VERSION ""

NS_ :

BS_:

BU_: DSAU vHS_M SHVU_RR DPSS AMP ICC RLPSM APSM RWPC RRHV RRPSM CGW_CCU APSS ATS RLHV FPM RDC PSM ASAU

BO_ 2563125249 HU_AMP_E_01_1: 8 CGW_CCU
 SG_ AMP_Beep2Mode : 12|2@1- (1,0) [0|0] ""  Vector__XXX
 SG_ AMP_Beep1Mode : 14|2@1+ (1,0) [0|0] ""  AMP,ATS
 SG_ AMP_MasterBeepVolumeStep : 16|3@1+ (1,0) [0|0] ""  AMP
 SG_ AMP_RrTTSSound : 2|2@1+ (1,0) [0|0] ""  AMP
 SG_ AMP_ASDMode : 21|3@1+ (1,0) [0|0] ""  AMP
 SG_ AMP_ANCMode : 25|2@1+ (1,0) [0|0] ""  AMP
 SG_ AMP_VirtualVenueMode : 32|3@1+ (1,0) [0|0] ""  AMP
 SG_ AMP_QLIMode : 35|3@1+ (1,0) [0|0] ""  AMP
 SG_ AMP_DriverMode : 38|2@1+ (1,0) [0|0] ""  AMP
 SG_ AMP_NaviSound : 4|2@1+ (1,0) [0|0] ""  AMP
 SG_ AMP_VESSMixing : 40|2@1+ (1,0) [0|0] ""  Vector__XXX
 SG_ AMP_VESSMusicOut : 42|2@1+ (1,0) [0|0] ""  Vector__XXX
 SG_ AMP_VoiceGuideTTS : 44|2@1+ (1,0) [0|0] ""  AMP
 SG_ AMP_Beep1KBDMode : 46|2@1+ (1,0) [0|0] ""  AMP
 SG_ AMP_VoiceGuideTTSLevel : 48|3@1+ (1,0) [0|0] ""  AMP
 SG_ AMP_ALTPopUpReq : 54|2@1+ (1,0) [0|0] ""  AMP
 SG_ AMP_TTSSound : 6|2@1+ (1,0) [0|0] ""  AMP
 SG_ AMP_SDVCStep : 9|3@1+ (1,0) [0|0] ""  AMP

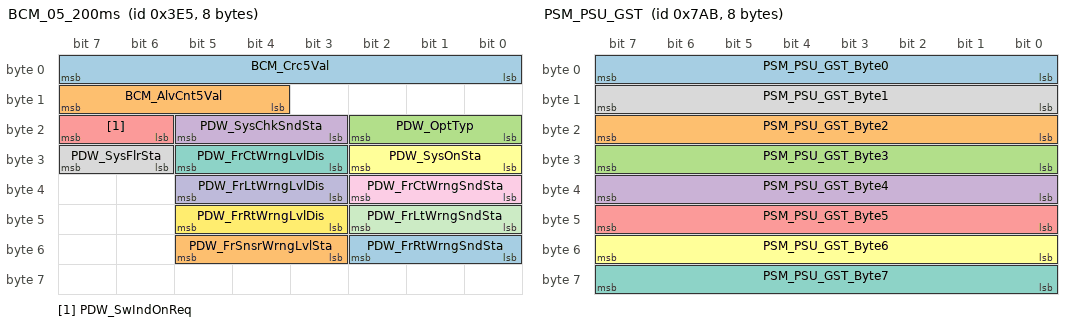
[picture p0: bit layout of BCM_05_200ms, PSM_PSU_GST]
BO_ 997 BCM_05_200ms: 8 CGW_CCU
 SG_ BCM_Crc5Val : 0|8@1+ (1,0) [0|0] ""  Vector__XXX
 SG_ BCM_AlvCnt5Val : 12|4@1+ (1,0) [0|0] ""  Vector__XXX
 SG_ PDW_OptTyp : 16|3@1+ (1,0) [0|0] ""  Vector__XXX
 SG_ PDW_SysChkSndSta : 19|3@1+ (1,0) [0|0] ""  Vector__XXX
 SG_ PDW_SwIndOnReq : 22|2@1+ (1,0) [0|0] ""  Vector__XXX
 SG_ PDW_SysOnSta : 24|3@1+ (1,0) [0|0] ""  Vector__XXX
 SG_ PDW_FrCtWrngLvlDis : 27|3@1+ (1,0) [0|0] ""  Vector__XXX
 SG_ PDW_SysFlrSta : 30|2@1+ (1,0) [0|0] ""  Vector__XXX
 SG_ PDW_FrCtWrngSndSta : 32|3@1+ (1,0) [0|0] ""  AMP
 SG_ PDW_FrLtWrngLvlDis : 35|3@1+ (1,0) [0|0] ""  Vector__XXX
 SG_ PDW_FrLtWrngSndSta : 40|3@1+ (1,0) [0|0] ""  AMP
 SG_ PDW_FrRtWrngLvlDis : 43|3@1+ (1,0) [0|0] ""  Vector__XXX
 SG_ PDW_FrRtWrngSndSta : 48|3@1+ (1,0) [0|0] ""  AMP
 SG_ PDW_FrSnsrWrngLvlSta : 51|3@1+ (1,0) [0|0] ""  Vector__XXX

BO_ 1963 PSM_PSU_GST: 8 PSM
 SG_ PSM_PSU_GST_Byte0 : 0|8@1+ (1,0) [0|0] ""  CGW_CCU
 SG_ PSM_PSU_GST_Byte2 : 16|8@1+ (1,0) [0|0] ""  CGW_CCU
 SG_ PSM_PSU_GST_Byte3 : 24|8@1+ (1,0) [0|0] ""  CGW_CCU
 SG_ PSM_PSU_GST_Byte4 : 32|8@1+ (1,0) [0|0] ""  CGW_CCU
 SG_ PSM_PSU_GST_Byte5 : 40|8@1+ (1,0) [0|0] ""  CGW_CCU
 SG_ PSM_PSU_GST_Byte6 : 48|8@1+ (1,0) [0|0] ""  CGW_CCU
 SG_ PSM_PSU_GST_Byte7 : 56|8@1+ (1,0) [0|0] ""  CGW_CCU
 SG_ PSM_PSU_GST_Byte1 : 8|8@1+ (1,0) [0|0] ""  CGW_CCU

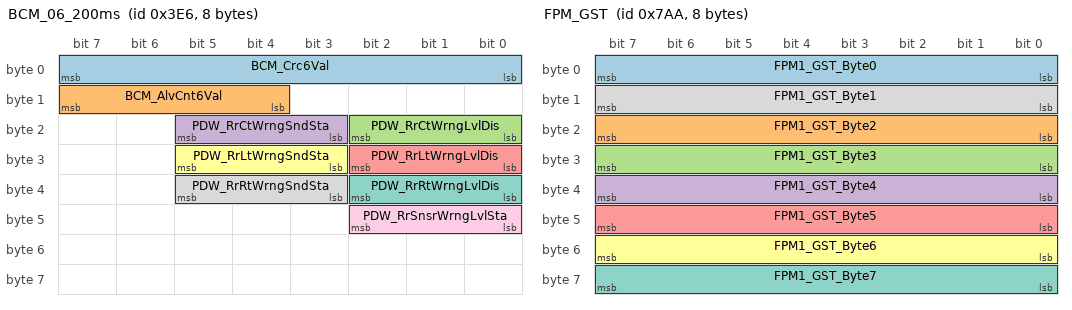
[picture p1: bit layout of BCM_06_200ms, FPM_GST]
BO_ 998 BCM_06_200ms: 8 CGW_CCU
 SG_ BCM_Crc6Val : 0|8@1+ (1,0) [0|0] ""  Vector__XXX
 SG_ BCM_AlvCnt6Val : 12|4@1+ (1,0) [0|0] ""  Vector__XXX
 SG_ PDW_RrCtWrngLvlDis : 16|3@1+ (1,0) [0|0] ""  Vector__XXX
 SG_ PDW_RrCtWrngSndSta : 19|3@1+ (1,0) [0|0] ""  AMP
 SG_ PDW_RrLtWrngLvlDis : 24|3@1+ (1,0) [0|0] ""  Vector__XXX
 SG_ PDW_RrLtWrngSndSta : 27|3@1+ (1,0) [0|0] ""  AMP
 SG_ PDW_RrRtWrngLvlDis : 32|3@1+ (1,0) [0|0] ""  Vector__XXX
 SG_ PDW_RrRtWrngSndSta : 35|3@1+ (1,0) [0|0] ""  AMP
 SG_ PDW_RrSnsrWrngLvlSta : 40|3@1+ (1,0) [0|0] ""  Vector__XXX

BO_ 1962 FPM_GST: 8 vHS_M
 SG_ FPM1_GST_Byte0 : 0|8@1+ (1,0) [0|0] ""  CGW_CCU
 SG_ FPM1_GST_Byte2 : 16|8@1+ (1,0) [0|0] ""  CGW_CCU
 SG_ FPM1_GST_Byte3 : 24|8@1+ (1,0) [0|0] ""  CGW_CCU
 SG_ FPM1_GST_Byte4 : 32|8@1+ (1,0) [0|0] ""  CGW_CCU
 SG_ FPM1_GST_Byte5 : 40|8@1+ (1,0) [0|0] ""  CGW_CCU
 SG_ FPM1_GST_Byte6 : 48|8@1+ (1,0) [0|0] ""  CGW_CCU
 SG_ FPM1_GST_Byte7 : 56|8@1+ (1,0) [0|0] ""  CGW_CCU
 SG_ FPM1_GST_Byte1 : 8|8@1+ (1,0) [0|0] ""  CGW_CCU

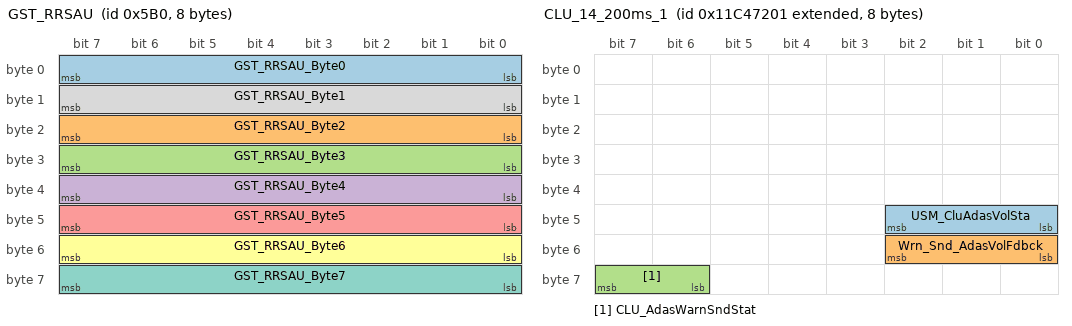
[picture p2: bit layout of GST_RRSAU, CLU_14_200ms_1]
BO_ 1456 GST_RRSAU: 8 CGW_CCU
 SG_ GST_RRSAU_Byte0 : 0|8@1+ (1,0) [0|0] ""  RLPSM,vHS_M
 SG_ GST_RRSAU_Byte2 : 16|8@1+ (1,0) [0|0] ""  RLPSM,vHS_M
 SG_ GST_RRSAU_Byte3 : 24|8@1+ (1,0) [0|0] ""  RLPSM,vHS_M
 SG_ GST_RRSAU_Byte4 : 32|8@1+ (1,0) [0|0] ""  RLPSM,vHS_M
 SG_ GST_RRSAU_Byte5 : 40|8@1+ (1,0) [0|0] ""  RLPSM,vHS_M
 SG_ GST_RRSAU_Byte6 : 48|8@1+ (1,0) [0|0] ""  RLPSM,vHS_M
 SG_ GST_RRSAU_Byte7 : 56|8@1+ (1,0) [0|0] ""  RLPSM,vHS_M
 SG_ GST_RRSAU_Byte1 : 8|8@1+ (1,0) [0|0] ""  RLPSM,vHS_M

BO_ 2445570561 CLU_14_200ms_1: 8 CGW_CCU
 SG_ USM_CluAdasVolSta : 40|3@1+ (1,0) [0|0] ""  AMP
 SG_ Wrn_Snd_AdasVolFdbck : 48|3@1+ (1,0) [0|0] ""  AMP
 SG_ CLU_AdasWarnSndStat : 62|2@1+ (1,0) [0|0] ""  AMP

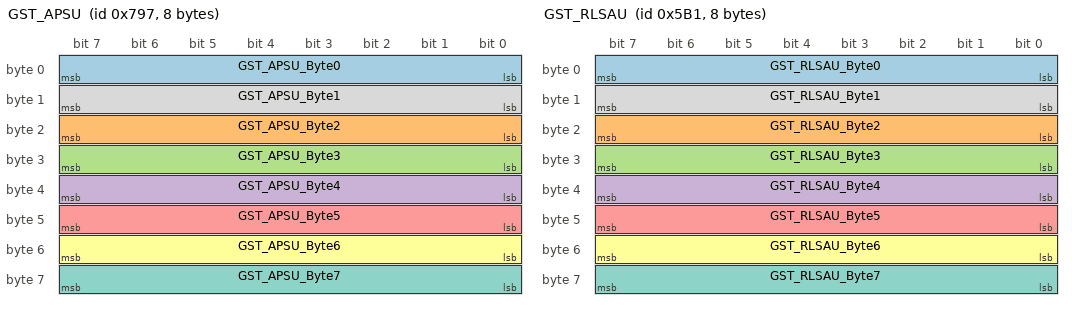
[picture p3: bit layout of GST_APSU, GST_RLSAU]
BO_ 1943 GST_APSU: 8 CGW_CCU
 SG_ GST_APSU_Byte0 : 0|8@1+ (1,0) [0|0] ""  APSM,vHS_M
 SG_ GST_APSU_Byte2 : 16|8@1+ (1,0) [0|0] ""  APSM,vHS_M
 SG_ GST_APSU_Byte3 : 24|8@1+ (1,0) [0|0] ""  APSM,vHS_M
 SG_ GST_APSU_Byte4 : 32|8@1+ (1,0) [0|0] ""  APSM,vHS_M
 SG_ GST_APSU_Byte5 : 40|8@1+ (1,0) [0|0] ""  APSM,vHS_M
 SG_ GST_APSU_Byte6 : 48|8@1+ (1,0) [0|0] ""  APSM,vHS_M
 SG_ GST_APSU_Byte7 : 56|8@1+ (1,0) [0|0] ""  APSM,vHS_M
 SG_ GST_APSU_Byte1 : 8|8@1+ (1,0) [0|0] ""  APSM,vHS_M

BO_ 1457 GST_RLSAU: 8 CGW_CCU
 SG_ GST_RLSAU_Byte0 : 0|8@1+ (1,0) [0|0] ""  RLPSM,vHS_M
 SG_ GST_RLSAU_Byte2 : 16|8@1+ (1,0) [0|0] ""  RLPSM,vHS_M
 SG_ GST_RLSAU_Byte3 : 24|8@1+ (1,0) [0|0] ""  RLPSM,vHS_M
 SG_ GST_RLSAU_Byte4 : 32|8@1+ (1,0) [0|0] ""  RLPSM,vHS_M
 SG_ GST_RLSAU_Byte5 : 40|8@1+ (1,0) [0|0] ""  RLPSM,vHS_M
 SG_ GST_RLSAU_Byte6 : 48|8@1+ (1,0) [0|0] ""  RLPSM,vHS_M
 SG_ GST_RLSAU_Byte7 : 56|8@1+ (1,0) [0|0] ""  RLPSM,vHS_M
 SG_ GST_RLSAU_Byte1 : 8|8@1+ (1,0) [0|0] ""  RLPSM,vHS_M

BO_ 2328014852 DATC_17_200ms_4: 8 CGW_CCU

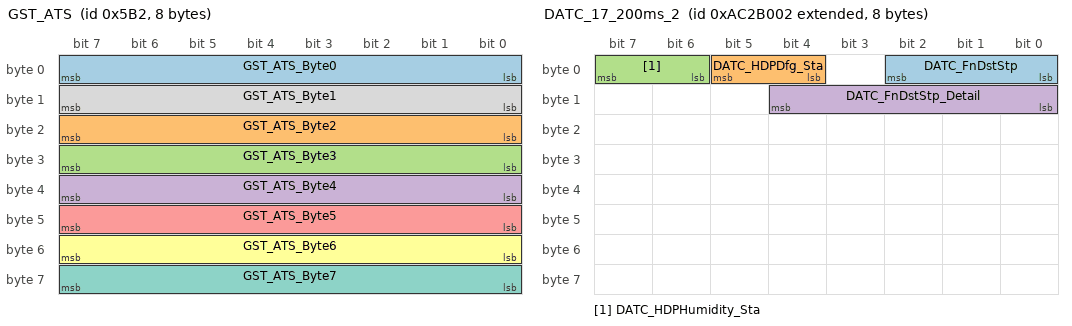
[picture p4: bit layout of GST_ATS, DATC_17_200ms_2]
BO_ 1458 GST_ATS: 8 CGW_CCU
 SG_ GST_ATS_Byte0 : 0|8@1+ (1,0) [0|0] ""  vHS_M,ATS
 SG_ GST_ATS_Byte2 : 16|8@1+ (1,0) [0|0] ""  vHS_M,ATS
 SG_ GST_ATS_Byte3 : 24|8@1+ (1,0) [0|0] ""  vHS_M,ATS
 SG_ GST_ATS_Byte4 : 32|8@1+ (1,0) [0|0] ""  vHS_M,ATS
 SG_ GST_ATS_Byte5 : 40|8@1+ (1,0) [0|0] ""  vHS_M,ATS
 SG_ GST_ATS_Byte6 : 48|8@1+ (1,0) [0|0] ""  vHS_M,ATS
 SG_ GST_ATS_Byte7 : 56|8@1+ (1,0) [0|0] ""  vHS_M,ATS
 SG_ GST_ATS_Byte1 : 8|8@1+ (1,0) [0|0] ""  vHS_M,ATS

BO_ 2328014850 DATC_17_200ms_2: 8 CGW_CCU
 SG_ DATC_FnDstStp : 0|3@1+ (1,0) [0|0] ""  ATS
 SG_ DATC_HDPDfg_Sta : 4|2@1+ (1,0) [0|0] ""  Vector__XXX
 SG_ DATC_HDPHumidity_Sta : 6|2@1+ (1,0) [0|0] ""  Vector__XXX
 SG_ DATC_FnDstStp_Detail : 8|5@1+ (1,0) [0|0] ""  ATS

BO_ 2328014851 DATC_17_200ms_3: 8 CGW_CCU

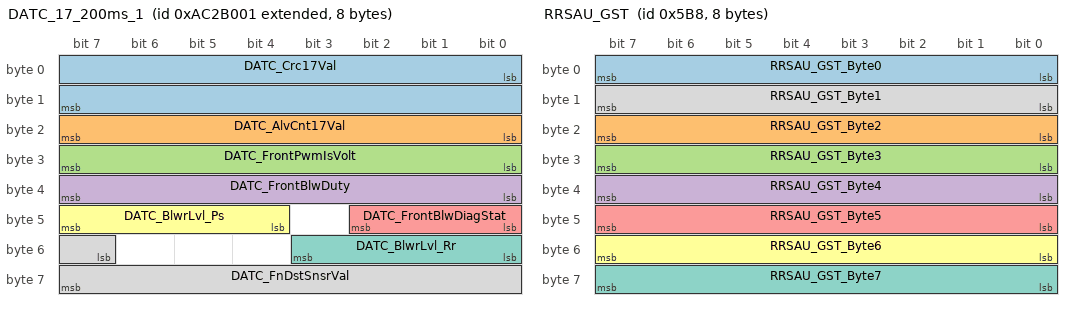
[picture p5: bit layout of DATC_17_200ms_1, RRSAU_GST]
BO_ 2328014849 DATC_17_200ms_1: 8 CGW_CCU
 SG_ DATC_Crc17Val : 0|16@1+ (1,0) [0|0] ""  Vector__XXX
 SG_ DATC_AlvCnt17Val : 16|8@1+ (1,0) [0|0] ""  Vector__XXX
 SG_ DATC_FrontPwmIsVolt : 24|8@1+ (0.02,0) [0|0] "V"  Vector__XXX
 SG_ DATC_FrontBlwDuty : 32|8@1+ (1,0) [0|0] ""  Vector__XXX
 SG_ DATC_FrontBlwDiagStat : 40|3@1+ (1,0) [0|0] ""  Vector__XXX
 SG_ DATC_BlwrLvl_Ps : 44|4@1+ (1,0) [0|0] ""  Vector__XXX
 SG_ DATC_BlwrLvl_Rr : 48|4@1+ (1,0) [0|0] ""  Vector__XXX
 SG_ DATC_FnDstSnsrVal : 55|9@1+ (1,0) [0|0] ""  ATS

BO_ 1464 RRSAU_GST: 8 vHS_M
 SG_ RRSAU_GST_Byte0 : 0|8@1+ (1,0) [0|0] ""  CGW_CCU
 SG_ RRSAU_GST_Byte2 : 16|8@1+ (1,0) [0|0] ""  CGW_CCU
 SG_ RRSAU_GST_Byte3 : 24|8@1+ (1,0) [0|0] ""  CGW_CCU
 SG_ RRSAU_GST_Byte4 : 32|8@1+ (1,0) [0|0] ""  CGW_CCU
 SG_ RRSAU_GST_Byte5 : 40|8@1+ (1,0) [0|0] ""  CGW_CCU
 SG_ RRSAU_GST_Byte6 : 48|8@1+ (1,0) [0|0] ""  CGW_CCU
 SG_ RRSAU_GST_Byte7 : 56|8@1+ (1,0) [0|0] ""  CGW_CCU
 SG_ RRSAU_GST_Byte1 : 8|8@1+ (1,0) [0|0] ""  CGW_CCU

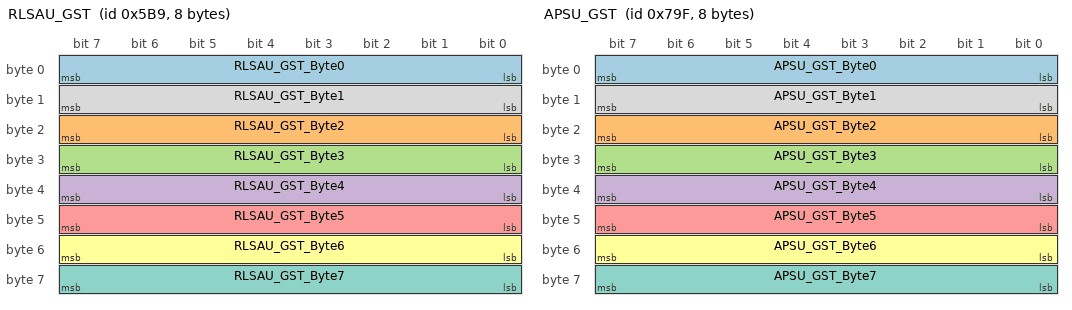
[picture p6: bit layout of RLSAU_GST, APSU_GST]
BO_ 1465 RLSAU_GST: 8 RLPSM
 SG_ RLSAU_GST_Byte0 : 0|8@1+ (1,0) [0|0] ""  CGW_CCU
 SG_ RLSAU_GST_Byte2 : 16|8@1+ (1,0) [0|0] ""  CGW_CCU
 SG_ RLSAU_GST_Byte3 : 24|8@1+ (1,0) [0|0] ""  CGW_CCU
 SG_ RLSAU_GST_Byte4 : 32|8@1+ (1,0) [0|0] ""  CGW_CCU
 SG_ RLSAU_GST_Byte5 : 40|8@1+ (1,0) [0|0] ""  CGW_CCU
 SG_ RLSAU_GST_Byte6 : 48|8@1+ (1,0) [0|0] ""  CGW_CCU
 SG_ RLSAU_GST_Byte7 : 56|8@1+ (1,0) [0|0] ""  CGW_CCU
 SG_ RLSAU_GST_Byte1 : 8|8@1+ (1,0) [0|0] ""  CGW_CCU

BO_ 1951 APSU_GST: 8 APSM
 SG_ APSU_GST_Byte0 : 0|8@1+ (1,0) [0|0] ""  CGW_CCU
 SG_ APSU_GST_Byte2 : 16|8@1+ (1,0) [0|0] ""  CGW_CCU
 SG_ APSU_GST_Byte3 : 24|8@1+ (1,0) [0|0] ""  CGW_CCU
 SG_ APSU_GST_Byte4 : 32|8@1+ (1,0) [0|0] ""  CGW_CCU
 SG_ APSU_GST_Byte5 : 40|8@1+ (1,0) [0|0] ""  CGW_CCU
 SG_ APSU_GST_Byte6 : 48|8@1+ (1,0) [0|0] ""  CGW_CCU
 SG_ APSU_GST_Byte7 : 56|8@1+ (1,0) [0|0] ""  CGW_CCU
 SG_ APSU_GST_Byte1 : 8|8@1+ (1,0) [0|0] ""  CGW_CCU

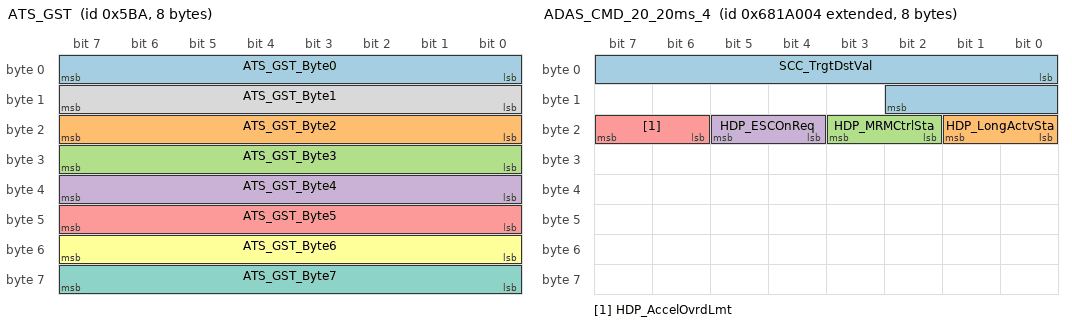
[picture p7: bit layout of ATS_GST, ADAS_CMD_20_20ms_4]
BO_ 1466 ATS_GST: 8 vHS_M
 SG_ ATS_GST_Byte0 : 0|8@1+ (1,0) [0|0] ""  CGW_CCU
 SG_ ATS_GST_Byte2 : 16|8@1+ (1,0) [0|0] ""  CGW_CCU
 SG_ ATS_GST_Byte3 : 24|8@1+ (1,0) [0|0] ""  CGW_CCU
 SG_ ATS_GST_Byte4 : 32|8@1+ (1,0) [0|0] ""  CGW_CCU
 SG_ ATS_GST_Byte5 : 40|8@1+ (1,0) [0|0] ""  CGW_CCU
 SG_ ATS_GST_Byte6 : 48|8@1+ (1,0) [0|0] ""  CGW_CCU
 SG_ ATS_GST_Byte7 : 56|8@1+ (1,0) [0|0] ""  CGW_CCU
 SG_ ATS_GST_Byte1 : 8|8@1+ (1,0) [0|0] ""  CGW_CCU

BO_ 981 APSS_01_200ms: 8 APSS
 SG_ APSS_StSldFwdMvBtn : 16|2@1+ (1,0) [0|0] ""  APSM,RRPSM,CGW_CCU
 SG_ APSS_StSldBwdMvBtn : 18|2@1+ (1,0) [0|0] ""  APSM,RRPSM,CGW_CCU
 SG_ APSS_StRclFwdMvBtn : 20|2@1+ (1,0) [0|0] ""  APSM,RRPSM,CGW_CCU
 SG_ APSS_StRclBwdMvBtn : 22|2@1+ (1,0) [0|0] ""  APSM,RRPSM,CGW_CCU
 SG_ APSS_StHgtUpMvBtn : 24|2@1+ (1,0) [0|0] ""  APSM,RRPSM,CGW_CCU
 SG_ APSS_StHgtDnMvBtn : 26|2@1+ (1,0) [0|0] ""  APSM,RRPSM,CGW_CCU
 SG_ APSS_StTltUpMvBtn : 28|2@1+ (1,0) [0|0] ""  APSM,CGW_CCU
 SG_ APSS_StTltDnMvBtn : 30|2@1+ (1,0) [0|0] ""  APSM,CGW_CCU
 SG_ APSS_StHRestUpMvBtn : 32|2@1+ (1,0) [0|0] ""  APSM,CGW_CCU
 SG_ APSS_StHRestDnMvBtn : 34|2@1+ (1,0) [0|0] ""  APSM,CGW_CCU
 SG_ APSS_StHRestFwdMvBtn : 36|2@1+ (1,0) [0|0] ""  APSM,CGW_CCU
 SG_ APSS_StHRestBwdMvBtn : 38|2@1+ (1,0) [0|0] ""  APSM,CGW_CCU
 SG_ APSS_StLegUpMvBtn : 40|2@1+ (1,0) [0|0] ""  Vector__XXX
 SG_ APSS_StLegDnMvBtn : 42|2@1+ (1,0) [0|0] ""  Vector__XXX
 SG_ APSS_StRlxModeBtn : 44|2@1+ (1,0) [0|0] ""  Vector__XXX
 SG_ APSS_StRlxReturnBtn : 46|2@1+ (1,0) [0|0] ""  Vector__XXX
 SG_ APSS_StRlxTltUpMvBtn : 48|2@1+ (1,0) [0|0] ""  Vector__XXX
 SG_ APSS_StRlxTltDnMvBtn : 50|2@1+ (1,0) [0|0] ""  Vector__XXX

BO_ 2256642052 ADAS_CMD_20_20ms_4: 8 CGW_CCU
 SG_ SCC_TrgtDstVal : 0|11@1+ (0.1,0) [0|0] "m"  Vector__XXX
 SG_ HDP_LongActvSta : 16|2@1+ (1,0) [0|0] ""  Vector__XXX
 SG_ HDP_MRMCtrlSta : 18|2@1+ (1,0) [0|0] ""  Vector__XXX
 SG_ HDP_ESCOnReq : 20|2@1+ (1,0) [0|0] ""  Vector__XXX
 SG_ HDP_AccelOvrdLmt : 22|2@1+ (1,0) [0|0] ""  Vector__XXX

BO_ 2441372929 DATC_14_00ms_1: 8 CGW_CCU
 SG_ DATC_Crc14Val : 0|16@1+ (1,0) [0|0] ""  Vector__XXX
 SG_ DATC_AlvCnt14Val : 16|8@1+ (1,0) [0|0] ""  Vector__XXX
 SG_ DATC_Beep1Sound : 50|2@1+ (1,0) [0|0] ""  AMP

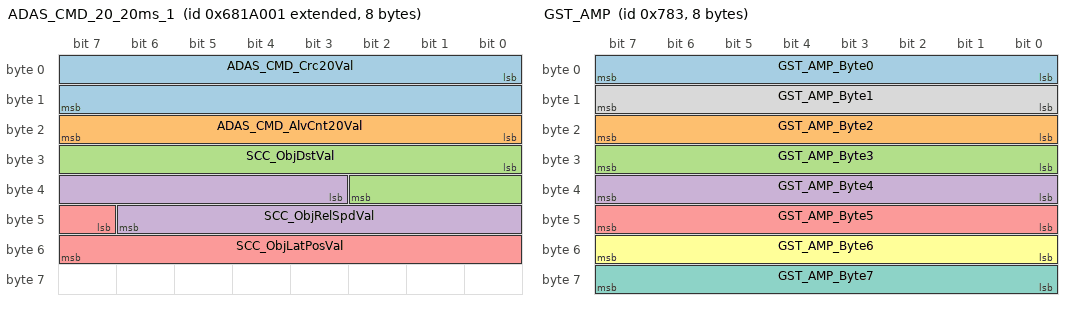
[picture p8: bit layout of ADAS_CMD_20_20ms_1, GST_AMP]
BO_ 2256642049 ADAS_CMD_20_20ms_1: 8 CGW_CCU
 SG_ ADAS_CMD_Crc20Val : 0|16@1+ (1,0) [0|0] ""  Vector__XXX
 SG_ ADAS_CMD_AlvCnt20Val : 16|8@1+ (1,0) [0|0] ""  Vector__XXX
 SG_ SCC_ObjDstVal : 24|11@1+ (0.1,0) [0|0] "m"  Vector__XXX
 SG_ SCC_ObjRelSpdVal : 35|12@1+ (0.1,-170) [0|0] "m/s"  Vector__XXX
 SG_ SCC_ObjLatPosVal : 47|9@1+ (0.1,-20) [0|0] "m"  Vector__XXX

BO_ 1923 GST_AMP: 8 CGW_CCU
 SG_ GST_AMP_Byte0 : 0|8@1+ (1,0) [0|0] ""  AMP,vHS_M
 SG_ GST_AMP_Byte2 : 16|8@1+ (1,0) [0|0] ""  AMP,vHS_M
 SG_ GST_AMP_Byte3 : 24|8@1+ (1,0) [0|0] ""  AMP,vHS_M
 SG_ GST_AMP_Byte4 : 32|8@1+ (1,0) [0|0] ""  AMP,vHS_M
 SG_ GST_AMP_Byte5 : 40|8@1+ (1,0) [0|0] ""  AMP,vHS_M
 SG_ GST_AMP_Byte6 : 48|8@1+ (1,0) [0|0] ""  AMP,vHS_M
 SG_ GST_AMP_Byte7 : 56|8@1+ (1,0) [0|0] ""  AMP,vHS_M
 SG_ GST_AMP_Byte1 : 8|8@1+ (1,0) [0|0] ""  AMP,vHS_M

BO_ 2458167553 HU_USM_E_02_1: 8 CGW_CCU
 SG_ C_PTGMNValueSet : 0|2@1+ (1,0) [0|0] ""  Vector__XXX
 SG_ CF_AVN_PSMNValueSet : 10|3@1+ (1,0) [0|0] ""  PSM
 SG_ C_HfreeTrunkTgNValueSet : 13|3@1+ (1,0) [0|0] ""  Vector__XXX
 SG_ CF_AVN_TrfChgSet : 17|2@1+ (1,0) [0|0] ""  Vector__XXX
 SG_ CF_AVN_SCMNValueSet : 19|2@1+ (1,0) [0|0] ""  Vector__XXX
 SG_ CF_AVN_ADrUNValueSet : 2|3@1+ (1,0) [0|0] ""  Vector__XXX
 SG_ CF_AVN_OTTurnNValueSet : 21|3@1+ (1,0) [0|0] ""  Vector__XXX
 SG_ CF_Gway_WPCNValueSet : 24|2@1+ (1,0) [0|0] ""  Vector__XXX
 SG_ C_AVN_RearWiperNValueSet : 26|2@1+ (1,0) [0|0] ""  Vector__XXX
 SG_ C_UnlockWelocomeNValueSet : 28|2@1+ (1,0) [0|0] ""  Vector__XXX
 SG_ C_SmartWelocomeNValueSet : 30|2@1+ (1,0) [0|0] ""  Vector__XXX
 SG_ CF_AVN_PTGSpeedNValueSet : 32|2@1+ (1,0) [0|0] ""  Vector__XXX
 SG_ CR_Datc_DRSeatWheel_USM_Set : 34|2@1+ (1,0) [0|0] ""  Vector__XXX
 SG_ CF_AVN_SequencialLampNValue : 36|2@1+ (1,0) [0|0] ""  Vector__XXX
 SG_ CF_AVN_TTUnlockNValueSet : 38|2@1+ (1,0) [0|0] ""  Vector__XXX
 SG_ CF_Gway_RWPCNValueSet : 40|2@1+ (1,0) [0|0] ""  RWPC
 SG_ CF_Avn_BolsterNValueSet : 42|2@1+ (1,0) [0|0] ""  Vector__XXX
 SG_ C_PSDNValueSet : 44|2@1+ (1,0) [0|0] ""  Vector__XXX
 SG_ C_StrWheelAutoHeatNValueSet : 46|2@1+ (1,0) [0|0] ""  Vector__XXX
 SG_ CF_Avn_HAPTICWARNINGNValueSet : 49|3@1+ (1,0) [0|0] ""  Vector__XXX
 SG_ CF_AVN_ADrLNValueSet : 5|3@1+ (1,0) [0|0] ""  Vector__XXX
 SG_ CR_Datc_DRSeatHeat_USM_Set : 52|2@1+ (1,0) [0|0] ""  Vector__XXX
 SG_ C_WALNValueSet : 54|2@1+ (1,0) [0|0] ""  Vector__XXX
 SG_ C_ApprUnlockNValue : 56|2@1+ (1,0) [0|0] ""  Vector__XXX
 SG_ CF_AVN_SEW_NEWNValueSet : 58|2@1+ (1,0) [0|0] ""  Vector__XXX
 SG_ CF_AVN_SEA_NEWNValueSet : 60|2@1+ (1,0) [0|0] ""  Vector__XXX
 SG_ CF_AVN_TunnelWindowNvalueSet : 62|2@1+ (1,0) [0|0] ""  Vector__XXX
 SG_ CF_AVN_EscortHLNValueSet : 8|2@1+ (1,0) [0|0] ""  Vector__XXX

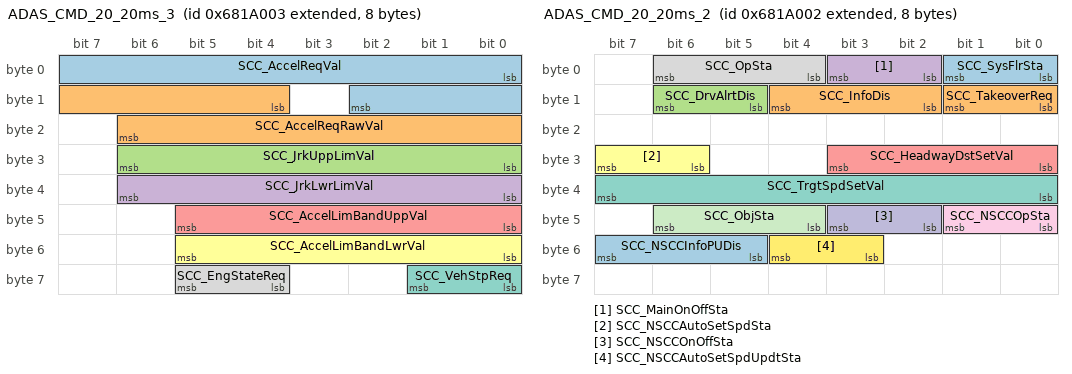
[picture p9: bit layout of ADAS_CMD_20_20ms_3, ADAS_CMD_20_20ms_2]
BO_ 2256642051 ADAS_CMD_20_20ms_3: 8 CGW_CCU
 SG_ SCC_AccelReqVal : 0|11@1+ (0.01,-10.23) [0|0] "m/s^2"  Vector__XXX
 SG_ SCC_AccelReqRawVal : 12|11@1+ (0.01,-10.23) [0|0] "m/s^2"  Vector__XXX
 SG_ SCC_JrkUppLimVal : 24|7@1+ (0.1,0) [0|0] "m/s^3"  Vector__XXX
 SG_ SCC_JrkLwrLimVal : 32|7@1+ (0.1,0) [0|0] "m/s^3"  Vector__XXX
 SG_ SCC_AccelLimBandUppVal : 40|6@1+ (0.02,0) [0|0] "m/s^2"  Vector__XXX
 SG_ SCC_AccelLimBandLwrVal : 48|6@1+ (0.02,0) [0|0] "m/s^2"  Vector__XXX
 SG_ SCC_VehStpReq : 56|2@1+ (1,0) [0|0] ""  Vector__XXX
 SG_ SCC_EngStateReq : 60|2@1+ (1,0) [0|0] ""  Vector__XXX

BO_ 2256642050 ADAS_CMD_20_20ms_2: 8 CGW_CCU
 SG_ SCC_SysFlrSta : 0|2@1+ (1,0) [0|0] ""  Vector__XXX
 SG_ SCC_InfoDis : 10|3@1+ (1,0) [0|0] ""  Vector__XXX
 SG_ SCC_DrvAlrtDis : 13|2@1+ (1,0) [0|0] ""  Vector__XXX
 SG_ SCC_MainOnOffSta : 2|2@1+ (1,0) [0|0] ""  Vector__XXX
 SG_ SCC_HeadwayDstSetVal : 24|4@1+ (1,0) [0|0] ""  Vector__XXX
 SG_ SCC_NSCCAutoSetSpdSta : 30|2@1+ (1,0) [0|0] ""  Vector__XXX
 SG_ SCC_TrgtSpdSetVal : 32|8@1+ (1,0) [0|0] "km/h or MPH"  Vector__XXX
 SG_ SCC_OpSta : 4|3@1+ (1,0) [0|0] ""  Vector__XXX
 SG_ SCC_NSCCOpSta : 40|2@1+ (1,0) [0|0] ""  Vector__XXX
 SG_ SCC_NSCCOnOffSta : 42|2@1+ (1,0) [0|0] ""  Vector__XXX
 SG_ SCC_ObjSta : 44|3@1+ (1,0) [0|0] ""  Vector__XXX
 SG_ SCC_NSCCAutoSetSpdUpdtSta : 51|2@1+ (1,0) [0|0] ""  Vector__XXX
 SG_ SCC_NSCCInfoPUDis : 53|3@1+ (1,0) [0|0] ""  Vector__XXX
 SG_ SCC_TakeoverReq : 8|2@1+ (1,0) [0|0] ""  AMP

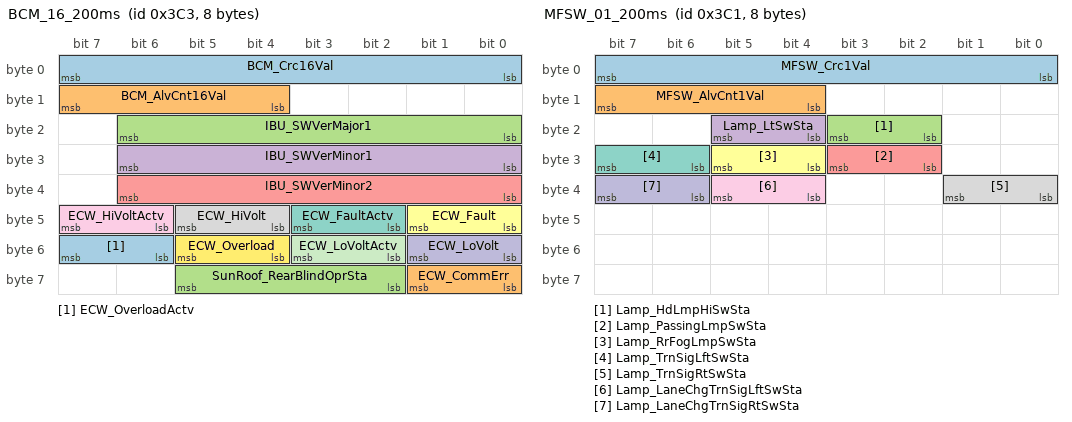
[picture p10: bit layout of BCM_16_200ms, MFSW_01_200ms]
BO_ 963 BCM_16_200ms: 8 CGW_CCU
 SG_ BCM_Crc16Val : 0|8@1+ (1,0) [0|0] ""  Vector__XXX
 SG_ BCM_AlvCnt16Val : 12|4@1+ (1,0) [0|0] ""  Vector__XXX
 SG_ IBU_SWVerMajor1 : 16|7@1+ (1,0) [0|0] ""  Vector__XXX
 SG_ IBU_SWVerMinor1 : 24|7@1+ (1,0) [0|0] ""  Vector__XXX
 SG_ IBU_SWVerMinor2 : 32|7@1+ (1,0) [0|0] ""  Vector__XXX
 SG_ ECW_Fault : 40|2@1+ (1,0) [0|0] ""  Vector__XXX
 SG_ ECW_FaultActv : 42|2@1+ (1,0) [0|0] ""  Vector__XXX
 SG_ ECW_HiVolt : 44|2@1+ (1,0) [0|0] ""  Vector__XXX
 SG_ ECW_HiVoltActv : 46|2@1+ (1,0) [0|0] ""  Vector__XXX
 SG_ ECW_LoVolt : 48|2@1+ (1,0) [0|0] ""  Vector__XXX
 SG_ ECW_LoVoltActv : 50|2@1+ (1,0) [0|0] ""  Vector__XXX
 SG_ ECW_Overload : 52|2@1+ (1,0) [0|0] ""  Vector__XXX
 SG_ ECW_OverloadActv : 54|2@1+ (1,0) [0|0] ""  Vector__XXX
 SG_ ECW_CommErr : 56|2@1+ (1,0) [0|0] ""  Vector__XXX
 SG_ SunRoof_RearBlindOprSta : 58|4@1+ (1,0) [0|0] ""  ATS

BO_ 961 MFSW_01_200ms: 8 CGW_CCU
 SG_ MFSW_Crc1Val : 0|8@1+ (1,0) [0|0] ""  Vector__XXX
 SG_ MFSW_AlvCnt1Val : 12|4@1+ (1,0) [0|0] ""  Vector__XXX
 SG_ Lamp_HdLmpHiSwSta : 18|2@1+ (1,0) [0|0] ""  Vector__XXX
 SG_ Lamp_LtSwSta : 20|2@1+ (1,0) [0|0] ""  Vector__XXX
 SG_ Lamp_PassingLmpSwSta : 26|2@1+ (1,0) [0|0] ""  Vector__XXX
 SG_ Lamp_RrFogLmpSwSta : 28|2@1+ (1,0) [0|0] ""  Vector__XXX
 SG_ Lamp_TrnSigLftSwSta : 30|2@1+ (1,0) [0|0] ""  ICC
 SG_ Lamp_TrnSigRtSwSta : 32|2@1+ (1,0) [0|0] ""  ICC
 SG_ Lamp_LaneChgTrnSigLftSwSta : 36|2@1+ (1,0) [0|0] ""  Vector__XXX
 SG_ Lamp_LaneChgTrnSigRtSwSta : 38|2@1+ (1,0) [0|0] ""  Vector__XXX

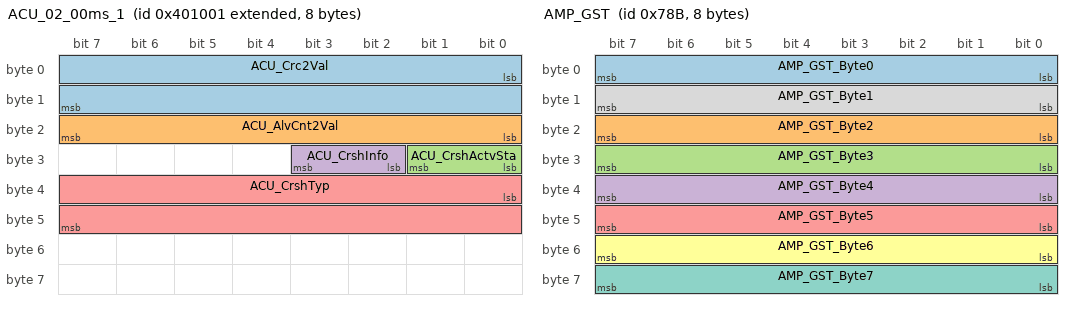
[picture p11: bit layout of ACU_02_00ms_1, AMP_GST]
BO_ 2151682049 ACU_02_00ms_1: 8 CGW_CCU
 SG_ ACU_Crc2Val : 0|16@1+ (1,0) [0|0] ""  Vector__XXX
 SG_ ACU_AlvCnt2Val : 16|8@1+ (1,0) [0|0] ""  Vector__XXX
 SG_ ACU_CrshActvSta : 24|2@1+ (1,0) [0|0] ""  APSM,RLPSM,RRPSM
 SG_ ACU_CrshInfo : 26|2@1+ (1,0) [0|0] ""  Vector__XXX
 SG_ ACU_CrshTyp : 32|16@1+ (1,0) [0|0] ""  Vector__XXX

BO_ 1931 AMP_GST: 8 AMP
 SG_ AMP_GST_Byte0 : 0|8@1+ (1,0) [0|0] ""  CGW_CCU
 SG_ AMP_GST_Byte2 : 16|8@1+ (1,0) [0|0] ""  CGW_CCU
 SG_ AMP_GST_Byte3 : 24|8@1+ (1,0) [0|0] ""  CGW_CCU
 SG_ AMP_GST_Byte4 : 32|8@1+ (1,0) [0|0] ""  CGW_CCU
 SG_ AMP_GST_Byte5 : 40|8@1+ (1,0) [0|0] ""  CGW_CCU
 SG_ AMP_GST_Byte6 : 48|8@1+ (1,0) [0|0] ""  CGW_CCU
 SG_ AMP_GST_Byte7 : 56|8@1+ (1,0) [0|0] ""  CGW_CCU
 SG_ AMP_GST_Byte1 : 8|8@1+ (1,0) [0|0] ""  CGW_CCU

BO_ 2563125761 HU_AMP_E_03_1: 8 CGW_CCU
 SG_ AMP_LogSnapshot : 0|2@1+ (1,0) [0|0] ""  AMP
 SG_ AMP_VersionReq : 22|2@1+ (1,0) [0|0] ""  AMP

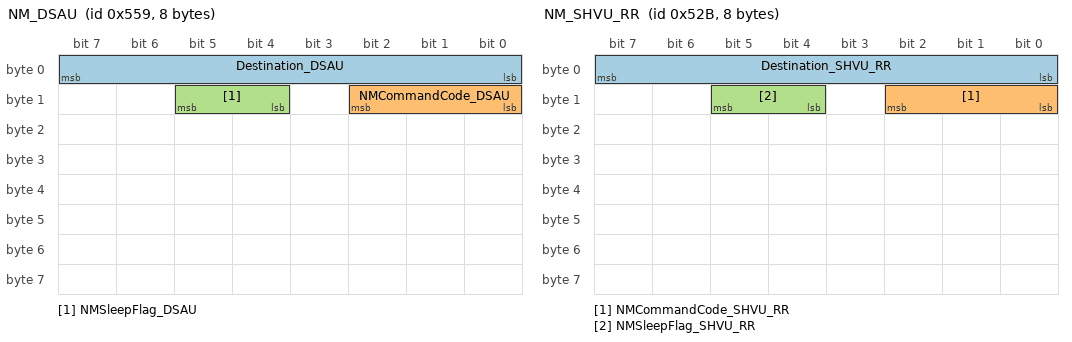
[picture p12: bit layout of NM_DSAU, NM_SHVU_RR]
BO_ 1369 NM_DSAU: 8 DSAU
 SG_ Destination_DSAU : 0|8@1+ (1,0) [0|0] ""  vHS_M,SHVU_RR,DPSS,AMP,ICC,RLPSM,APSM,RWPC,RRHV,RRPSM,CGW_CCU,APSS,ATS,RLHV,FPM,RDC,PSM,ASAU
 SG_ NMCommandCode_DSAU : 8|3@1+ (1,0) [0|0] ""  vHS_M,SHVU_RR,DPSS,AMP,ICC,RLPSM,APSM,RWPC,RRHV,RRPSM,CGW_CCU,APSS,ATS,RLHV,FPM,RDC,PSM,ASAU
 SG_ NMSleepFlag_DSAU : 12|2@1+ (1,0) [0|0] ""  vHS_M,SHVU_RR,DPSS,AMP,ICC,RLPSM,APSM,RWPC,RRHV,RRPSM,CGW_CCU,APSS,ATS,RLHV,FPM,RDC,PSM,ASAU

BO_ 1323 NM_SHVU_RR: 8 SHVU_RR
 SG_ Destination_SHVU_RR : 0|8@1+ (1,0) [0|0] ""  DSAU,vHS_M,DPSS,AMP,ICC,RLPSM,APSM,RWPC,RRHV,RRPSM,CGW_CCU,APSS,ATS,RLHV,FPM,RDC,PSM,ASAU
 SG_ NMCommandCode_SHVU_RR : 8|3@1+ (1,0) [0|0] ""  DSAU,vHS_M,DPSS,AMP,ICC,RLPSM,APSM,RWPC,RRHV,RRPSM,CGW_CCU,APSS,ATS,RLHV,FPM,RDC,PSM,ASAU
 SG_ NMSleepFlag_SHVU_RR : 12|2@1+ (1,0) [0|0] ""  DSAU,vHS_M,DPSS,AMP,ICC,RLPSM,APSM,RWPC,RRHV,RRPSM,CGW_CCU,APSS,ATS,RLHV,FPM,RDC,PSM,ASAU

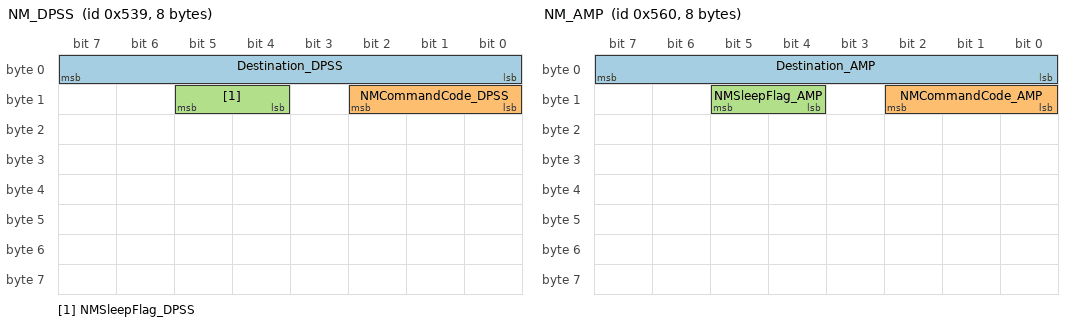
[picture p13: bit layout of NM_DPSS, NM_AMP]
BO_ 1337 NM_DPSS: 8 DPSS
 SG_ Destination_DPSS : 0|8@1+ (1,0) [0|0] ""  DSAU,vHS_M,SHVU_RR,AMP,ICC,RLPSM,APSM,RWPC,RRHV,RRPSM,CGW_CCU,APSS,ATS,RLHV,FPM,RDC,PSM,ASAU
 SG_ NMCommandCode_DPSS : 8|3@1+ (1,0) [0|0] ""  DSAU,vHS_M,SHVU_RR,AMP,ICC,RLPSM,APSM,RWPC,RRHV,RRPSM,CGW_CCU,APSS,ATS,RLHV,FPM,RDC,PSM,ASAU
 SG_ NMSleepFlag_DPSS : 12|2@1+ (1,0) [0|0] ""  DSAU,vHS_M,SHVU_RR,AMP,ICC,RLPSM,APSM,RWPC,RRHV,RRPSM,CGW_CCU,APSS,ATS,RLHV,FPM,RDC,PSM,ASAU

BO_ 1376 NM_AMP: 8 AMP
 SG_ Destination_AMP : 0|8@1+ (1,0) [0|0] ""  DSAU,vHS_M,SHVU_RR,DPSS,ICC,RLPSM,APSM,RWPC,RRHV,RRPSM,CGW_CCU,APSS,ATS,RLHV,FPM,RDC,PSM,ASAU
 SG_ NMCommandCode_AMP : 8|3@1+ (1,0) [0|0] ""  DSAU,vHS_M,SHVU_RR,DPSS,ICC,RLPSM,APSM,RWPC,RRHV,RRPSM,CGW_CCU,APSS,ATS,RLHV,FPM,RDC,PSM,ASAU
 SG_ NMSleepFlag_AMP : 12|2@1+ (1,0) [0|0] ""  DSAU,vHS_M,SHVU_RR,DPSS,ICC,RLPSM,APSM,RWPC,RRHV,RRPSM,CGW_CCU,APSS,ATS,RLHV,FPM,RDC,PSM,ASAU

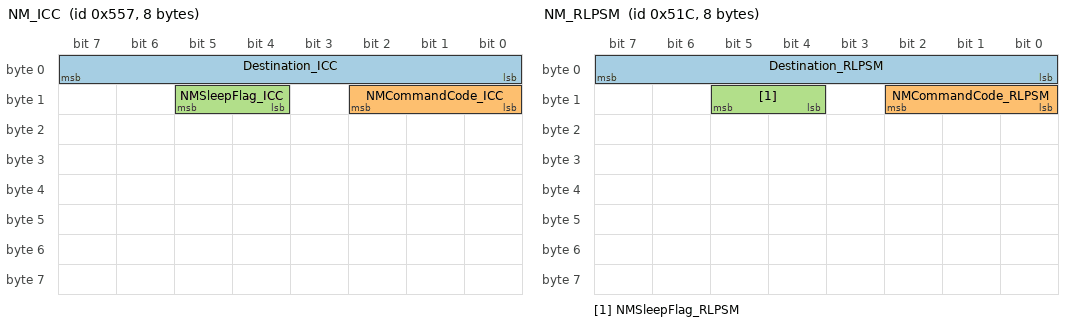
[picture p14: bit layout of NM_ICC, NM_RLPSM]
BO_ 1367 NM_ICC: 8 ICC
 SG_ Destination_ICC : 0|8@1+ (1,0) [0|0] ""  DSAU,vHS_M,SHVU_RR,DPSS,AMP,RLPSM,APSM,RWPC,RRHV,RRPSM,CGW_CCU,APSS,ATS,RLHV,FPM,RDC,PSM,ASAU
 SG_ NMCommandCode_ICC : 8|3@1+ (1,0) [0|0] ""  DSAU,vHS_M,SHVU_RR,DPSS,AMP,RLPSM,APSM,RWPC,RRHV,RRPSM,CGW_CCU,APSS,ATS,RLHV,FPM,RDC,PSM,ASAU
 SG_ NMSleepFlag_ICC : 12|2@1+ (1,0) [0|0] ""  DSAU,vHS_M,SHVU_RR,DPSS,AMP,RLPSM,APSM,RWPC,RRHV,RRPSM,CGW_CCU,APSS,ATS,RLHV,FPM,RDC,PSM,ASAU

BO_ 1308 NM_RLPSM: 8 RLPSM
 SG_ Destination_RLPSM : 0|8@1+ (1,0) [0|0] ""  DSAU,vHS_M,SHVU_RR,DPSS,AMP,ICC,APSM,RWPC,RRHV,RRPSM,CGW_CCU,APSS,ATS,RLHV,FPM,RDC,PSM,ASAU
 SG_ NMCommandCode_RLPSM : 8|3@1+ (1,0) [0|0] ""  DSAU,vHS_M,SHVU_RR,DPSS,AMP,ICC,APSM,RWPC,RRHV,RRPSM,CGW_CCU,APSS,ATS,RLHV,FPM,RDC,PSM,ASAU
 SG_ NMSleepFlag_RLPSM : 12|2@1+ (1,0) [0|0] ""  DSAU,vHS_M,SHVU_RR,DPSS,AMP,ICC,APSM,RWPC,RRHV,RRPSM,CGW_CCU,APSS,ATS,RLHV,FPM,RDC,PSM,ASAU

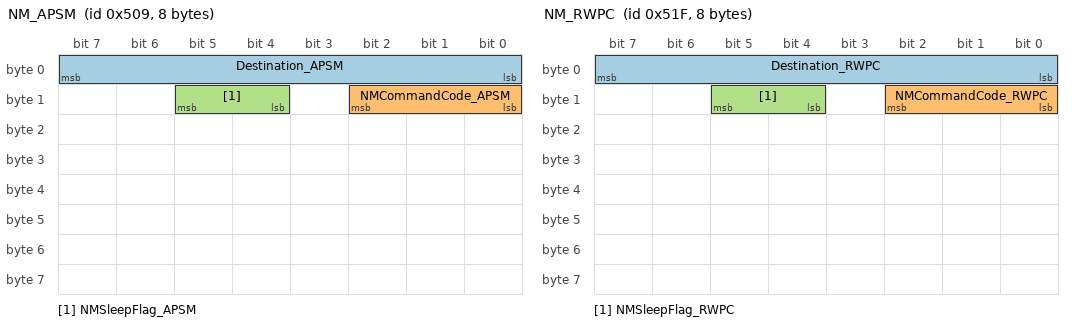
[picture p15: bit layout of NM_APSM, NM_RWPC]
BO_ 1289 NM_APSM: 8 APSM
 SG_ Destination_APSM : 0|8@1+ (1,0) [0|0] ""  DSAU,vHS_M,SHVU_RR,DPSS,AMP,ICC,RLPSM,RWPC,RRHV,RRPSM,CGW_CCU,APSS,ATS,RLHV,FPM,RDC,PSM,ASAU
 SG_ NMCommandCode_APSM : 8|3@1+ (1,0) [0|0] ""  DSAU,vHS_M,SHVU_RR,DPSS,AMP,ICC,RLPSM,RWPC,RRHV,RRPSM,CGW_CCU,APSS,ATS,RLHV,FPM,RDC,PSM,ASAU
 SG_ NMSleepFlag_APSM : 12|2@1+ (1,0) [0|0] ""  DSAU,vHS_M,SHVU_RR,DPSS,AMP,ICC,RLPSM,RWPC,RRHV,RRPSM,CGW_CCU,APSS,ATS,RLHV,FPM,RDC,PSM,ASAU

BO_ 1311 NM_RWPC: 8 RWPC
 SG_ Destination_RWPC : 0|8@1+ (1,0) [0|0] ""  DSAU,vHS_M,SHVU_RR,DPSS,AMP,ICC,RLPSM,APSM,RRHV,RRPSM,CGW_CCU,APSS,ATS,RLHV,FPM,RDC,PSM,ASAU
 SG_ NMCommandCode_RWPC : 8|3@1+ (1,0) [0|0] ""  DSAU,vHS_M,SHVU_RR,DPSS,AMP,ICC,RLPSM,APSM,RRHV,RRPSM,CGW_CCU,APSS,ATS,RLHV,FPM,RDC,PSM,ASAU
 SG_ NMSleepFlag_RWPC : 12|2@1+ (1,0) [0|0] ""  DSAU,vHS_M,SHVU_RR,DPSS,AMP,ICC,RLPSM,APSM,RRHV,RRPSM,CGW_CCU,APSS,ATS,RLHV,FPM,RDC,PSM,ASAU

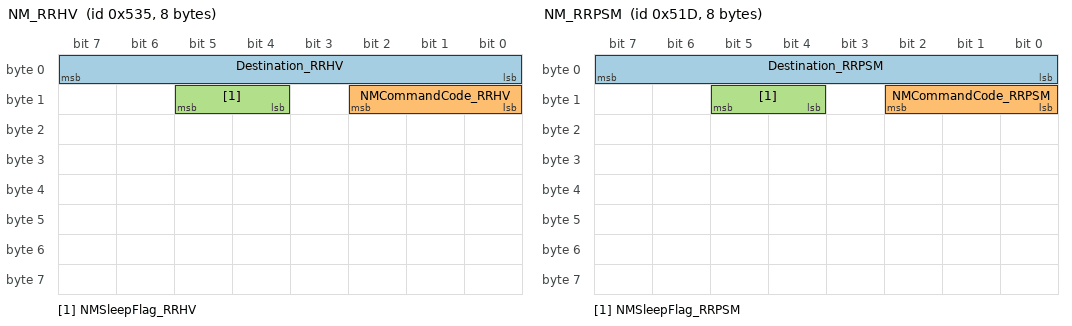
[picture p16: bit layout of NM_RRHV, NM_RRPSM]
BO_ 1333 NM_RRHV: 8 RRHV
 SG_ Destination_RRHV : 0|8@1+ (1,0) [0|0] ""  DSAU,vHS_M,SHVU_RR,DPSS,AMP,ICC,RLPSM,APSM,RWPC,RRPSM,CGW_CCU,APSS,ATS,RLHV,FPM,RDC,PSM,ASAU
 SG_ NMCommandCode_RRHV : 8|3@1+ (1,0) [0|0] ""  DSAU,vHS_M,SHVU_RR,DPSS,AMP,ICC,RLPSM,APSM,RWPC,RRPSM,CGW_CCU,APSS,ATS,RLHV,FPM,RDC,PSM,ASAU
 SG_ NMSleepFlag_RRHV : 12|2@1+ (1,0) [0|0] ""  DSAU,vHS_M,SHVU_RR,DPSS,AMP,ICC,RLPSM,APSM,RWPC,RRPSM,CGW_CCU,APSS,ATS,RLHV,FPM,RDC,PSM,ASAU

BO_ 1309 NM_RRPSM: 8 RRPSM
 SG_ Destination_RRPSM : 0|8@1+ (1,0) [0|0] ""  DSAU,vHS_M,SHVU_RR,DPSS,AMP,ICC,RLPSM,APSM,RWPC,RRHV,CGW_CCU,APSS,ATS,RLHV,FPM,RDC,PSM,ASAU
 SG_ NMCommandCode_RRPSM : 8|3@1+ (1,0) [0|0] ""  DSAU,vHS_M,SHVU_RR,DPSS,AMP,ICC,RLPSM,APSM,RWPC,RRHV,CGW_CCU,APSS,ATS,RLHV,FPM,RDC,PSM,ASAU
 SG_ NMSleepFlag_RRPSM : 12|2@1+ (1,0) [0|0] ""  DSAU,vHS_M,SHVU_RR,DPSS,AMP,ICC,RLPSM,APSM,RWPC,RRHV,CGW_CCU,APSS,ATS,RLHV,FPM,RDC,PSM,ASAU

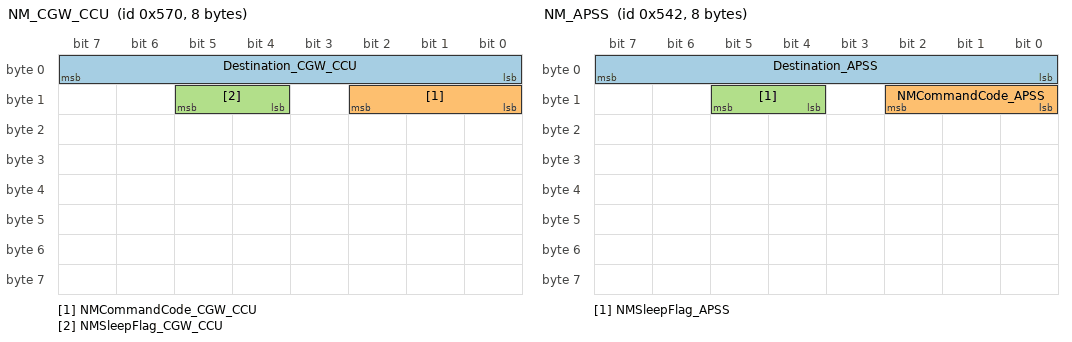
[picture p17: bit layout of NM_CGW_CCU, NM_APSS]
BO_ 1392 NM_CGW_CCU: 8 CGW_CCU
 SG_ Destination_CGW_CCU : 0|8@1+ (1,0) [0|0] ""  DSAU,vHS_M,SHVU_RR,DPSS,AMP,ICC,RLPSM,APSM,RWPC,RRHV,RRPSM,APSS,ATS,RLHV,FPM,RDC,PSM,ASAU
 SG_ NMCommandCode_CGW_CCU : 8|3@1+ (1,0) [0|0] ""  DSAU,vHS_M,SHVU_RR,DPSS,AMP,ICC,RLPSM,APSM,RWPC,RRHV,RRPSM,APSS,ATS,RLHV,FPM,RDC,PSM,ASAU
 SG_ NMSleepFlag_CGW_CCU : 12|2@1+ (1,0) [0|0] ""  DSAU,vHS_M,SHVU_RR,DPSS,AMP,ICC,RLPSM,APSM,RWPC,RRHV,RRPSM,APSS,ATS,RLHV,FPM,RDC,PSM,ASAU

BO_ 1346 NM_APSS: 8 APSS
 SG_ Destination_APSS : 0|8@1+ (1,0) [0|0] ""  DSAU,vHS_M,SHVU_RR,DPSS,AMP,ICC,RLPSM,APSM,RWPC,RRHV,RRPSM,CGW_CCU,ATS,RLHV,FPM,RDC,PSM,ASAU
 SG_ NMCommandCode_APSS : 8|3@1+ (1,0) [0|0] ""  DSAU,vHS_M,SHVU_RR,DPSS,AMP,ICC,RLPSM,APSM,RWPC,RRHV,RRPSM,CGW_CCU,ATS,RLHV,FPM,RDC,PSM,ASAU
 SG_ NMSleepFlag_APSS : 12|2@1+ (1,0) [0|0] ""  DSAU,vHS_M,SHVU_RR,DPSS,AMP,ICC,RLPSM,APSM,RWPC,RRHV,RRPSM,CGW_CCU,ATS,RLHV,FPM,RDC,PSM,ASAU

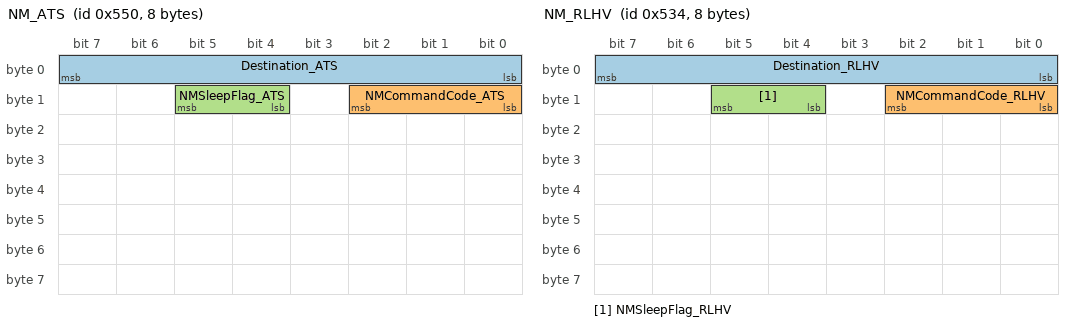
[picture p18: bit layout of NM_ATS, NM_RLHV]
BO_ 1360 NM_ATS: 8 ATS
 SG_ Destination_ATS : 0|8@1+ (1,0) [0|0] ""  DSAU,vHS_M,SHVU_RR,DPSS,AMP,ICC,RLPSM,APSM,RWPC,RRHV,RRPSM,CGW_CCU,APSS,RLHV,FPM,RDC,PSM,ASAU
 SG_ NMCommandCode_ATS : 8|3@1+ (1,0) [0|0] ""  DSAU,vHS_M,SHVU_RR,DPSS,AMP,ICC,RLPSM,APSM,RWPC,RRHV,RRPSM,CGW_CCU,APSS,RLHV,FPM,RDC,PSM,ASAU
 SG_ NMSleepFlag_ATS : 12|2@1+ (1,0) [0|0] ""  DSAU,vHS_M,SHVU_RR,DPSS,AMP,ICC,RLPSM,APSM,RWPC,RRHV,RRPSM,CGW_CCU,APSS,RLHV,FPM,RDC,PSM,ASAU

BO_ 1332 NM_RLHV: 8 RLHV
 SG_ Destination_RLHV : 0|8@1+ (1,0) [0|0] ""  DSAU,vHS_M,SHVU_RR,DPSS,AMP,ICC,RLPSM,APSM,RWPC,RRHV,RRPSM,CGW_CCU,APSS,ATS,FPM,RDC,PSM,ASAU
 SG_ NMCommandCode_RLHV : 8|3@1+ (1,0) [0|0] ""  DSAU,vHS_M,SHVU_RR,DPSS,AMP,ICC,RLPSM,APSM,RWPC,RRHV,RRPSM,CGW_CCU,APSS,ATS,FPM,RDC,PSM,ASAU
 SG_ NMSleepFlag_RLHV : 12|2@1+ (1,0) [0|0] ""  DSAU,vHS_M,SHVU_RR,DPSS,AMP,ICC,RLPSM,APSM,RWPC,RRHV,RRPSM,CGW_CCU,APSS,ATS,FPM,RDC,PSM,ASAU

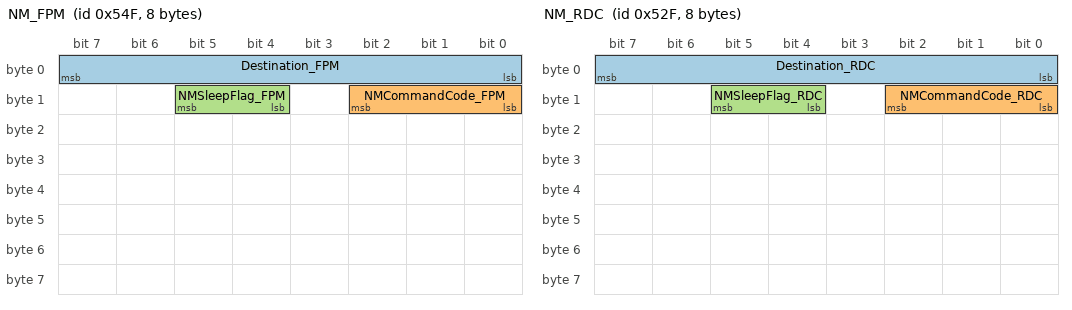
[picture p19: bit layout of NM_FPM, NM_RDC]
BO_ 1359 NM_FPM: 8 FPM
 SG_ Destination_FPM : 0|8@1+ (1,0) [0|0] ""  DSAU,vHS_M,SHVU_RR,DPSS,AMP,ICC,RLPSM,APSM,RWPC,RRHV,RRPSM,CGW_CCU,APSS,ATS,RLHV,RDC,PSM,ASAU
 SG_ NMCommandCode_FPM : 8|3@1+ (1,0) [0|0] ""  DSAU,vHS_M,SHVU_RR,DPSS,AMP,ICC,RLPSM,APSM,RWPC,RRHV,RRPSM,CGW_CCU,APSS,ATS,RLHV,RDC,PSM,ASAU
 SG_ NMSleepFlag_FPM : 12|2@1+ (1,0) [0|0] ""  DSAU,vHS_M,SHVU_RR,DPSS,AMP,ICC,RLPSM,APSM,RWPC,RRHV,RRPSM,CGW_CCU,APSS,ATS,RLHV,RDC,PSM,ASAU

BO_ 1327 NM_RDC: 8 RDC
 SG_ Destination_RDC : 0|8@1+ (1,0) [0|0] ""  DSAU,vHS_M,SHVU_RR,DPSS,AMP,ICC,RLPSM,APSM,RWPC,RRHV,RRPSM,CGW_CCU,APSS,ATS,RLHV,FPM,PSM,ASAU
 SG_ NMCommandCode_RDC : 8|3@1+ (1,0) [0|0] ""  DSAU,vHS_M,SHVU_RR,DPSS,AMP,ICC,RLPSM,APSM,RWPC,RRHV,RRPSM,CGW_CCU,APSS,ATS,RLHV,FPM,PSM,ASAU
 SG_ NMSleepFlag_RDC : 12|2@1+ (1,0) [0|0] ""  DSAU,vHS_M,SHVU_RR,DPSS,AMP,ICC,RLPSM,APSM,RWPC,RRHV,RRPSM,CGW_CCU,APSS,ATS,RLHV,FPM,PSM,ASAU

BO_ 1286 NM_PSM: 8 PSM
 SG_ Destination_PSM : 0|8@1+ (1,0) [0|0] ""  DSAU,vHS_M,SHVU_RR,DPSS,AMP,ICC,RLPSM,APSM,RWPC,RRHV,RRPSM,CGW_CCU,APSS,ATS,RLHV,FPM,RDC,ASAU
 SG_ NMCommandCode_PSM : 8|3@1+ (1,0) [0|0] ""  DSAU,vHS_M,SHVU_RR,DPSS,AMP,ICC,RLPSM,APSM,RWPC,RRHV,RRPSM,CGW_CCU,APSS,ATS,RLHV,FPM,RDC,ASAU
 SG_ NMSleepFlag_PSM : 12|2@1+ (1,0) [0|0] ""  DSAU,vHS_M,SHVU_RR,DPSS,AMP,ICC,RLPSM,APSM,RWPC,RRHV,RRPSM,CGW_CCU,APSS,ATS,RLHV,FPM,RDC,ASAU

BO_ 1363 NM_ASAU: 8 ASAU
 SG_ Destination_ASAU : 0|8@1+ (1,0) [0|0] ""  DSAU,vHS_M,SHVU_RR,DPSS,AMP,ICC,RLPSM,APSM,RWPC,RRHV,RRPSM,CGW_CCU,APSS,ATS,RLHV,FPM,RDC,PSM
 SG_ NMCommandCode_ASAU : 8|3@1+ (1,0) [0|0] ""  DSAU,vHS_M,SHVU_RR,DPSS,AMP,ICC,RLPSM,APSM,RWPC,RRHV,RRPSM,CGW_CCU,APSS,ATS,RLHV,FPM,RDC,PSM
 SG_ NMSleepFlag_ASAU : 12|2@1+ (1,0) [0|0] ""  DSAU,vHS_M,SHVU_RR,DPSS,AMP,ICC,RLPSM,APSM,RWPC,RRHV,RRPSM,CGW_CCU,APSS,ATS,RLHV,FPM,RDC,PSM

BO_TX_BU_ 1963 : PSM,vHS_M;
BO_TX_BU_ 1962 : vHS_M,FPM;
BO_TX_BU_ 1464 : vHS_M,RLPSM;
BO_TX_BU_ 1951 : APSM,vHS_M;
BO_TX_BU_ 1465 : RLPSM,vHS_M;
BO_TX_BU_ 1466 : vHS_M,ATS;
BO_TX_BU_ 1931 : AMP,vHS_M;
CM_ BO_ 2151682049 "[EW] On Event and On Write";
CM_ SG_ 2151682049 ACU_Crc2Val "ACU_CyclicRedundancyCheck2Value";
CM_ SG_ 2151682049 ACU_AlvCnt2Val "ACU_AliveCounter2Value";
CM_ SG_ 2151682049 ACU_CrshActvSta "ACU_CrashActiveStatus ##2G##ACU - ACU13 - CF_Acu_CshAct";
CM_ SG_ 2151682049 ACU_CrshInfo "ACU Crash Event information";
CM_ SG_ 2151682049 ACU_CrshTyp "Indication of crash type";
CM_ BO_ 2256642049 "[P] Periodic";
CM_ SG_ 2256642049 ADAS_CMD_Crc20Val "ADAS_CMD_CyclicRedundancyCheck20Value ##2G##SCC - SCC12 - CR_VSM_ChkSum";
CM_ SG_ 2256642049 ADAS_CMD_AlvCnt20Val "ADAS_CMD_AliveCounter20Value ##2G##SCC - SCC12 - CR_VSM_Alive";
CM_ SG_ 2256642049 SCC_ObjDstVal "SCC_ObjectDistanceValue ##2G##SCC - SCC11 - SCC_ObjDist";
CM_ SG_ 2256642049 SCC_ObjRelSpdVal "SCC_ObjectRelativeSpeedValue ##2G##SCC - SCC11 - SCC_ObjRelSpd";
CM_ SG_ 2256642049 SCC_ObjLatPosVal "SCC_ObjectLateralPositionValue ##2G##SCC - SCC11 - SCC_ObjLatPos";
CM_ BO_ 2256642050 "[P] Periodic";
CM_ SG_ 2256642050 SCC_SysFlrSta "SCC_SystemFailureStatus ##2G##SCC - SCC12 - SCCFailInfo";
CM_ SG_ 2256642050 SCC_InfoDis "SCC_InformationDisplay ##2G##SCC - SCC11 - SCCInfoDisplay";
CM_ SG_ 2256642050 SCC_DrvAlrtDis "SCC_DriverAlertDisplay ##2G##SCC - SCC11 - DriverAlertDisplay";
CM_ SG_ 2256642050 SCC_MainOnOffSta "SCC_MainOnOffStatus ##2G##SCC - SCC11 - MainMode_SCC";
CM_ SG_ 2256642050 SCC_HeadwayDstSetVal "SCC_HeadwayDistanceSettingValue ##2G##SCC - SCC11 - TauGapSet";
CM_ SG_ 2256642050 SCC_NSCCAutoSetSpdSta "SCC_NSCCAutoSetSpeedStatus ##2G##SCC ? SCC14 - NSCC_AutoSetSpdSta";
CM_ SG_ 2256642050 SCC_TrgtSpdSetVal "SCC_TargetSpeedSettingValue ##2G##SCC - SCC11 - VSetDis";
CM_ SG_ 2256642050 SCC_OpSta "SCC_OperatingStatus ##2G##SCC - SCC14 - SCCMode2";
CM_ SG_ 2256642050 SCC_NSCCOpSta "SCC_NSCCOperatingStatus ##2G##SCC - SCC11 - NSCC_Camera_Act";
CM_ SG_ 2256642050 SCC_NSCCOnOffSta "SCC_NSCCOnOffStatus ##2G##SCC - SCC13 - NSCC_Zone_USM";
CM_ SG_ 2256642050 SCC_ObjSta "SCC_ObjectState";
CM_ SG_ 2256642050 SCC_NSCCAutoSetSpdUpdtSta "SCC_NSCCAutoSetSpeedUpdateStatus ##2G##LDW_LKA - HDA11 - CF_HDA_AutoSetSpdUpdate";
CM_ SG_ 2256642050 SCC_NSCCInfoPUDis "SCC_NSCCInformationPopUpDisplay";
CM_ SG_ 2256642050 SCC_TakeoverReq "SCC_TakeoverRequest ##2G##SCC - SCC12 - TakeOverReq";
CM_ BO_ 2256642051 "[P] Periodic";
CM_ SG_ 2256642051 SCC_AccelReqVal "SCC_AccelerationRequestValue ##2G##SCC - SCC12 - aReqValue";
CM_ SG_ 2256642051 SCC_AccelReqRawVal "SCC_AccelerationRequestRawValue ##2G##SCC - SCC12 - aReqRaw";
CM_ SG_ 2256642051 SCC_JrkUppLimVal "SCC_JerkUpperLimitValue ##2G##SCC - SCC14 - JerkUpperLimit";
CM_ SG_ 2256642051 SCC_JrkLwrLimVal "SCC_JerkLowerLimitValue ##2G##SCC - SCC14 - JerkLowerLimit";
CM_ SG_ 2256642051 SCC_AccelLimBandUppVal "SCC_AccelerationLimitBandUpperValue ##2G##SCC - SCC14 - ComfortBandUpper";
CM_ SG_ 2256642051 SCC_AccelLimBandLwrVal "SCC_AccelerationLimitBandLowerValue ##2G##SCC - SCC14 - ComfortBandLower";
CM_ SG_ 2256642051 SCC_VehStpReq "SCC_VehicleStopRequest ##2G##SCC - SCC12 - StopReq";
CM_ BO_ 2256642052 "[P] Periodic";
CM_ SG_ 2256642052 SCC_TrgtDstVal "SCC_TargetDistanceValue";
CM_ SG_ 2256642052 HDP_LongActvSta "HDP_Longitudinal Active Status";
CM_ SG_ 2256642052 HDP_MRMCtrlSta "HDP_MinimumRiskManeuverControlStatus";
CM_ SG_ 2256642052 HDP_ESCOnReq "HDP_ESCOnRequest";
CM_ SG_ 2256642052 HDP_AccelOvrdLmt "HDP_AccelerationOverrideLimited";
CM_ BO_ 1931 "[TP] Transport Protocol";
CM_ BO_ 981 "[PE] Periodic and On Event";
CM_ SG_ 981 APSS_StSldFwdMvBtn "APSS_SlideForwardMoveButton";
CM_ SG_ 981 APSS_StSldBwdMvBtn "APSS_SlideBackwardMoveButton";
CM_ SG_ 981 APSS_StRclFwdMvBtn "APSS_ReclinerForwardMoveButton";
CM_ SG_ 981 APSS_StRclBwdMvBtn "APSS_ReclinerBackwardMoveButton";
CM_ SG_ 981 APSS_StHgtUpMvBtn "APSS_HeightUpMoveButton";
CM_ SG_ 981 APSS_StHgtDnMvBtn "APSS_HeightDownMoveButton";
CM_ SG_ 981 APSS_StTltUpMvBtn "APSS_TiltUpMoveButton";
CM_ SG_ 981 APSS_StTltDnMvBtn "APSS_TiltDownMoveButton";
CM_ SG_ 981 APSS_StHRestUpMvBtn "APSS_Head Rest Up Move Button";
CM_ SG_ 981 APSS_StHRestDnMvBtn "APSS_Head Rest Down Move Button";
CM_ SG_ 981 APSS_StHRestFwdMvBtn "APSS_Head Rest Forward Move Button";
CM_ SG_ 981 APSS_StHRestBwdMvBtn "APSS_Head Rest Backward Move Button";
CM_ SG_ 981 APSS_StLegUpMvBtn "APSS_LegUpMoveButton";
CM_ SG_ 981 APSS_StLegDnMvBtn "APSS_LegDownMoveButton";
CM_ SG_ 981 APSS_StRlxModeBtn "APSS_RelaxModeButton";
CM_ SG_ 981 APSS_StRlxReturnBtn "APSS_RelaxReturnButton";
CM_ SG_ 981 APSS_StRlxTltUpMvBtn "APSS_RelaxTiltUpMoveButton";
CM_ SG_ 981 APSS_StRlxTltDnMvBtn "APSS_RelaxTiltDownMoveButton";
CM_ BO_ 1951 "[TP] Transport Protocol";
CM_ BO_ 1466 "[TP] Transport Protocol";
CM_ SG_ 1466 ATS_GST_Byte0 "Diag Response from ATS";
CM_ SG_ 1466 ATS_GST_Byte2 "Diag Response from ATS";
CM_ SG_ 1466 ATS_GST_Byte3 "Diag Response from ATS";
CM_ SG_ 1466 ATS_GST_Byte4 "Diag Response from ATS";
CM_ SG_ 1466 ATS_GST_Byte5 "Diag Response from ATS";
CM_ SG_ 1466 ATS_GST_Byte6 "Diag Response from ATS";
CM_ SG_ 1466 ATS_GST_Byte7 "Diag Response from ATS";
CM_ SG_ 1466 ATS_GST_Byte1 "Diag Response from ATS";
CM_ BO_ 997 "[PE] Periodic and On Event";
CM_ SG_ 997 BCM_Crc5Val "BCM_CyclicRedundancyCheck5Value";
CM_ SG_ 997 BCM_AlvCnt5Val "BCM_AliveCounter5Value";
CM_ SG_ 997 PDW_OptTyp "PDW_OptionType ##2G##BCM - BCMmsg18 - C_PASOption";
CM_ SG_ 997 PDW_SysChkSndSta "PDW_SystemCheckSoundStatus ##2G##BCM - BCMmsg18 - C_PASCheckSound";
CM_ SG_ 997 PDW_SwIndOnReq "PDW_SwitchIndicatorOnRequest ##2G##BCM - BCMmsg18 - C_PASSwInd";
CM_ SG_ 997 PDW_SysOnSta "PDW_SystemOnStatus ##2G##BCM - BCMmsg18 - C_PASSystemOn";
CM_ SG_ 997 PDW_FrCtWrngLvlDis "PDW_FrontCenterWarningLevelDisplay ##2G##BCM - BCMmsg18 - C_PASDisplayFCTR";
CM_ SG_ 997 PDW_FrCtWrngSndSta "PDW_FrontCenterWarningSoundStatus ##2G##BCM - BCMmsg23 - C_PasSpkrFCNTAlarm";
CM_ SG_ 997 PDW_FrLtWrngLvlDis "PDW_FrontLeftWarningLevelDisplay ##2G##BCM - BCMmsg18 - C_PASDisplayFLH";
CM_ SG_ 997 PDW_FrLtWrngSndSta "PDW_FrontLeftWarningSoundStatus ##2G##BCM - BCMmsg23 - C_PasSpkrFLHAlarm";
CM_ SG_ 997 PDW_FrRtWrngLvlDis "PDW_FrontRightWarningLevelDisplay ##2G##BCM - BCMmsg18 - C_PASDisplayFRH";
CM_ SG_ 997 PDW_FrRtWrngSndSta "PDW_FrontRightWarningSoundStatus ##2G##BCM - BCMmsg23 - C_PasSpkrFRHAlarm";
CM_ SG_ 997 PDW_FrSnsrWrngLvlSta "PDW_FrontSensorWarningLevelStatus ##2G##BCM - BCMmsg18 - C_PASFsound";
CM_ BO_ 998 "[PE] Periodic and On Event";
CM_ SG_ 998 BCM_Crc6Val "BCM_CyclicRedundancyCheck6Value";
CM_ SG_ 998 BCM_AlvCnt6Val "BCM_AliveCounter6Value";
CM_ SG_ 998 PDW_RrCtWrngLvlDis "PDW_RearCenterWarningLevelDisplay ##2G##BCM - BCMmsg18 - C_PASDisplayRCTR";
CM_ SG_ 998 PDW_RrCtWrngSndSta "PDW_RearCenterWarningSoundStatus ##2G##BCM - BCMmsg23 - C_PasSpkrRCNTAlarm";
CM_ SG_ 998 PDW_RrLtWrngLvlDis "PDW_RearLeftWarningLevelDisplay ##2G##BCM - BCMmsg18 - C_PASDisplayRLH";
CM_ SG_ 998 PDW_RrLtWrngSndSta "PDW_RearLeftWarningSoundStatus ##2G##BCM - BCMmsg23 - C_PasSpkrRLHAlarm";
CM_ SG_ 998 PDW_RrRtWrngLvlDis "PDW_RearRightWarningLevelDisplay ##2G##BCM - BCMmsg18 - C_PASDisplayRRH";
CM_ SG_ 998 PDW_RrRtWrngSndSta "PDW_RearRightWarningSoundStatus ##2G##BCM - BCMmsg23 - C_PasSpkrRRHAlarm";
CM_ SG_ 998 PDW_RrSnsrWrngLvlSta "PDW_RearSensorWarningLevelStatus ##2G##BCM - BCMmsg18 - C_PASRsound";
CM_ BO_ 963 "[PE] Periodic and On Event";
CM_ SG_ 963 BCM_Crc16Val "BCM_CyclicRedundancyCheck16Value";
CM_ SG_ 963 BCM_AlvCnt16Val "BCM_AliveCounter16Value";
CM_ SG_ 963 IBU_SWVerMajor1 "First Word(ASCII) in IBU S/W Ver";
CM_ SG_ 963 IBU_SWVerMinor1 "Second Word(ASCII) in IBU S/W Ver";
CM_ SG_ 963 IBU_SWVerMinor2 "Third Word(ASCII) in IBU S/W Ver";
CM_ BO_ 2445570561 "[PE] Periodic and On Event";
CM_ SG_ 2445570561 USM_CluAdasVolSta "USM_CluAdasVolumeStatus";
CM_ SG_ 2445570561 Wrn_Snd_AdasVolFdbck "2nd general signal : Warn_AdasVolumeFeedback";
CM_ BO_ 2441372929 "[EC] On Event and On Change";
CM_ SG_ 2441372929 DATC_Crc14Val "DATC_CyclicRedundancyCheck14Value";
CM_ SG_ 2441372929 DATC_AlvCnt14Val "DATC_AliveCounter14Value";
CM_ SG_ 2441372929 DATC_Beep1Sound "DATC_Beep1Mode";
CM_ BO_ 2328014849 "[P] Periodic";
CM_ SG_ 2328014849 DATC_Crc17Val "DATC_CyclicRedundancyCheck17Value";
CM_ SG_ 2328014849 DATC_AlvCnt17Val "DATC_AliveCounter17Value";
CM_ SG_ 2328014849 DATC_FrontPwmIsVolt "DATC Blow Motor converted Voltage";
CM_ SG_ 2328014849 DATC_FrontBlwDuty "DATC Blow Motor command duty";
CM_ SG_ 2328014849 DATC_FrontBlwDiagStat "DATC Blow Motor diagnosis state";
CM_ SG_ 2328014849 DATC_BlwrLvl_Ps "DATC_BlowerLevel_Passenger";
CM_ SG_ 2328014849 DATC_BlwrLvl_Rr "DATC_BlowerLevel_Rear";
CM_ BO_ 2328014850 "[P] Periodic";
CM_ SG_ 2328014850 DATC_FnDstStp "DATC_FineDustStep";
CM_ SG_ 2328014850 DATC_HDPDfg_Sta "DATC_HDPAutoDefog_Status";
CM_ SG_ 2328014850 DATC_HDPHumidity_Sta "DATC_HDPHumidity_Status";
CM_ SG_ 2328014850 DATC_FnDstStp_Detail "DATC_FineDustStep_Detail";
CM_ BO_ 2328014851 "[P] Periodic";
CM_ BO_ 2328014852 "[P] Periodic";
CM_ BO_ 1962 "[TP] Transport Protocol";
CM_ BO_ 1923 "[TP] Transport Protocol";
CM_ BO_ 1943 "[TP] Transport Protocol";
CM_ BO_ 1458 "[TP] Transport Protocol";
CM_ SG_ 1458 GST_ATS_Byte0 "Diag Request for ATS";
CM_ SG_ 1458 GST_ATS_Byte2 "Diag Request for ATS";
CM_ SG_ 1458 GST_ATS_Byte3 "Diag Request for ATS";
CM_ SG_ 1458 GST_ATS_Byte4 "Diag Request for ATS";
CM_ SG_ 1458 GST_ATS_Byte5 "Diag Request for ATS";
CM_ SG_ 1458 GST_ATS_Byte6 "Diag Request for ATS";
CM_ SG_ 1458 GST_ATS_Byte7 "Diag Request for ATS";
CM_ SG_ 1458 GST_ATS_Byte1 "Diag Request for ATS";
CM_ BO_ 1457 "[TP] Transport Protocol";
CM_ SG_ 1457 GST_RLSAU_Byte0 "Diag Request for RLSAU";
CM_ SG_ 1457 GST_RLSAU_Byte2 "Diag Request for RLSAU";
CM_ SG_ 1457 GST_RLSAU_Byte3 "Diag Request for RLSAU";
CM_ SG_ 1457 GST_RLSAU_Byte4 "Diag Request for RLSAU";
CM_ SG_ 1457 GST_RLSAU_Byte5 "Diag Request for RLSAU";
CM_ SG_ 1457 GST_RLSAU_Byte6 "Diag Request for RLSAU";
CM_ SG_ 1457 GST_RLSAU_Byte7 "Diag Request for RLSAU";
CM_ SG_ 1457 GST_RLSAU_Byte1 "Diag Request for RLSAU";
CM_ BO_ 1456 "[TP] Transport Protocol";
CM_ SG_ 1456 GST_RRSAU_Byte0 "Diag Request for RRSAU";
CM_ SG_ 1456 GST_RRSAU_Byte2 "Diag Request for RRSAU";
CM_ SG_ 1456 GST_RRSAU_Byte3 "Diag Request for RRSAU";
CM_ SG_ 1456 GST_RRSAU_Byte4 "Diag Request for RRSAU";
CM_ SG_ 1456 GST_RRSAU_Byte5 "Diag Request for RRSAU";
CM_ SG_ 1456 GST_RRSAU_Byte6 "Diag Request for RRSAU";
CM_ SG_ 1456 GST_RRSAU_Byte7 "Diag Request for RRSAU";
CM_ SG_ 1456 GST_RRSAU_Byte1 "Diag Request for RRSAU";
CM_ BO_ 2563125249 "[EC] On Event and On Change";
CM_ SG_ 2563125249 AMP_Beep2Mode "Play touch beep sound for rear monitor";
CM_ SG_ 2563125249 AMP_Beep1Mode "Play touch beep sound one time
Beep1 mode on/off
For Harman AMP
Default : Off
Goes On when play beep sound
-This Signal's Feedback is AMP_Beep1ModeState(0x180)@AMP";
CM_ SG_ 2563125249 AMP_RrTTSSound "Rear TTS prompt on/offOnly ON during the Rear TTS Sound Playing Default : Off-This Signal's Feedback is AMP_RrTTSModeState(0x60c)@AMP";
CM_ SG_ 2563125249 AMP_ASDMode "ASD Set Mode Value";
CM_ SG_ 2563125249 AMP_ANCMode "Signal for setting ANC On/Off";
CM_ SG_ 2563125249 AMP_NaviSound "Navi prompt on/off
Only ON during the Navi Guide Sound Playing
Default : Off
-This Signal's Feedback is AMP_NaviModeState(0x180)@AMP";
CM_ SG_ 2563125249 AMP_Beep1KBDMode "Play touch beep sound at keyboard screen on AVN-This Signal's Feedback is AMP_Beep1KBDModeState@AMP";
CM_ SG_ 2563125249 AMP_TTSSound "TTS prompt on/offOnly ON during the TTS Sound Playing Default : Off-This Signal's Feedback is AMP_TTSModeState(0x60c)@AMP";
CM_ SG_ 2563125249 AMP_SDVCStep "SDVC(Speed Dependant Volume Control = VSC) 
Step4 : off, low, mid, high";
CM_ BO_ 2563125761 "[EC] On Event and On Change";
CM_ SG_ 2563125761 AMP_LogSnapshot "Log Snapshot touch in ENG Mode (AMP)";
CM_ SG_ 2563125761 AMP_VersionReq "Command for Request Display current version of AMP on Headunit monitor in engineering Mode";
CM_ BO_ 2458167553 "[EC] On Event and On Change";
CM_ SG_ 2458167553 C_PTGMNValueSet "Request to set PTGM Mode";
CM_ SG_ 2458167553 CF_AVN_PSMNValueSet "This signal is used for a request to set the value of UMS Menus. This signal requests to set Seat Easy Access Mode. When this signal change, the message is sent 3 times.";
CM_ SG_ 2458167553 C_HfreeTrunkTgNValueSet "Request to set Smart Trunk/Tailgate Mode";
CM_ SG_ 2458167553 CF_AVN_TrfChgSet "This signal is used for a request to set the value of UMS Menus. This signal requests to set Traffic Change Mode. When this signal change, the message is sent 3 times.";
CM_ SG_ 2458167553 CF_AVN_SCMNValueSet "Request to set Steering Easy Access mode";
CM_ SG_ 2458167553 CF_AVN_ADrUNValueSet "Request to set Auto Door Unlock Mode";
CM_ SG_ 2458167553 CF_AVN_OTTurnNValueSet "This signal is used for a request current setting value of USM Menus. When this signal change, the message is sent 3 times.";
CM_ SG_ 2458167553 CF_Gway_WPCNValueSet "Request to set Wireless Phone Charging mode";
CM_ SG_ 2458167553 C_AVN_RearWiperNValueSet "Request to set Rear Wiper operation in reverse";
CM_ SG_ 2458167553 C_UnlockWelocomeNValueSet "Request to set Door Unlock Welcome Setting Option";
CM_ SG_ 2458167553 C_SmartWelocomeNValueSet "Request to set Smart Key Welcome Setting Option";
CM_ SG_ 2458167553 CF_AVN_PTGSpeedNValueSet "Setting Value For Power Tailgate Speed";
CM_ SG_ 2458167553 CR_Datc_DRSeatWheel_USM_Set "SteeringWheel USM Set";
CM_ SG_ 2458167553 CF_AVN_SequencialLampNValue "Setting Value For Sequential Lamp";
CM_ SG_ 2458167553 CF_AVN_TTUnlockNValueSet "Setting Value for Two Turn Unlock";
CM_ SG_ 2458167553 CF_Gway_RWPCNValueSet "Rear Wireless Phone Charger ON/OFF Request";
CM_ SG_ 2458167553 CF_Avn_BolsterNValueSet "USM Request for Seatback bolster adjustment in Drive mode";
CM_ SG_ 2458167553 C_PSDNValueSet "Request to set PSD Mode. USM request signal for setting Power Sliding Door.";
CM_ SG_ 2458167553 C_StrWheelAutoHeatNValueSet "USM Request for Steering Wheel Auto Heat function";
CM_ SG_ 2458167553 CF_Avn_HAPTICWARNINGNValueSet "USM request for Steering Wheel Haptic Warning";
CM_ SG_ 2458167553 CF_AVN_ADrLNValueSet "Request set the new Auto Door Lock Mode";
CM_ SG_ 2458167553 CR_Datc_DRSeatHeat_USM_Set "Driver Seat Heat/Ventl USM Set";
CM_ SG_ 2458167553 C_WALNValueSet "USM Function for Walk Away Lock(WAL)";
CM_ SG_ 2458167553 C_ApprUnlockNValue "USM request for Approach Unlock";
CM_ SG_ 2458167553 CF_AVN_SEW_NEWNValueSet "Reguest to Safety Exit Warning";
CM_ SG_ 2458167553 CF_AVN_SEA_NEWNValueSet "Reguest to Safety Exit Assist";
CM_ SG_ 2458167553 CF_AVN_TunnelWindowNvalueSet "USM for auto window control when entering a tunnel";
CM_ SG_ 2458167553 CF_AVN_EscortHLNValueSet "Request to set Head Lamp Escort Option";
CM_ BO_ 961 "[PE] Periodic and On Event";
CM_ SG_ 961 MFSW_Crc1Val "MFSW_CyclicRedundancyCheck1Value";
CM_ SG_ 961 MFSW_AlvCnt1Val "MFSW_AliveCounter1Value";
CM_ SG_ 961 Lamp_HdLmpHiSwSta "Lamp_HeadLampHighSwitchStatus";
CM_ SG_ 961 Lamp_LtSwSta "Lamp_LightSwitchStatus";
CM_ SG_ 961 Lamp_PassingLmpSwSta "Lamp_PassingLampSwitchStatus";
CM_ SG_ 961 Lamp_RrFogLmpSwSta "Lamp_RearFogLampSwitchStatus";
CM_ SG_ 961 Lamp_TrnSigLftSwSta "Lamp_TurnSignalLeftSwitchStatus";
CM_ SG_ 961 Lamp_TrnSigRtSwSta "Lamp_TurnSignalRightSwitchStatus";
CM_ SG_ 961 Lamp_LaneChgTrnSigLftSwSta "Lamp_LaneChangeTurnSignalLeftSwitchStatus";
CM_ SG_ 961 Lamp_LaneChgTrnSigRtSwSta "Lamp_LaneChangeTurnSignalRightSwitchStatus";
CM_ BO_ 1963 "[TP] Transport Protocol";
CM_ BO_ 1465 "[TP] Transport Protocol";
CM_ SG_ 1465 RLSAU_GST_Byte0 "Diag Response from RLSAU";
CM_ SG_ 1465 RLSAU_GST_Byte2 "Diag Response from RLSAU";
CM_ SG_ 1465 RLSAU_GST_Byte3 "Diag Response from RLSAU";
CM_ SG_ 1465 RLSAU_GST_Byte4 "Diag Response from RLSAU";
CM_ SG_ 1465 RLSAU_GST_Byte5 "Diag Response from RLSAU";
CM_ SG_ 1465 RLSAU_GST_Byte6 "Diag Response from RLSAU";
CM_ SG_ 1465 RLSAU_GST_Byte7 "Diag Response from RLSAU";
CM_ SG_ 1465 RLSAU_GST_Byte1 "Diag Response from RLSAU";
CM_ BO_ 1464 "[TP] Transport Protocol";
CM_ SG_ 1464 RRSAU_GST_Byte0 "Diag Response from RRSAU";
CM_ SG_ 1464 RRSAU_GST_Byte2 "Diag Response from RRSAU";
CM_ SG_ 1464 RRSAU_GST_Byte3 "Diag Response from RRSAU";
CM_ SG_ 1464 RRSAU_GST_Byte4 "Diag Response from RRSAU";
CM_ SG_ 1464 RRSAU_GST_Byte5 "Diag Response from RRSAU";
CM_ SG_ 1464 RRSAU_GST_Byte6 "Diag Response from RRSAU";
CM_ SG_ 1464 RRSAU_GST_Byte7 "Diag Response from RRSAU";
CM_ SG_ 1464 RRSAU_GST_Byte1 "Diag Response from RRSAU";
CM_ BO_ 1369 "NM Message";
CM_ SG_ 1369 Destination_DSAU "NM Source Node Identifier";
CM_ SG_ 1369 NMCommandCode_DSAU "NM Control Bit Vector - Repeat Message Request";
CM_ SG_ 1369 NMSleepFlag_DSAU "NM Control Bit Vector - NM Coordinator ID";
CM_ BO_ 1323 "NM Message";
CM_ SG_ 1323 Destination_SHVU_RR "NM Source Node Identifier";
CM_ SG_ 1323 NMCommandCode_SHVU_RR "NM Control Bit Vector - Repeat Message Request";
CM_ SG_ 1323 NMSleepFlag_SHVU_RR "NM Control Bit Vector - NM Coordinator ID";
CM_ BO_ 1337 "NM Message";
CM_ SG_ 1337 Destination_DPSS "NM Source Node Identifier";
CM_ SG_ 1337 NMCommandCode_DPSS "NM Control Bit Vector - Repeat Message Request";
CM_ SG_ 1337 NMSleepFlag_DPSS "NM Control Bit Vector - NM Coordinator ID";
CM_ BO_ 1376 "NM Message";
CM_ SG_ 1376 Destination_AMP "NM Source Node Identifier";
CM_ SG_ 1376 NMCommandCode_AMP "NM Control Bit Vector - Repeat Message Request";
CM_ SG_ 1376 NMSleepFlag_AMP "NM Control Bit Vector - NM Coordinator ID";
CM_ BO_ 1367 "NM Message";
CM_ SG_ 1367 Destination_ICC "NM Source Node Identifier";
CM_ SG_ 1367 NMCommandCode_ICC "NM Control Bit Vector - Repeat Message Request";
CM_ SG_ 1367 NMSleepFlag_ICC "NM Control Bit Vector - NM Coordinator ID";
CM_ BO_ 1308 "NM Message";
CM_ SG_ 1308 Destination_RLPSM "NM Source Node Identifier";
CM_ SG_ 1308 NMCommandCode_RLPSM "NM Control Bit Vector - Repeat Message Request";
CM_ SG_ 1308 NMSleepFlag_RLPSM "NM Control Bit Vector - NM Coordinator ID";
CM_ BO_ 1289 "NM Message";
CM_ SG_ 1289 Destination_APSM "NM Source Node Identifier";
CM_ SG_ 1289 NMCommandCode_APSM "NM Control Bit Vector - Repeat Message Request";
CM_ SG_ 1289 NMSleepFlag_APSM "NM Control Bit Vector - NM Coordinator ID";
CM_ BO_ 1311 "NM Message";
CM_ SG_ 1311 Destination_RWPC "NM Source Node Identifier";
CM_ SG_ 1311 NMCommandCode_RWPC "NM Control Bit Vector - Repeat Message Request";
CM_ SG_ 1311 NMSleepFlag_RWPC "NM Control Bit Vector - NM Coordinator ID";
CM_ BO_ 1333 "NM Message";
CM_ SG_ 1333 Destination_RRHV "NM Source Node Identifier";
CM_ SG_ 1333 NMCommandCode_RRHV "NM Control Bit Vector - Repeat Message Request";
CM_ SG_ 1333 NMSleepFlag_RRHV "NM Control Bit Vector - NM Coordinator ID";
CM_ BO_ 1309 "NM Message";
CM_ SG_ 1309 Destination_RRPSM "NM Source Node Identifier";
CM_ SG_ 1309 NMCommandCode_RRPSM "NM Control Bit Vector - Repeat Message Request";
CM_ SG_ 1309 NMSleepFlag_RRPSM "NM Control Bit Vector - NM Coordinator ID";
CM_ BO_ 1392 "NM Message";
CM_ SG_ 1392 Destination_CGW_CCU "NM Source Node Identifier";
CM_ SG_ 1392 NMCommandCode_CGW_CCU "NM Control Bit Vector - Repeat Message Request";
CM_ SG_ 1392 NMSleepFlag_CGW_CCU "NM Control Bit Vector - NM Coordinator ID";
CM_ BO_ 1346 "NM Message";
CM_ SG_ 1346 Destination_APSS "NM Source Node Identifier";
CM_ SG_ 1346 NMCommandCode_APSS "NM Control Bit Vector - Repeat Message Request";
CM_ SG_ 1346 NMSleepFlag_APSS "NM Control Bit Vector - NM Coordinator ID";
CM_ BO_ 1360 "NM Message";
CM_ SG_ 1360 Destination_ATS "NM Source Node Identifier";
CM_ SG_ 1360 NMCommandCode_ATS "NM Control Bit Vector - Repeat Message Request";
CM_ SG_ 1360 NMSleepFlag_ATS "NM Control Bit Vector - NM Coordinator ID";
CM_ BO_ 1332 "NM Message";
CM_ SG_ 1332 Destination_RLHV "NM Source Node Identifier";
CM_ SG_ 1332 NMCommandCode_RLHV "NM Control Bit Vector - Repeat Message Request";
CM_ SG_ 1332 NMSleepFlag_RLHV "NM Control Bit Vector - NM Coordinator ID";
CM_ BO_ 1359 "NM Message";
CM_ SG_ 1359 Destination_FPM "NM Source Node Identifier";
CM_ SG_ 1359 NMCommandCode_FPM "NM Control Bit Vector - Repeat Message Request";
CM_ SG_ 1359 NMSleepFlag_FPM "NM Control Bit Vector - NM Coordinator ID";
CM_ BO_ 1327 "NM Message";
CM_ SG_ 1327 Destination_RDC "NM Source Node Identifier";
CM_ SG_ 1327 NMCommandCode_RDC "NM Control Bit Vector - Repeat Message Request";
CM_ SG_ 1327 NMSleepFlag_RDC "NM Control Bit Vector - NM Coordinator ID";
CM_ BO_ 1286 "NM Message";
CM_ SG_ 1286 Destination_PSM "NM Source Node Identifier";
CM_ SG_ 1286 NMCommandCode_PSM "NM Control Bit Vector - Repeat Message Request";
CM_ SG_ 1286 NMSleepFlag_PSM "NM Control Bit Vector - NM Coordinator ID";
CM_ BO_ 1363 "NM Message";
CM_ SG_ 1363 Destination_ASAU "NM Source Node Identifier";
CM_ SG_ 1363 NMCommandCode_ASAU "NM Control Bit Vector - Repeat Message Request";
CM_ SG_ 1363 NMSleepFlag_ASAU "NM Control Bit Vector - NM Coordinator ID";
BA_DEF_ BO_ "DiagState" ENUM "No","Yes" ;
BA_DEF_ BO_ "DiagResponse" ENUM "No","Yes" ;
BA_DEF_ BO_ "DiagRequest" ENUM "No","Yes" ;
BA_DEF_ BO_ "TpMessage" ENUM "No","Yes" ;
BA_DEF_ BO_ "UsrMsgIDSforwardDeviation" INT 0 100 ;
BA_DEF_ BO_ "UsrMsgIDSbackwardDeviation" INT 50 1000 ;
BA_DEF_ BO_ "GenMsgCycleTime" INT 0 2000 ;
BA_DEF_ BO_ "GenMsgStartDelayTime" INT 0 2000 ;
BA_DEF_ BO_ "GenMsgSendType" ENUM "Cyclic","NoMsgSendType" ;
BA_DEF_ BO_ "GenMsgCycleTimeFast" INT 0 500 ;
BA_DEF_ BO_ "GenMsgDelayTime" INT 0 20 ;
BA_DEF_ BO_ "GenMsgILSupport" ENUM "No","Yes" ;
BA_DEF_ BO_ "GenMsgNrOfRepetition" INT 0 3 ;
BA_DEF_ BO_ "NmMessage" ENUM "No","Yes" ;
BA_DEF_ BO_ "NWM-Botschaft" ENUM "No","Yes" ;
BA_DEF_ BO_ "TpTxIndex" INT 0 255 ;
BA_DEF_ BO_ "VFrameFormat" ENUM "StandardCAN","ExtendedCAN","reserved","reserved","reserved","reserved","reserved","reserved","reserved","reserved","reserved","reserved","reserved","reserved","StandardCAN_FD","ExtendedCAN_FD" ;
BA_DEF_ SG_ "UserSigValidity" ENUM "B+","ACC","IG","IG1","IG2","IG3","IG1 or IG2","IG1 or IG3","Undef" ;
BA_DEF_ SG_ "TimeoutValue" STRING ;
BA_DEF_ SG_ "UsrSigPurpose" ENUM "Undef","FN","DIAG","DIAG(Req)","DIAG(Res)","DIAG(Phy)","DEV","CCP(Req)","CCP(Res)","NM","TP" ;
BA_DEF_ SG_ "GenSigStartValue" INT 0 1215752192 ;
BA_DEF_ SG_ "NetworkRequest" ENUM "Yes","No" ;
BA_DEF_ SG_ "NetworkRequestHoldingTime" INT 0 65535 ;
BA_DEF_ SG_ "Description" STRING ;
BA_DEF_ SG_ "Version" STRING ;
BA_DEF_ SG_ "GenSigEnvVarType" ENUM "Int","Float","Undef" ;
BA_DEF_ SG_ "GenSigSendType" ENUM "Cyclic","OnWrite","OnWriteWithRepetition","OnChange","OnChangeWithRepetition","IfActive","IfActiveWithRepetition","NoSigSendType","OnChangeAndIfActive","OnChangeAndIfActiveWithRepetition" ;
BA_DEF_ SG_ "GwSigLatencyTime" INT 0 65536 ;
BA_DEF_ SG_ "GwSigMissingSourceType" ENUM "Undef","OldValue","DefaultValue","InitialValue" ;
BA_DEF_ SG_ "NWM-WakeupAllowed" ENUM "<n.a.>" ;
BA_DEF_ SG_ "RoutingFactor" INT 1 1215752192 ;
BA_DEF_REL_ BU_SG_REL_ "GenSigTimeoutTime" INT 0 7000 ;
BA_DEF_DEF_ "DiagState" "No" ;
BA_DEF_DEF_ "DiagResponse" "No" ;
BA_DEF_DEF_ "DiagRequest" "No" ;
BA_DEF_DEF_ "TpMessage" "No" ;
BA_DEF_DEF_ "UsrMsgIDSforwardDeviation" 10 ;
BA_DEF_DEF_ "UsrMsgIDSbackwardDeviation" 100 ;
BA_DEF_DEF_ "GenMsgCycleTime" 200 ;
BA_DEF_DEF_ "GenMsgStartDelayTime" 0 ;
BA_DEF_DEF_ "GenMsgSendType" "NoMsgSendType" ;
BA_DEF_DEF_ "GenMsgCycleTimeFast" 40 ;
BA_DEF_DEF_ "GenMsgDelayTime" 20 ;
BA_DEF_DEF_ "GenMsgILSupport" "Yes" ;
BA_DEF_DEF_ "GenMsgNrOfRepetition" 3 ;
BA_DEF_DEF_ "NmMessage" "No" ;
BA_DEF_DEF_ "NWM-Botschaft" "No" ;
BA_DEF_DEF_ "TpTxIndex" 0 ;
BA_DEF_DEF_ "VFrameFormat" "StandardCAN" ;
BA_DEF_DEF_ "UserSigValidity" "IG" ;
BA_DEF_DEF_ "TimeoutValue" "" ;
BA_DEF_DEF_ "UsrSigPurpose" "FN" ;
BA_DEF_DEF_ "GenSigStartValue" 0 ;
BA_DEF_DEF_ "NetworkRequest" "No" ;
BA_DEF_DEF_ "NetworkRequestHoldingTime" 0 ;
BA_DEF_DEF_ "Description" "" ;
BA_DEF_DEF_ "Version" "" ;
BA_DEF_DEF_ "GenSigEnvVarType" "Undef" ;
BA_DEF_DEF_ "GenSigSendType" "NoSigSendType" ;
BA_DEF_DEF_ "GwSigLatencyTime" 40 ;
BA_DEF_DEF_ "GwSigMissingSourceType" "Undef" ;
BA_DEF_DEF_ "NWM-WakeupAllowed" "<n.a.>" ;
BA_DEF_DEF_ "RoutingFactor" 1 ;
BA_DEF_DEF_REL_ "GenSigTimeoutTime" 500 ;
BA_ "GenMsgCycleTime" BO_ 2151682049 0;
BA_ "GenMsgDelayTime" BO_ 2151682049 10;
BA_ "VFrameFormat" BO_ 2151682049 1;
BA_ "Description" SG_ 2151682049 ACU_Crc2Val "The data area for CRC calculation is based on the data length (DLC) of the message DB.

The CRC shall be calculated over the entire data block (excluding the CRC bytes) including the user data, alive counter and Data ID

 

- CRC Polynomial (0x1021) , Initial Value : 0xFFFF, XOR value : 0x0000, Data ID : Message ID + 0xF800 

- The initial value is for CRC calculation and the message should be sent with the calculated result value. 

- The mathematical expression to 16 bit CRC polynomial is given here. G(x) = x16 + x12 + x5 + 1";
BA_ "GenSigSendType" SG_ 2151682049 ACU_Crc2Val 2;
BA_ "GenSigStartValue" SG_ 2151682049 ACU_Crc2Val 65535;
BA_ "UserSigValidity" SG_ 2151682049 ACU_Crc2Val 3;
BA_ "Version" SG_ 2151682049 ACU_Crc2Val "18.11.08";
BA_ "Description" SG_ 2151682049 ACU_AlvCnt2Val "For the first transmission request for a data element the counter shall be initialized with 0 and shall be incremented by 1 for every subsequent send request. 

When the counter reaches the maximum value(0xFF), then it shall restart with 0 for the next send request";
BA_ "GenSigSendType" SG_ 2151682049 ACU_AlvCnt2Val 2;
BA_ "UserSigValidity" SG_ 2151682049 ACU_AlvCnt2Val 3;
BA_ "Version" SG_ 2151682049 ACU_AlvCnt2Val "18.11.08";
BA_ "Description" SG_ 2151682049 ACU_CrshActvSta "Information regarding the crash. It indicates crash is active or inactive.";
BA_ "GenSigSendType" SG_ 2151682049 ACU_CrshActvSta 2;
BA_ "UserSigValidity" SG_ 2151682049 ACU_CrshActvSta 3;
BA_REL_ "GenSigTimeoutTime" BU_SG_REL_ APSM SG_ 2151682049 ACU_CrshActvSta 0;
BA_REL_ "GenSigTimeoutTime" BU_SG_REL_ RLPSM SG_ 2151682049 ACU_CrshActvSta 0;
BA_REL_ "GenSigTimeoutTime" BU_SG_REL_ RRPSM SG_ 2151682049 ACU_CrshActvSta 0;
BA_ "Version" SG_ 2151682049 ACU_CrshActvSta "17.12.00";
BA_ "Description" SG_ 2151682049 ACU_CrshInfo "1)When crash output is issued, this signal is transmitted as 0x2. 

2)When crash output is not issued and ACU meets MCB requirement of ESC.  this signal is transmitted as 0x1.



Just then If ACU receives feedback signal from ESC this signal is transmitted as 0x0.

If ACU do NOT receive feedback signal from ESC previous signal value is maintaned.



※This signal is transmmited until power-off";
BA_ "GenSigSendType" SG_ 2151682049 ACU_CrshInfo 2;
BA_ "UserSigValidity" SG_ 2151682049 ACU_CrshInfo 3;
BA_ "Version" SG_ 2151682049 ACU_CrshInfo "19.02.06";
BA_ "Description" SG_ 2151682049 ACU_CrshTyp "This signal indicates types of  crash. 

If a collision occurs continuously at same IGN cycle each crash type bit set to 1 according to the type of collision.



1)First byte Information 

xxxx xxxxB : No deployment Crash (Crash output signal not issued)

xxxx xxx1B : Front Crash (First stage only)

xxxx xx1xB : Front Crash (Full stage)

xxxx x1xxB : Side Crash (Driver side) 

xxxx 1xxxB : Side Crash (Passenger side)

xxx1 xxxxB : Rollover Crash (Restraints activation)

xx1x xxxxB : Rollover event information transmission (Restraints non-activation)

x1xx xxxxB : Side Crash Detection For Door Unlock (NON-SAB vehicle)

1xxx xxxxB : Rear Crash 

2)Second byte information 

xxxx xxx1B : Pre Crash (Pretentioner or Pretentioner + KAB)

other bits : RESERVED

※x means that Not set as 1

※For example, If Driver side crash occurs and then Front crash-full stage occurs  continuously, Type of crash bit set to 0000 0000 0000 0110B";
BA_ "GenSigSendType" SG_ 2151682049 ACU_CrshTyp 2;
BA_ "UserSigValidity" SG_ 2151682049 ACU_CrshTyp 3;
BA_ "Version" SG_ 2151682049 ACU_CrshTyp "19.02.06";
BA_ "GenMsgSendType" BO_ 2256642049 0;
BA_ "GenMsgCycleTime" BO_ 2256642049 100;
BA_ "GenMsgCycleTimeFast" BO_ 2256642049 0;
BA_ "GenMsgNrOfRepetition" BO_ 2256642049 0;
BA_ "VFrameFormat" BO_ 2256642049 1;
BA_ "Description" SG_ 2256642049 ADAS_CMD_Crc20Val "The data area for CRC calculation is based on the data length (DLC) of the message DB.

The CRC shall be calculated over the entire data block (excluding the CRC bytes) including the user data, alive counter and Data ID

 

- CRC Polynomial (0x1021) , Initial Value : 0xFFFF, XOR value : 0x0000, Data ID : Message ID + 0xF800 

- The initial value is for CRC calculation and the message should be sent with the calculated result value. 

- The mathematical expression to 16 bit CRC polynomial is given here. G(x) = x16 + x12 + x5 + 1";
BA_ "GenSigStartValue" SG_ 2256642049 ADAS_CMD_Crc20Val 65535;
BA_ "UserSigValidity" SG_ 2256642049 ADAS_CMD_Crc20Val 3;
BA_ "RoutingFactor" SG_ 2256642049 ADAS_CMD_Crc20Val 5;
BA_ "Version" SG_ 2256642049 ADAS_CMD_Crc20Val "18.11.08";
BA_ "Description" SG_ 2256642049 ADAS_CMD_AlvCnt20Val "For the first transmission request for a data element the counter shall be initialized with 0 and shall be incremented by 1 for every subsequent send request. 

When the counter reaches the maximum value(0xFF), then it shall restart with 0 for the next send request";
BA_ "UserSigValidity" SG_ 2256642049 ADAS_CMD_AlvCnt20Val 3;
BA_ "RoutingFactor" SG_ 2256642049 ADAS_CMD_AlvCnt20Val 5;
BA_ "Version" SG_ 2256642049 ADAS_CMD_AlvCnt20Val "18.11.08";
BA_ "Description" SG_ 2256642049 SCC_ObjDstVal "This signal provides the distance to the in lane detected SCC object regarding to the own vehicle.

- 자차선상의 전방 인식된 물체와의 거리";
BA_ "GenSigStartValue" SG_ 2256642049 SCC_ObjDstVal 2046;
BA_ "UserSigValidity" SG_ 2256642049 SCC_ObjDstVal 3;
BA_ "RoutingFactor" SG_ 2256642049 SCC_ObjDstVal 5;
BA_ "Version" SG_ 2256642049 SCC_ObjDstVal "21.01.08";
BA_ "Description" SG_ 2256642049 SCC_ObjRelSpdVal "This signal provides the relative speed to the in lane detected SCC object regarding to the own vehicle.

- 자차선상의 전방 인식된 물체와 자차간 상대 속도";
BA_ "GenSigStartValue" SG_ 2256642049 SCC_ObjRelSpdVal 4094;
BA_ "UserSigValidity" SG_ 2256642049 SCC_ObjRelSpdVal 3;
BA_ "RoutingFactor" SG_ 2256642049 SCC_ObjRelSpdVal 5;
BA_ "Version" SG_ 2256642049 SCC_ObjRelSpdVal "18.10.09";
BA_ "Description" SG_ 2256642049 SCC_ObjLatPosVal "This signal provides the lateral position of the detected SCC object regarding to the own vehicle. 

The position of the SCC object on the left side in driving direction of the vehicle longitudinal axis correlates with a negative signal value. 

Thus an SCC object on the right side in driving direction of the vehicle longitudinal axis correlates with a positive signal value.

- 자차선상의 전방 인식된 ?레의 횡방향 위치 값

- 자차기준 왼편 물체는 '-' 값, 오른편 물체는 '+' 값";
BA_ "GenSigStartValue" SG_ 2256642049 SCC_ObjLatPosVal 510;
BA_ "UserSigValidity" SG_ 2256642049 SCC_ObjLatPosVal 3;
BA_ "RoutingFactor" SG_ 2256642049 SCC_ObjLatPosVal 5;
BA_ "Version" SG_ 2256642049 SCC_ObjLatPosVal "18.10.09";
BA_ "GenMsgSendType" BO_ 2256642050 0;
BA_ "GenMsgCycleTime" BO_ 2256642050 100;
BA_ "GenMsgCycleTimeFast" BO_ 2256642050 0;
BA_ "GenMsgNrOfRepetition" BO_ 2256642050 0;
BA_ "VFrameFormat" BO_ 2256642050 1;
BA_ "Description" SG_ 2256642050 SCC_SysFlrSta "This signal is evaluated by the driver information device to release the failure information to the driver.

If this signal is set to anything other than 0, the TCS/ESC shall ignore any requests from SCC

- 시스템 고장 발생 정보용

- 해당 값이 0 이외의 모든 값 송출시 TCS/ESC 는 SCC 신호를 무시 할것.";
BA_ "UserSigValidity" SG_ 2256642050 SCC_SysFlrSta 3;
BA_ "RoutingFactor" SG_ 2256642050 SCC_SysFlrSta 5;
BA_ "Version" SG_ 2256642050 SCC_SysFlrSta "17.12.00";
BA_ "Description" SG_ 2256642050 SCC_InfoDis "This signal carries information that indicates below 4 signals.

(1) SCC Mode display

(2) CC Mode display

(3) Object disapearing display

(4) Go notifying display

- SCC 제어 상세 상태를 보여주는 정보 신호

(SCC 모드 / CC 모드 / 전방차량 주의 / 정차 출발 주의)";
BA_ "UserSigValidity" SG_ 2256642050 SCC_InfoDis 3;
BA_ "RoutingFactor" SG_ 2256642050 SCC_InfoDis 5;
BA_ "Version" SG_ 2256642050 SCC_InfoDis "18.10.09";
BA_ "Description" SG_ 2256642050 SCC_DrvAlrtDis "This signal carries the information which message shall be displayed to the driver 

when the SCC must be disengaged by the system or cann’t be engaged.

A signal value unequal 00H is repeated for 5 messages cycles in order to ensure it appears for at least 100ms on the bus 

(Output period of SCC1 is 20ms).

- SCC 제어 진입이 어려운 상황 또는 차량 정차 상태등 운전자 경보 필요시 송출 하는 신호";
BA_ "UserSigValidity" SG_ 2256642050 SCC_DrvAlrtDis 3;
BA_ "RoutingFactor" SG_ 2256642050 SCC_DrvAlrtDis 5;
BA_ "Version" SG_ 2256642050 SCC_DrvAlrtDis "19.07.02";
BA_ "Description" SG_ 2256642050 SCC_MainOnOffSta "This signal specifies the status of a Main switch of SCC system

- Main swith 에 의한 SCC ON/OFF 상태 정보";
BA_ "UserSigValidity" SG_ 2256642050 SCC_MainOnOffSta 3;
BA_ "RoutingFactor" SG_ 2256642050 SCC_MainOnOffSta 5;
BA_ "Version" SG_ 2256642050 SCC_MainOnOffSta "17.12.00";
BA_ "Description" SG_ 2256642050 SCC_HeadwayDstSetVal "The desired time gap from which a following distance is extracted has to be presented to the driver at least if the value changes. 

The representation of the information depends on the display concept.

- Information on setting the distance from the vehicle ahead

※ SCC-ML: SCC Machine Learning

※ For models not based on Drive Mode., 0xE is the unused signal (the value corresponding to SCC-ML Active is replaced by 0x6 to 0x9 values).";
BA_ "UserSigValidity" SG_ 2256642050 SCC_HeadwayDstSetVal 3;
BA_ "RoutingFactor" SG_ 2256642050 SCC_HeadwayDstSetVal 5;
BA_ "Version" SG_ 2256642050 SCC_HeadwayDstSetVal "20.10.00";
BA_ "Description" SG_ 2256642050 SCC_NSCCAutoSetSpdSta "This is information if Auto Set Speed Control is enabled or not.";
BA_ "UserSigValidity" SG_ 2256642050 SCC_NSCCAutoSetSpdSta 3;
BA_ "RoutingFactor" SG_ 2256642050 SCC_NSCCAutoSetSpdSta 5;
BA_ "Version" SG_ 2256642050 SCC_NSCCAutoSetSpdSta "20.06.09";
BA_ "Description" SG_ 2256642050 SCC_TrgtSpdSetVal "The desired vehicle speed for free cruising has to be displayed all the time SCC is under active control.

※This signal can be sent in km/h or MPH according to the “SPEED_UNIT” signal (See CLU1 message).

SPEED_UNIT = 0 : [km/h], SPEED_UNIT = 1 : [MPH]

- 운전자가 설정한 차속 정보";
BA_ "UserSigValidity" SG_ 2256642050 SCC_TrgtSpdSetVal 3;
BA_ "RoutingFactor" SG_ 2256642050 SCC_TrgtSpdSetVal 5;
BA_ "Version" SG_ 2256642050 SCC_TrgtSpdSetVal "17.12.00";
BA_ "Description" SG_ 2256642050 SCC_OpSta "The signal ACCmode specifies the operational mode of SCC

- ACC 작동 상태 정보(off&ready / active / override / shut off)";
BA_ "GenSigStartValue" SG_ 2256642050 SCC_OpSta 3;
BA_ "UserSigValidity" SG_ 2256642050 SCC_OpSta 3;
BA_ "RoutingFactor" SG_ 2256642050 SCC_OpSta 5;
BA_ "Version" SG_ 2256642050 SCC_OpSta "19.04.02";
BA_ "Description" SG_ 2256642050 SCC_NSCCOpSta "This signal describes the operational status of NSCC-Z/C/R function. 



NSCC-Z/C/R  작동 상태 정보(off/ready/active)";
BA_ "UserSigValidity" SG_ 2256642050 SCC_NSCCOpSta 3;
BA_ "RoutingFactor" SG_ 2256642050 SCC_NSCCOpSta 5;
BA_ "Version" SG_ 2256642050 SCC_NSCCOpSta "17.12.00";
BA_ "Description" SG_ 2256642050 SCC_NSCCOnOffSta "This signal describes the on/off status of NSCC-Z/C/R and HDA Auto-set function. 



NSCC-Z/C/R  and HDA auto-set on/off 상태 정보";
BA_ "UserSigValidity" SG_ 2256642050 SCC_NSCCOnOffSta 3;
BA_ "RoutingFactor" SG_ 2256642050 SCC_NSCCOnOffSta 5;
BA_ "Version" SG_ 2256642050 SCC_NSCCOnOffSta "17.12.00";
BA_ "Description" SG_ 2256642050 SCC_ObjSta "This signal represents the state of in-path object and information of controllable state.

- 자차선상의 전방 차량 인식 여부 및 제어 가능 상태 정보";
BA_ "UserSigValidity" SG_ 2256642050 SCC_ObjSta 3;
BA_ "RoutingFactor" SG_ 2256642050 SCC_ObjSta 5;
BA_ "Version" SG_ 2256642050 SCC_ObjSta "19.07.02";
BA_ "Description" SG_ 2256642050 SCC_NSCCAutoSetSpdUpdtSta "This is information if Auto Set Speed Control is updated or not.";
BA_ "UserSigValidity" SG_ 2256642050 SCC_NSCCAutoSetSpdUpdtSta 3;
BA_ "RoutingFactor" SG_ 2256642050 SCC_NSCCAutoSetSpdUpdtSta 5;
BA_ "Version" SG_ 2256642050 SCC_NSCCAutoSetSpdUpdtSta "18.10.02";
BA_ "Description" SG_ 2256642050 SCC_NSCCInfoPUDis "This signal shows the cluster pop-up for NSCC Information.";
BA_ "UserSigValidity" SG_ 2256642050 SCC_NSCCInfoPUDis 3;
BA_ "RoutingFactor" SG_ 2256642050 SCC_NSCCInfoPUDis 5;
BA_ "Version" SG_ 2256642050 SCC_NSCCInfoPUDis "18.10.02";
BA_ "Description" SG_ 2256642050 SCC_TakeoverReq "The Take-over Request supports the driver to identify the limits of the SCC control. Reasons for such a request may be:

- Deceleration capability insufficient for the current situation.

Clutch actuation by the driver is necessary to avoid stopping of the engine. This signal shall activate an audible and visual alert

- 감속상황에서 SCC 시스템만으로 감속이 어려운 한계상황 발생시 운전자에게 개입(제동)을 요청하는 경고 신호

- 청각 / 시각적으로 경고 필요";
BA_ "UserSigValidity" SG_ 2256642050 SCC_TakeoverReq 3;
BA_REL_ "GenSigTimeoutTime" BU_SG_REL_ AMP SG_ 2256642050 SCC_TakeoverReq 1500;
BA_ "RoutingFactor" SG_ 2256642050 SCC_TakeoverReq 5;
BA_ "Version" SG_ 2256642050 SCC_TakeoverReq "17.12.00";
BA_ "GenMsgSendType" BO_ 2256642051 0;
BA_ "GenMsgCycleTime" BO_ 2256642051 100;
BA_ "GenMsgCycleTimeFast" BO_ 2256642051 0;
BA_ "GenMsgNrOfRepetition" BO_ 2256642051 0;
BA_ "VFrameFormat" BO_ 2256642051 1;
BA_ "Description" SG_ 2256642051 SCC_AccelReqVal "This signal represents the SCC acceleration request after jerk limit.

- Jerk limit를 거친 SCC 의 요구 가속도/감속도 값";
BA_ "UserSigValidity" SG_ 2256642051 SCC_AccelReqVal 3;
BA_ "RoutingFactor" SG_ 2256642051 SCC_AccelReqVal 5;
BA_ "Version" SG_ 2256642051 SCC_AccelReqVal "17.12.00";
BA_ "Description" SG_ 2256642051 SCC_AccelReqRawVal "This signal represents the SCC acceleration request before jerk limit. 

- Jerk limit를 거치지 않은 SCC 의 요구 가속도/감속도 값";
BA_ "UserSigValidity" SG_ 2256642051 SCC_AccelReqRawVal 3;
BA_ "RoutingFactor" SG_ 2256642051 SCC_AccelReqRawVal 5;
BA_ "Version" SG_ 2256642051 SCC_AccelReqRawVal "17.12.00";
BA_ "Description" SG_ 2256642051 SCC_JrkUppLimVal "This signal is the value of positive jerk limit request. 

- SCC 의 요구 가속도 상승변화율 제한 값";
BA_ "UserSigValidity" SG_ 2256642051 SCC_JrkUppLimVal 3;
BA_ "RoutingFactor" SG_ 2256642051 SCC_JrkUppLimVal 5;
BA_ "Version" SG_ 2256642051 SCC_JrkUppLimVal "17.12.00";
BA_ "Description" SG_ 2256642051 SCC_JrkLwrLimVal "This signal is the value of negative jerk limit request. 

- SCC 의 요구 가속도 하강변화율 제한 값";
BA_ "UserSigValidity" SG_ 2256642051 SCC_JrkLwrLimVal 3;
BA_ "RoutingFactor" SG_ 2256642051 SCC_JrkLwrLimVal 5;
BA_ "Version" SG_ 2256642051 SCC_JrkLwrLimVal "17.12.00";
BA_ "Description" SG_ 2256642051 SCC_AccelLimBandUppVal "This signal is the upper value of acceleration limit band.

- SCC 의 가속도 제어 허용 범위 상한 참고값";
BA_ "UserSigValidity" SG_ 2256642051 SCC_AccelLimBandUppVal 3;
BA_ "RoutingFactor" SG_ 2256642051 SCC_AccelLimBandUppVal 5;
BA_ "Version" SG_ 2256642051 SCC_AccelLimBandUppVal "17.12.03";
BA_ "Description" SG_ 2256642051 SCC_AccelLimBandLwrVal "This signal is the lower value of acceleration limit band.

- SCC 의 가속도 제어 허용 범위 하한 참고값";
BA_ "UserSigValidity" SG_ 2256642051 SCC_AccelLimBandLwrVal 3;
BA_ "RoutingFactor" SG_ 2256642051 SCC_AccelLimBandLwrVal 5;
BA_ "Version" SG_ 2256642051 SCC_AccelLimBandLwrVal "17.12.03";
BA_ "Description" SG_ 2256642051 SCC_VehStpReq "A control request flag for vehicle stop. SCC expects vehicle to be controlled to a complete stop and hold its state.

- SCC 해제 상황 발생시 차량 정차 유지를 위한 제동 요청 신호";
BA_ "UserSigValidity" SG_ 2256642051 SCC_VehStpReq 3;
BA_ "RoutingFactor" SG_ 2256642051 SCC_VehStpReq 5;
BA_ "Version" SG_ 2256642051 SCC_VehStpReq "17.12.00";
BA_ "Description" SG_ 2256642051 SCC_EngStateReq "This signal indicates engine state request of SCC.

 - 0x0 : SCC deactive or SCC off

 - 0x1 : 'ISG Stop' Possible

 - 0x2 : 'ISG Start or Maintain Engine Run' Request

 - 0x3 : Reserved";
BA_ "UserSigValidity" SG_ 2256642051 SCC_EngStateReq 3;
BA_ "RoutingFactor" SG_ 2256642051 SCC_EngStateReq 5;
BA_ "Version" SG_ 2256642051 SCC_EngStateReq "19.01.04";
BA_ "GenMsgSendType" BO_ 2256642052 0;
BA_ "GenMsgCycleTime" BO_ 2256642052 100;
BA_ "GenMsgCycleTimeFast" BO_ 2256642052 0;
BA_ "GenMsgNrOfRepetition" BO_ 2256642052 0;
BA_ "VFrameFormat" BO_ 2256642052 1;
BA_ "Description" SG_ 2256642052 SCC_TrgtDstVal "This signal provides the target distance for SCC fallowing control.

- SCC 거리 제어를 위한 목표 차간 거리 정보";
BA_ "GenSigStartValue" SG_ 2256642052 SCC_TrgtDstVal 2046;
BA_ "UserSigValidity" SG_ 2256642052 SCC_TrgtDstVal 3;
BA_ "RoutingFactor" SG_ 2256642052 SCC_TrgtDstVal 5;
BA_ "Version" SG_ 2256642052 SCC_TrgtDstVal "20.01.01";
BA_ "Description" SG_ 2256642052 HDP_LongActvSta "This signal indicates HDP control status For longitudinal control.";
BA_ "UserSigValidity" SG_ 2256642052 HDP_LongActvSta 3;
BA_ "RoutingFactor" SG_ 2256642052 HDP_LongActvSta 5;
BA_ "Version" SG_ 2256642052 HDP_LongActvSta "20.06.02";
BA_ "Description" SG_ 2256642052 HDP_MRMCtrlSta "This signal indicates Minimum Risk Maneuver control status of HDP.";
BA_ "UserSigValidity" SG_ 2256642052 HDP_MRMCtrlSta 3;
BA_ "RoutingFactor" SG_ 2256642052 HDP_MRMCtrlSta 5;
BA_ "Version" SG_ 2256642052 HDP_MRMCtrlSta "21.01.08";
BA_ "Description" SG_ 2256642052 HDP_ESCOnReq "This signal indicates ESC function on request.";
BA_ "UserSigValidity" SG_ 2256642052 HDP_ESCOnReq 3;
BA_ "RoutingFactor" SG_ 2256642052 HDP_ESCOnReq 5;
BA_ "Version" SG_ 2256642052 HDP_ESCOnReq "20.06.02";
BA_ "Description" SG_ 2256642052 HDP_AccelOvrdLmt "This signal indicates acceleration override limited.";
BA_ "UserSigValidity" SG_ 2256642052 HDP_AccelOvrdLmt 3;
BA_ "RoutingFactor" SG_ 2256642052 HDP_AccelOvrdLmt 5;
BA_ "Version" SG_ 2256642052 HDP_AccelOvrdLmt "19.11.02";
BA_ "GenMsgCycleTime" BO_ 1931 0;
BA_ "GenMsgCycleTimeFast" BO_ 1931 0;
BA_ "GenMsgNrOfRepetition" BO_ 1931 0;
BA_ "DiagResponse" BO_ 1931 1;
BA_ "GenMsgILSupport" BO_ 1931 0;
BA_ "TpMessage" BO_ 1931 1;
BA_ "TpTxIndex" BO_ 1931 16;
BA_ "Description" SG_ 1931 AMP_GST_Byte0 "TP Index : 16";
BA_ "UsrSigPurpose" SG_ 1931 AMP_GST_Byte0 4;
BA_ "UserSigValidity" SG_ 1931 AMP_GST_Byte0 0;
BA_REL_ "GenSigTimeoutTime" BU_SG_REL_ CGW_CCU SG_ 1931 AMP_GST_Byte0 0;
BA_ "NetworkRequest" SG_ 1931 AMP_GST_Byte0 0;
BA_ "NetworkRequestHoldingTime" SG_ 1931 AMP_GST_Byte0 5000;
BA_ "Version" SG_ 1931 AMP_GST_Byte0 "21.02.04";
BA_ "Description" SG_ 1931 AMP_GST_Byte2 "TP Index : 16";
BA_ "UsrSigPurpose" SG_ 1931 AMP_GST_Byte2 4;
BA_ "UserSigValidity" SG_ 1931 AMP_GST_Byte2 0;
BA_REL_ "GenSigTimeoutTime" BU_SG_REL_ CGW_CCU SG_ 1931 AMP_GST_Byte2 0;
BA_ "NetworkRequest" SG_ 1931 AMP_GST_Byte2 0;
BA_ "NetworkRequestHoldingTime" SG_ 1931 AMP_GST_Byte2 5000;
BA_ "Version" SG_ 1931 AMP_GST_Byte2 "21.02.04";
BA_ "Description" SG_ 1931 AMP_GST_Byte3 "TP Index : 16";
BA_ "UsrSigPurpose" SG_ 1931 AMP_GST_Byte3 4;
BA_ "UserSigValidity" SG_ 1931 AMP_GST_Byte3 0;
BA_REL_ "GenSigTimeoutTime" BU_SG_REL_ CGW_CCU SG_ 1931 AMP_GST_Byte3 0;
BA_ "NetworkRequest" SG_ 1931 AMP_GST_Byte3 0;
BA_ "NetworkRequestHoldingTime" SG_ 1931 AMP_GST_Byte3 5000;
BA_ "Version" SG_ 1931 AMP_GST_Byte3 "21.02.04";
BA_ "Description" SG_ 1931 AMP_GST_Byte4 "TP Index : 16";
BA_ "UsrSigPurpose" SG_ 1931 AMP_GST_Byte4 4;
BA_ "UserSigValidity" SG_ 1931 AMP_GST_Byte4 0;
BA_REL_ "GenSigTimeoutTime" BU_SG_REL_ CGW_CCU SG_ 1931 AMP_GST_Byte4 0;
BA_ "NetworkRequest" SG_ 1931 AMP_GST_Byte4 0;
BA_ "NetworkRequestHoldingTime" SG_ 1931 AMP_GST_Byte4 5000;
BA_ "Version" SG_ 1931 AMP_GST_Byte4 "21.02.04";
BA_ "Description" SG_ 1931 AMP_GST_Byte5 "TP Index : 16";
BA_ "UsrSigPurpose" SG_ 1931 AMP_GST_Byte5 4;
BA_ "UserSigValidity" SG_ 1931 AMP_GST_Byte5 0;
BA_REL_ "GenSigTimeoutTime" BU_SG_REL_ CGW_CCU SG_ 1931 AMP_GST_Byte5 0;
BA_ "NetworkRequest" SG_ 1931 AMP_GST_Byte5 0;
BA_ "NetworkRequestHoldingTime" SG_ 1931 AMP_GST_Byte5 5000;
BA_ "Version" SG_ 1931 AMP_GST_Byte5 "21.02.04";
BA_ "Description" SG_ 1931 AMP_GST_Byte6 "TP Index : 16";
BA_ "UsrSigPurpose" SG_ 1931 AMP_GST_Byte6 4;
BA_ "UserSigValidity" SG_ 1931 AMP_GST_Byte6 0;
BA_REL_ "GenSigTimeoutTime" BU_SG_REL_ CGW_CCU SG_ 1931 AMP_GST_Byte6 0;
BA_ "NetworkRequest" SG_ 1931 AMP_GST_Byte6 0;
BA_ "NetworkRequestHoldingTime" SG_ 1931 AMP_GST_Byte6 5000;
BA_ "Version" SG_ 1931 AMP_GST_Byte6 "21.02.04";
BA_ "Description" SG_ 1931 AMP_GST_Byte7 "TP Index : 16";
BA_ "UsrSigPurpose" SG_ 1931 AMP_GST_Byte7 4;
BA_ "UserSigValidity" SG_ 1931 AMP_GST_Byte7 0;
BA_REL_ "GenSigTimeoutTime" BU_SG_REL_ CGW_CCU SG_ 1931 AMP_GST_Byte7 0;
BA_ "NetworkRequest" SG_ 1931 AMP_GST_Byte7 0;
BA_ "NetworkRequestHoldingTime" SG_ 1931 AMP_GST_Byte7 5000;
BA_ "Version" SG_ 1931 AMP_GST_Byte7 "21.02.04";
BA_ "Description" SG_ 1931 AMP_GST_Byte1 "TP Index : 16";
BA_ "UsrSigPurpose" SG_ 1931 AMP_GST_Byte1 4;
BA_ "UserSigValidity" SG_ 1931 AMP_GST_Byte1 0;
BA_REL_ "GenSigTimeoutTime" BU_SG_REL_ CGW_CCU SG_ 1931 AMP_GST_Byte1 0;
BA_ "NetworkRequest" SG_ 1931 AMP_GST_Byte1 0;
BA_ "NetworkRequestHoldingTime" SG_ 1931 AMP_GST_Byte1 5000;
BA_ "Version" SG_ 1931 AMP_GST_Byte1 "21.02.04";
BA_ "GenMsgSendType" BO_ 981 0;
BA_ "Description" SG_ 981 APSS_StSldFwdMvBtn "조수석 슬라이딩 포워드 버튼";
BA_ "GenSigSendType" SG_ 981 APSS_StSldFwdMvBtn 4;
BA_ "UserSigValidity" SG_ 981 APSS_StSldFwdMvBtn 0;
BA_REL_ "GenSigTimeoutTime" BU_SG_REL_ APSM SG_ 981 APSS_StSldFwdMvBtn 1500;
BA_REL_ "GenSigTimeoutTime" BU_SG_REL_ RRPSM SG_ 981 APSS_StSldFwdMvBtn 1500;
BA_REL_ "GenSigTimeoutTime" BU_SG_REL_ CGW_CCU SG_ 981 APSS_StSldFwdMvBtn 1500;
BA_ "NetworkRequest" SG_ 981 APSS_StSldFwdMvBtn 0;
BA_ "NetworkRequestHoldingTime" SG_ 981 APSS_StSldFwdMvBtn 5000;
BA_ "Version" SG_ 981 APSS_StSldFwdMvBtn "20.03.01";
BA_ "Description" SG_ 981 APSS_StSldBwdMvBtn "조수석 슬라이딩 백워드 버튼";
BA_ "GenSigSendType" SG_ 981 APSS_StSldBwdMvBtn 4;
BA_ "UserSigValidity" SG_ 981 APSS_StSldBwdMvBtn 0;
BA_REL_ "GenSigTimeoutTime" BU_SG_REL_ APSM SG_ 981 APSS_StSldBwdMvBtn 1500;
BA_REL_ "GenSigTimeoutTime" BU_SG_REL_ RRPSM SG_ 981 APSS_StSldBwdMvBtn 1500;
BA_REL_ "GenSigTimeoutTime" BU_SG_REL_ CGW_CCU SG_ 981 APSS_StSldBwdMvBtn 1500;
BA_ "NetworkRequest" SG_ 981 APSS_StSldBwdMvBtn 0;
BA_ "NetworkRequestHoldingTime" SG_ 981 APSS_StSldBwdMvBtn 5000;
BA_ "Version" SG_ 981 APSS_StSldBwdMvBtn "20.03.01";
BA_ "Description" SG_ 981 APSS_StRclFwdMvBtn "조수석 리클라이닝 포워드 버튼";
BA_ "GenSigSendType" SG_ 981 APSS_StRclFwdMvBtn 4;
BA_ "UserSigValidity" SG_ 981 APSS_StRclFwdMvBtn 0;
BA_REL_ "GenSigTimeoutTime" BU_SG_REL_ APSM SG_ 981 APSS_StRclFwdMvBtn 1500;
BA_REL_ "GenSigTimeoutTime" BU_SG_REL_ RRPSM SG_ 981 APSS_StRclFwdMvBtn 1500;
BA_REL_ "GenSigTimeoutTime" BU_SG_REL_ CGW_CCU SG_ 981 APSS_StRclFwdMvBtn 1500;
BA_ "NetworkRequest" SG_ 981 APSS_StRclFwdMvBtn 0;
BA_ "NetworkRequestHoldingTime" SG_ 981 APSS_StRclFwdMvBtn 5000;
BA_ "Version" SG_ 981 APSS_StRclFwdMvBtn "20.03.01";
BA_ "Description" SG_ 981 APSS_StRclBwdMvBtn "조수석 리클라이닝 백워드 버튼";
BA_ "GenSigSendType" SG_ 981 APSS_StRclBwdMvBtn 4;
BA_ "UserSigValidity" SG_ 981 APSS_StRclBwdMvBtn 0;
BA_REL_ "GenSigTimeoutTime" BU_SG_REL_ APSM SG_ 981 APSS_StRclBwdMvBtn 1500;
BA_REL_ "GenSigTimeoutTime" BU_SG_REL_ RRPSM SG_ 981 APSS_StRclBwdMvBtn 1500;
BA_REL_ "GenSigTimeoutTime" BU_SG_REL_ CGW_CCU SG_ 981 APSS_StRclBwdMvBtn 1500;
BA_ "NetworkRequest" SG_ 981 APSS_StRclBwdMvBtn 0;
BA_ "NetworkRequestHoldingTime" SG_ 981 APSS_StRclBwdMvBtn 5000;
BA_ "Version" SG_ 981 APSS_StRclBwdMvBtn "20.03.01";
BA_ "Description" SG_ 981 APSS_StHgtUpMvBtn "조수석 하이트 업 버튼";
BA_ "GenSigSendType" SG_ 981 APSS_StHgtUpMvBtn 4;
BA_ "UserSigValidity" SG_ 981 APSS_StHgtUpMvBtn 0;
BA_REL_ "GenSigTimeoutTime" BU_SG_REL_ APSM SG_ 981 APSS_StHgtUpMvBtn 1500;
BA_REL_ "GenSigTimeoutTime" BU_SG_REL_ RRPSM SG_ 981 APSS_StHgtUpMvBtn 1500;
BA_REL_ "GenSigTimeoutTime" BU_SG_REL_ CGW_CCU SG_ 981 APSS_StHgtUpMvBtn 1500;
BA_ "NetworkRequest" SG_ 981 APSS_StHgtUpMvBtn 0;
BA_ "NetworkRequestHoldingTime" SG_ 981 APSS_StHgtUpMvBtn 5000;
BA_ "Version" SG_ 981 APSS_StHgtUpMvBtn "20.03.01";
BA_ "Description" SG_ 981 APSS_StHgtDnMvBtn "조수석 하이트 다운 버튼";
BA_ "GenSigSendType" SG_ 981 APSS_StHgtDnMvBtn 4;
BA_ "UserSigValidity" SG_ 981 APSS_StHgtDnMvBtn 0;
BA_REL_ "GenSigTimeoutTime" BU_SG_REL_ APSM SG_ 981 APSS_StHgtDnMvBtn 1500;
BA_REL_ "GenSigTimeoutTime" BU_SG_REL_ RRPSM SG_ 981 APSS_StHgtDnMvBtn 1500;
BA_REL_ "GenSigTimeoutTime" BU_SG_REL_ CGW_CCU SG_ 981 APSS_StHgtDnMvBtn 1500;
BA_ "NetworkRequest" SG_ 981 APSS_StHgtDnMvBtn 0;
BA_ "NetworkRequestHoldingTime" SG_ 981 APSS_StHgtDnMvBtn 5000;
BA_ "Version" SG_ 981 APSS_StHgtDnMvBtn "20.03.01";
BA_ "Description" SG_ 981 APSS_StTltUpMvBtn "조수석 틸트 업 버튼";
BA_ "GenSigSendType" SG_ 981 APSS_StTltUpMvBtn 4;
BA_ "UserSigValidity" SG_ 981 APSS_StTltUpMvBtn 0;
BA_REL_ "GenSigTimeoutTime" BU_SG_REL_ APSM SG_ 981 APSS_StTltUpMvBtn 1500;
BA_REL_ "GenSigTimeoutTime" BU_SG_REL_ CGW_CCU SG_ 981 APSS_StTltUpMvBtn 1500;
BA_ "NetworkRequest" SG_ 981 APSS_StTltUpMvBtn 0;
BA_ "NetworkRequestHoldingTime" SG_ 981 APSS_StTltUpMvBtn 5000;
BA_ "Version" SG_ 981 APSS_StTltUpMvBtn "20.03.01";
BA_ "Description" SG_ 981 APSS_StTltDnMvBtn "조수석 틸트 다운 버튼";
BA_ "GenSigSendType" SG_ 981 APSS_StTltDnMvBtn 4;
BA_ "UserSigValidity" SG_ 981 APSS_StTltDnMvBtn 0;
BA_REL_ "GenSigTimeoutTime" BU_SG_REL_ APSM SG_ 981 APSS_StTltDnMvBtn 1500;
BA_REL_ "GenSigTimeoutTime" BU_SG_REL_ CGW_CCU SG_ 981 APSS_StTltDnMvBtn 1500;
BA_ "NetworkRequest" SG_ 981 APSS_StTltDnMvBtn 0;
BA_ "NetworkRequestHoldingTime" SG_ 981 APSS_StTltDnMvBtn 5000;
BA_ "Version" SG_ 981 APSS_StTltDnMvBtn "20.03.01";
BA_ "Description" SG_ 981 APSS_StHRestUpMvBtn "동승석 헤드레스트 up 버튼";
BA_ "GenSigSendType" SG_ 981 APSS_StHRestUpMvBtn 4;
BA_ "UserSigValidity" SG_ 981 APSS_StHRestUpMvBtn 0;
BA_REL_ "GenSigTimeoutTime" BU_SG_REL_ APSM SG_ 981 APSS_StHRestUpMvBtn 1500;
BA_REL_ "GenSigTimeoutTime" BU_SG_REL_ CGW_CCU SG_ 981 APSS_StHRestUpMvBtn 1500;
BA_ "NetworkRequest" SG_ 981 APSS_StHRestUpMvBtn 0;
BA_ "NetworkRequestHoldingTime" SG_ 981 APSS_StHRestUpMvBtn 5000;
BA_ "Version" SG_ 981 APSS_StHRestUpMvBtn "20.03.01";
BA_ "Description" SG_ 981 APSS_StHRestDnMvBtn "동승석 헤드레스트 down 버튼";
BA_ "GenSigSendType" SG_ 981 APSS_StHRestDnMvBtn 4;
BA_ "UserSigValidity" SG_ 981 APSS_StHRestDnMvBtn 0;
BA_REL_ "GenSigTimeoutTime" BU_SG_REL_ APSM SG_ 981 APSS_StHRestDnMvBtn 1500;
BA_REL_ "GenSigTimeoutTime" BU_SG_REL_ CGW_CCU SG_ 981 APSS_StHRestDnMvBtn 1500;
BA_ "NetworkRequest" SG_ 981 APSS_StHRestDnMvBtn 0;
BA_ "NetworkRequestHoldingTime" SG_ 981 APSS_StHRestDnMvBtn 5000;
BA_ "Version" SG_ 981 APSS_StHRestDnMvBtn "20.03.01";
BA_ "Description" SG_ 981 APSS_StHRestFwdMvBtn "동승석 헤드레스트 fwd 버튼";
BA_ "GenSigSendType" SG_ 981 APSS_StHRestFwdMvBtn 4;
BA_ "UserSigValidity" SG_ 981 APSS_StHRestFwdMvBtn 0;
BA_REL_ "GenSigTimeoutTime" BU_SG_REL_ APSM SG_ 981 APSS_StHRestFwdMvBtn 1500;
BA_REL_ "GenSigTimeoutTime" BU_SG_REL_ CGW_CCU SG_ 981 APSS_StHRestFwdMvBtn 1500;
BA_ "NetworkRequest" SG_ 981 APSS_StHRestFwdMvBtn 0;
BA_ "NetworkRequestHoldingTime" SG_ 981 APSS_StHRestFwdMvBtn 5000;
BA_ "Version" SG_ 981 APSS_StHRestFwdMvBtn "20.03.01";
BA_ "Description" SG_ 981 APSS_StHRestBwdMvBtn "동승석 헤드레스트 BWD 버튼";
BA_ "GenSigSendType" SG_ 981 APSS_StHRestBwdMvBtn 4;
BA_ "UserSigValidity" SG_ 981 APSS_StHRestBwdMvBtn 0;
BA_REL_ "GenSigTimeoutTime" BU_SG_REL_ APSM SG_ 981 APSS_StHRestBwdMvBtn 1500;
BA_REL_ "GenSigTimeoutTime" BU_SG_REL_ CGW_CCU SG_ 981 APSS_StHRestBwdMvBtn 1500;
BA_ "NetworkRequest" SG_ 981 APSS_StHRestBwdMvBtn 0;
BA_ "NetworkRequestHoldingTime" SG_ 981 APSS_StHRestBwdMvBtn 5000;
BA_ "Version" SG_ 981 APSS_StHRestBwdMvBtn "20.03.01";
BA_ "Description" SG_ 981 APSS_StLegUpMvBtn "조수석 레그레스트 업 버튼";
BA_ "GenSigSendType" SG_ 981 APSS_StLegUpMvBtn 4;
BA_ "UserSigValidity" SG_ 981 APSS_StLegUpMvBtn 0;
BA_ "NetworkRequest" SG_ 981 APSS_StLegUpMvBtn 0;
BA_ "NetworkRequestHoldingTime" SG_ 981 APSS_StLegUpMvBtn 5000;
BA_ "Version" SG_ 981 APSS_StLegUpMvBtn "20.03.01";
BA_ "Description" SG_ 981 APSS_StLegDnMvBtn "조수석 레그레스트 다운 버튼";
BA_ "GenSigSendType" SG_ 981 APSS_StLegDnMvBtn 4;
BA_ "UserSigValidity" SG_ 981 APSS_StLegDnMvBtn 0;
BA_ "NetworkRequest" SG_ 981 APSS_StLegDnMvBtn 0;
BA_ "NetworkRequestHoldingTime" SG_ 981 APSS_StLegDnMvBtn 5000;
BA_ "Version" SG_ 981 APSS_StLegDnMvBtn "20.03.01";
BA_ "Description" SG_ 981 APSS_StRlxModeBtn "조수석 릴렉스 모드 버튼";
BA_ "GenSigSendType" SG_ 981 APSS_StRlxModeBtn 4;
BA_ "UserSigValidity" SG_ 981 APSS_StRlxModeBtn 0;
BA_ "NetworkRequest" SG_ 981 APSS_StRlxModeBtn 0;
BA_ "NetworkRequestHoldingTime" SG_ 981 APSS_StRlxModeBtn 5000;
BA_ "Version" SG_ 981 APSS_StRlxModeBtn "20.03.01";
BA_ "Description" SG_ 981 APSS_StRlxReturnBtn "조수석 릴렉스 리턴 버튼";
BA_ "GenSigSendType" SG_ 981 APSS_StRlxReturnBtn 4;
BA_ "UserSigValidity" SG_ 981 APSS_StRlxReturnBtn 0;
BA_ "NetworkRequest" SG_ 981 APSS_StRlxReturnBtn 0;
BA_ "NetworkRequestHoldingTime" SG_ 981 APSS_StRlxReturnBtn 5000;
BA_ "Version" SG_ 981 APSS_StRlxReturnBtn "20.03.01";
BA_ "Description" SG_ 981 APSS_StRlxTltUpMvBtn "조수석 릴렉스 틸트 업 버튼";
BA_ "GenSigSendType" SG_ 981 APSS_StRlxTltUpMvBtn 4;
BA_ "UserSigValidity" SG_ 981 APSS_StRlxTltUpMvBtn 0;
BA_ "NetworkRequest" SG_ 981 APSS_StRlxTltUpMvBtn 0;
BA_ "NetworkRequestHoldingTime" SG_ 981 APSS_StRlxTltUpMvBtn 5000;
BA_ "Version" SG_ 981 APSS_StRlxTltUpMvBtn "20.03.01";
BA_ "Description" SG_ 981 APSS_StRlxTltDnMvBtn "조수석 릴렉스 틸트 다운 버튼";
BA_ "GenSigSendType" SG_ 981 APSS_StRlxTltDnMvBtn 4;
BA_ "UserSigValidity" SG_ 981 APSS_StRlxTltDnMvBtn 0;
BA_ "NetworkRequest" SG_ 981 APSS_StRlxTltDnMvBtn 0;
BA_ "NetworkRequestHoldingTime" SG_ 981 APSS_StRlxTltDnMvBtn 5000;
BA_ "Version" SG_ 981 APSS_StRlxTltDnMvBtn "20.03.01";
BA_ "GenMsgCycleTime" BO_ 1951 0;
BA_ "GenMsgCycleTimeFast" BO_ 1951 0;
BA_ "GenMsgNrOfRepetition" BO_ 1951 0;
BA_ "DiagResponse" BO_ 1951 1;
BA_ "GenMsgILSupport" BO_ 1951 0;
BA_ "TpMessage" BO_ 1951 1;
BA_ "TpTxIndex" BO_ 1951 109;
BA_ "Description" SG_ 1951 APSU_GST_Byte0 "TP Index : 109";
BA_ "UsrSigPurpose" SG_ 1951 APSU_GST_Byte0 4;
BA_ "UserSigValidity" SG_ 1951 APSU_GST_Byte0 0;
BA_REL_ "GenSigTimeoutTime" BU_SG_REL_ CGW_CCU SG_ 1951 APSU_GST_Byte0 0;
BA_ "NetworkRequest" SG_ 1951 APSU_GST_Byte0 0;
BA_ "NetworkRequestHoldingTime" SG_ 1951 APSU_GST_Byte0 5000;
BA_ "Version" SG_ 1951 APSU_GST_Byte0 "21.02.04";
BA_ "Description" SG_ 1951 APSU_GST_Byte2 "TP Index : 109";
BA_ "UsrSigPurpose" SG_ 1951 APSU_GST_Byte2 4;
BA_ "UserSigValidity" SG_ 1951 APSU_GST_Byte2 0;
BA_REL_ "GenSigTimeoutTime" BU_SG_REL_ CGW_CCU SG_ 1951 APSU_GST_Byte2 0;
BA_ "NetworkRequest" SG_ 1951 APSU_GST_Byte2 0;
BA_ "NetworkRequestHoldingTime" SG_ 1951 APSU_GST_Byte2 5000;
BA_ "Version" SG_ 1951 APSU_GST_Byte2 "21.02.04";
BA_ "Description" SG_ 1951 APSU_GST_Byte3 "TP Index : 109";
BA_ "UsrSigPurpose" SG_ 1951 APSU_GST_Byte3 4;
BA_ "UserSigValidity" SG_ 1951 APSU_GST_Byte3 0;
BA_REL_ "GenSigTimeoutTime" BU_SG_REL_ CGW_CCU SG_ 1951 APSU_GST_Byte3 0;
BA_ "NetworkRequest" SG_ 1951 APSU_GST_Byte3 0;
BA_ "NetworkRequestHoldingTime" SG_ 1951 APSU_GST_Byte3 5000;
BA_ "Version" SG_ 1951 APSU_GST_Byte3 "21.02.04";
BA_ "Description" SG_ 1951 APSU_GST_Byte4 "TP Index : 109";
BA_ "UsrSigPurpose" SG_ 1951 APSU_GST_Byte4 4;
BA_ "UserSigValidity" SG_ 1951 APSU_GST_Byte4 0;
BA_REL_ "GenSigTimeoutTime" BU_SG_REL_ CGW_CCU SG_ 1951 APSU_GST_Byte4 0;
BA_ "NetworkRequest" SG_ 1951 APSU_GST_Byte4 0;
BA_ "NetworkRequestHoldingTime" SG_ 1951 APSU_GST_Byte4 5000;
BA_ "Version" SG_ 1951 APSU_GST_Byte4 "21.02.04";
BA_ "Description" SG_ 1951 APSU_GST_Byte5 "TP Index : 109";
BA_ "UsrSigPurpose" SG_ 1951 APSU_GST_Byte5 4;
BA_ "UserSigValidity" SG_ 1951 APSU_GST_Byte5 0;
BA_REL_ "GenSigTimeoutTime" BU_SG_REL_ CGW_CCU SG_ 1951 APSU_GST_Byte5 0;
BA_ "NetworkRequest" SG_ 1951 APSU_GST_Byte5 0;
BA_ "NetworkRequestHoldingTime" SG_ 1951 APSU_GST_Byte5 5000;
BA_ "Version" SG_ 1951 APSU_GST_Byte5 "21.02.04";
BA_ "Description" SG_ 1951 APSU_GST_Byte6 "TP Index : 109";
BA_ "UsrSigPurpose" SG_ 1951 APSU_GST_Byte6 4;
BA_ "UserSigValidity" SG_ 1951 APSU_GST_Byte6 0;
BA_REL_ "GenSigTimeoutTime" BU_SG_REL_ CGW_CCU SG_ 1951 APSU_GST_Byte6 0;
BA_ "NetworkRequest" SG_ 1951 APSU_GST_Byte6 0;
BA_ "NetworkRequestHoldingTime" SG_ 1951 APSU_GST_Byte6 5000;
BA_ "Version" SG_ 1951 APSU_GST_Byte6 "21.02.04";
BA_ "Description" SG_ 1951 APSU_GST_Byte7 "TP Index : 109";
BA_ "UsrSigPurpose" SG_ 1951 APSU_GST_Byte7 4;
BA_ "UserSigValidity" SG_ 1951 APSU_GST_Byte7 0;
BA_REL_ "GenSigTimeoutTime" BU_SG_REL_ CGW_CCU SG_ 1951 APSU_GST_Byte7 0;
BA_ "NetworkRequest" SG_ 1951 APSU_GST_Byte7 0;
BA_ "NetworkRequestHoldingTime" SG_ 1951 APSU_GST_Byte7 5000;
BA_ "Version" SG_ 1951 APSU_GST_Byte7 "21.02.04";
BA_ "Description" SG_ 1951 APSU_GST_Byte1 "TP Index : 109";
BA_ "UsrSigPurpose" SG_ 1951 APSU_GST_Byte1 4;
BA_ "UserSigValidity" SG_ 1951 APSU_GST_Byte1 0;
BA_REL_ "GenSigTimeoutTime" BU_SG_REL_ CGW_CCU SG_ 1951 APSU_GST_Byte1 0;
BA_ "NetworkRequest" SG_ 1951 APSU_GST_Byte1 0;
BA_ "NetworkRequestHoldingTime" SG_ 1951 APSU_GST_Byte1 5000;
BA_ "Version" SG_ 1951 APSU_GST_Byte1 "21.02.04";
BA_ "GenMsgCycleTime" BO_ 1466 0;
BA_ "GenMsgCycleTimeFast" BO_ 1466 0;
BA_ "GenMsgNrOfRepetition" BO_ 1466 0;
BA_ "DiagResponse" BO_ 1466 1;
BA_ "GenMsgILSupport" BO_ 1466 0;
BA_ "TpMessage" BO_ 1466 1;
BA_ "TpTxIndex" BO_ 1466 212;
BA_ "Description" SG_ 1466 ATS_GST_Byte0 "TP Index : 212";
BA_ "UsrSigPurpose" SG_ 1466 ATS_GST_Byte0 4;
BA_ "UserSigValidity" SG_ 1466 ATS_GST_Byte0 0;
BA_REL_ "GenSigTimeoutTime" BU_SG_REL_ CGW_CCU SG_ 1466 ATS_GST_Byte0 0;
BA_ "NetworkRequest" SG_ 1466 ATS_GST_Byte0 0;
BA_ "NetworkRequestHoldingTime" SG_ 1466 ATS_GST_Byte0 5000;
BA_ "Version" SG_ 1466 ATS_GST_Byte0 "21.02.04";
BA_ "Description" SG_ 1466 ATS_GST_Byte2 "TP Index : 212";
BA_ "UsrSigPurpose" SG_ 1466 ATS_GST_Byte2 4;
BA_ "UserSigValidity" SG_ 1466 ATS_GST_Byte2 0;
BA_REL_ "GenSigTimeoutTime" BU_SG_REL_ CGW_CCU SG_ 1466 ATS_GST_Byte2 0;
BA_ "NetworkRequest" SG_ 1466 ATS_GST_Byte2 0;
BA_ "NetworkRequestHoldingTime" SG_ 1466 ATS_GST_Byte2 5000;
BA_ "Version" SG_ 1466 ATS_GST_Byte2 "21.02.04";
BA_ "Description" SG_ 1466 ATS_GST_Byte3 "TP Index : 212";
BA_ "UsrSigPurpose" SG_ 1466 ATS_GST_Byte3 4;
BA_ "UserSigValidity" SG_ 1466 ATS_GST_Byte3 0;
BA_REL_ "GenSigTimeoutTime" BU_SG_REL_ CGW_CCU SG_ 1466 ATS_GST_Byte3 0;
BA_ "NetworkRequest" SG_ 1466 ATS_GST_Byte3 0;
BA_ "NetworkRequestHoldingTime" SG_ 1466 ATS_GST_Byte3 5000;
BA_ "Version" SG_ 1466 ATS_GST_Byte3 "21.02.04";
BA_ "Description" SG_ 1466 ATS_GST_Byte4 "TP Index : 212";
BA_ "UsrSigPurpose" SG_ 1466 ATS_GST_Byte4 4;
BA_ "UserSigValidity" SG_ 1466 ATS_GST_Byte4 0;
BA_REL_ "GenSigTimeoutTime" BU_SG_REL_ CGW_CCU SG_ 1466 ATS_GST_Byte4 0;
BA_ "NetworkRequest" SG_ 1466 ATS_GST_Byte4 0;
BA_ "NetworkRequestHoldingTime" SG_ 1466 ATS_GST_Byte4 5000;
BA_ "Version" SG_ 1466 ATS_GST_Byte4 "21.02.04";
BA_ "Description" SG_ 1466 ATS_GST_Byte5 "TP Index : 212";
BA_ "UsrSigPurpose" SG_ 1466 ATS_GST_Byte5 4;
BA_ "UserSigValidity" SG_ 1466 ATS_GST_Byte5 0;
BA_REL_ "GenSigTimeoutTime" BU_SG_REL_ CGW_CCU SG_ 1466 ATS_GST_Byte5 0;
BA_ "NetworkRequest" SG_ 1466 ATS_GST_Byte5 0;
BA_ "NetworkRequestHoldingTime" SG_ 1466 ATS_GST_Byte5 5000;
BA_ "Version" SG_ 1466 ATS_GST_Byte5 "21.02.04";
BA_ "Description" SG_ 1466 ATS_GST_Byte6 "TP Index : 212";
BA_ "UsrSigPurpose" SG_ 1466 ATS_GST_Byte6 4;
BA_ "UserSigValidity" SG_ 1466 ATS_GST_Byte6 0;
BA_REL_ "GenSigTimeoutTime" BU_SG_REL_ CGW_CCU SG_ 1466 ATS_GST_Byte6 0;
BA_ "NetworkRequest" SG_ 1466 ATS_GST_Byte6 0;
BA_ "NetworkRequestHoldingTime" SG_ 1466 ATS_GST_Byte6 5000;
BA_ "Version" SG_ 1466 ATS_GST_Byte6 "21.02.04";
BA_ "Description" SG_ 1466 ATS_GST_Byte7 "TP Index : 212";
BA_ "UsrSigPurpose" SG_ 1466 ATS_GST_Byte7 4;
BA_ "UserSigValidity" SG_ 1466 ATS_GST_Byte7 0;
BA_REL_ "GenSigTimeoutTime" BU_SG_REL_ CGW_CCU SG_ 1466 ATS_GST_Byte7 0;
BA_ "NetworkRequest" SG_ 1466 ATS_GST_Byte7 0;
BA_ "NetworkRequestHoldingTime" SG_ 1466 ATS_GST_Byte7 5000;
BA_ "Version" SG_ 1466 ATS_GST_Byte7 "21.02.04";
BA_ "Description" SG_ 1466 ATS_GST_Byte1 "TP Index : 212";
BA_ "UsrSigPurpose" SG_ 1466 ATS_GST_Byte1 4;
BA_ "UserSigValidity" SG_ 1466 ATS_GST_Byte1 0;
BA_REL_ "GenSigTimeoutTime" BU_SG_REL_ CGW_CCU SG_ 1466 ATS_GST_Byte1 0;
BA_ "NetworkRequest" SG_ 1466 ATS_GST_Byte1 0;
BA_ "NetworkRequestHoldingTime" SG_ 1466 ATS_GST_Byte1 5000;
BA_ "Version" SG_ 1466 ATS_GST_Byte1 "21.02.04";
BA_ "GenMsgSendType" BO_ 997 0;
BA_ "Description" SG_ 997 BCM_Crc5Val "The data area for CRC calculation is based on the data length (DLC) of the message DB.

The CRC shall be calculated over the entire data block (excluding the CRC bytes) including the user data, alive counter and Data ID 

 

- CRC Polynomial (0x1D) , Initial Value : 0x00, XOR value : 0xFF, Data ID Mode : Both, Data ID : Message ID + 0xF800 

- The initial value is for CRC calculation and the message should be sent with the calculated result value. 

The mathematical expression to 8 bit CRC polynomial is given here. G(x) = x8 + x4 + x3 + x2 + 1";
BA_ "GenSigSendType" SG_ 997 BCM_Crc5Val 4;
BA_ "GenSigStartValue" SG_ 997 BCM_Crc5Val 255;
BA_ "UserSigValidity" SG_ 997 BCM_Crc5Val 0;
BA_ "Version" SG_ 997 BCM_Crc5Val "18.11.08";
BA_ "Description" SG_ 997 BCM_AlvCnt5Val "For the first transmission request for a data element the counter shall be initialized with 0 and shall be incremented by 1

for every subsequent send request. When the counter reaches the maximum value(0xE), then it shall restart with 0 for the next send request";
BA_ "GenSigSendType" SG_ 997 BCM_AlvCnt5Val 4;
BA_ "UserSigValidity" SG_ 997 BCM_AlvCnt5Val 0;
BA_ "Version" SG_ 997 BCM_AlvCnt5Val "18.11.08";
BA_ "Description" SG_ 997 PDW_OptTyp "this signal means PDW Option (Non, PDW-R, PDW-FR)

0x3: Reserved for the same Value Table as the ADAS_PRK Signal";
BA_ "GenSigSendType" SG_ 997 PDW_OptTyp 4;
BA_ "UserSigValidity" SG_ 997 PDW_OptTyp 3;
BA_ "NetworkRequest" SG_ 997 PDW_OptTyp 0;
BA_ "NetworkRequestHoldingTime" SG_ 997 PDW_OptTyp 5000;
BA_ "Version" SG_ 997 PDW_OptTyp "20.11.02";
BA_ "Description" SG_ 997 PDW_SysChkSndSta "-PDW System state check sound";
BA_ "GenSigSendType" SG_ 997 PDW_SysChkSndSta 4;
BA_ "UserSigValidity" SG_ 997 PDW_SysChkSndSta 0;
BA_ "NetworkRequest" SG_ 997 PDW_SysChkSndSta 0;
BA_ "NetworkRequestHoldingTime" SG_ 997 PDW_SysChkSndSta 5000;
BA_ "Version" SG_ 997 PDW_SysChkSndSta "17.12.00";
BA_ "Description" SG_ 997 PDW_SwIndOnReq "-PDW Switch Indicator On/Off Request

This signal is used for PDW-R and PDW-F/R";
BA_ "GenSigSendType" SG_ 997 PDW_SwIndOnReq 4;
BA_ "UserSigValidity" SG_ 997 PDW_SwIndOnReq 0;
BA_ "NetworkRequest" SG_ 997 PDW_SwIndOnReq 0;
BA_ "NetworkRequestHoldingTime" SG_ 997 PDW_SwIndOnReq 5000;
BA_ "Version" SG_ 997 PDW_SwIndOnReq "18.03.05";
BA_ "Description" SG_ 997 PDW_SysOnSta "-PDW System operating status";
BA_ "GenSigSendType" SG_ 997 PDW_SysOnSta 4;
BA_ "UserSigValidity" SG_ 997 PDW_SysOnSta 0;
BA_ "NetworkRequest" SG_ 997 PDW_SysOnSta 0;
BA_ "NetworkRequestHoldingTime" SG_ 997 PDW_SysOnSta 5000;
BA_ "Version" SG_ 997 PDW_SysOnSta "17.12.00";
BA_ "Description" SG_ 997 PDW_FrCtWrngLvlDis "-Front center display";
BA_ "GenSigSendType" SG_ 997 PDW_FrCtWrngLvlDis 4;
BA_ "UserSigValidity" SG_ 997 PDW_FrCtWrngLvlDis 0;
BA_ "NetworkRequest" SG_ 997 PDW_FrCtWrngLvlDis 0;
BA_ "NetworkRequestHoldingTime" SG_ 997 PDW_FrCtWrngLvlDis 5000;
BA_ "Version" SG_ 997 PDW_FrCtWrngLvlDis "20.04.02";
BA_ "Description" SG_ 997 PDW_SysFlrSta "Ultrasonic sensor status - Blockage/Failure pop-up request";
BA_ "GenSigSendType" SG_ 997 PDW_SysFlrSta 4;
BA_ "UserSigValidity" SG_ 997 PDW_SysFlrSta 3;
BA_ "Version" SG_ 997 PDW_SysFlrSta "20.11.02";
BA_ "Description" SG_ 997 PDW_FrCtWrngSndSta "-Pas Warning Sound for AMP Speaker output";
BA_ "GenSigSendType" SG_ 997 PDW_FrCtWrngSndSta 4;
BA_ "UserSigValidity" SG_ 997 PDW_FrCtWrngSndSta 0;
BA_REL_ "GenSigTimeoutTime" BU_SG_REL_ AMP SG_ 997 PDW_FrCtWrngSndSta 1500;
BA_ "NetworkRequest" SG_ 997 PDW_FrCtWrngSndSta 0;
BA_ "NetworkRequestHoldingTime" SG_ 997 PDW_FrCtWrngSndSta 5000;
BA_ "Version" SG_ 997 PDW_FrCtWrngSndSta "20.04.02";
BA_ "Description" SG_ 997 PDW_FrLtWrngLvlDis "-Front Left display";
BA_ "GenSigSendType" SG_ 997 PDW_FrLtWrngLvlDis 4;
BA_ "UserSigValidity" SG_ 997 PDW_FrLtWrngLvlDis 0;
BA_ "NetworkRequest" SG_ 997 PDW_FrLtWrngLvlDis 0;
BA_ "NetworkRequestHoldingTime" SG_ 997 PDW_FrLtWrngLvlDis 5000;
BA_ "Version" SG_ 997 PDW_FrLtWrngLvlDis "20.04.02";
BA_ "Description" SG_ 997 PDW_FrLtWrngSndSta "-Pas Warning Sound for AMP Speaker output";
BA_ "GenSigSendType" SG_ 997 PDW_FrLtWrngSndSta 4;
BA_ "UserSigValidity" SG_ 997 PDW_FrLtWrngSndSta 0;
BA_REL_ "GenSigTimeoutTime" BU_SG_REL_ AMP SG_ 997 PDW_FrLtWrngSndSta 1500;
BA_ "NetworkRequest" SG_ 997 PDW_FrLtWrngSndSta 0;
BA_ "NetworkRequestHoldingTime" SG_ 997 PDW_FrLtWrngSndSta 5000;
BA_ "Version" SG_ 997 PDW_FrLtWrngSndSta "20.04.02";
BA_ "Description" SG_ 997 PDW_FrRtWrngLvlDis "-Front Right display";
BA_ "GenSigSendType" SG_ 997 PDW_FrRtWrngLvlDis 4;
BA_ "UserSigValidity" SG_ 997 PDW_FrRtWrngLvlDis 0;
BA_ "NetworkRequest" SG_ 997 PDW_FrRtWrngLvlDis 0;
BA_ "NetworkRequestHoldingTime" SG_ 997 PDW_FrRtWrngLvlDis 5000;
BA_ "Version" SG_ 997 PDW_FrRtWrngLvlDis "17.12.00";
BA_ "Description" SG_ 997 PDW_FrRtWrngSndSta "-Pas Warning Sound for AMP Speaker output";
BA_ "GenSigSendType" SG_ 997 PDW_FrRtWrngSndSta 4;
BA_ "UserSigValidity" SG_ 997 PDW_FrRtWrngSndSta 0;
BA_REL_ "GenSigTimeoutTime" BU_SG_REL_ AMP SG_ 997 PDW_FrRtWrngSndSta 1500;
BA_ "NetworkRequest" SG_ 997 PDW_FrRtWrngSndSta 0;
BA_ "NetworkRequestHoldingTime" SG_ 997 PDW_FrRtWrngSndSta 5000;
BA_ "Version" SG_ 997 PDW_FrRtWrngSndSta "17.12.00";
BA_ "Description" SG_ 997 PDW_FrSnsrWrngLvlSta "-Front Sensor warning";
BA_ "GenSigSendType" SG_ 997 PDW_FrSnsrWrngLvlSta 4;
BA_ "UserSigValidity" SG_ 997 PDW_FrSnsrWrngLvlSta 0;
BA_ "NetworkRequest" SG_ 997 PDW_FrSnsrWrngLvlSta 0;
BA_ "NetworkRequestHoldingTime" SG_ 997 PDW_FrSnsrWrngLvlSta 5000;
BA_ "Version" SG_ 997 PDW_FrSnsrWrngLvlSta "17.12.00";
BA_ "GenMsgSendType" BO_ 998 0;
BA_ "Description" SG_ 998 BCM_Crc6Val "The data area for CRC calculation is based on the data length (DLC) of the message DB.

The CRC shall be calculated over the entire data block (excluding the CRC bytes) including the user data, alive counter and Data ID 

 

- CRC Polynomial (0x1D) , Initial Value : 0x00, XOR value : 0xFF, Data ID Mode : Both, Data ID : Message ID + 0xF800 

- The initial value is for CRC calculation and the message should be sent with the calculated result value. 

The mathematical expression to 8 bit CRC polynomial is given here. G(x) = x8 + x4 + x3 + x2 + 1";
BA_ "GenSigSendType" SG_ 998 BCM_Crc6Val 4;
BA_ "GenSigStartValue" SG_ 998 BCM_Crc6Val 255;
BA_ "UserSigValidity" SG_ 998 BCM_Crc6Val 0;
BA_ "Version" SG_ 998 BCM_Crc6Val "18.11.08";
BA_ "Description" SG_ 998 BCM_AlvCnt6Val "For the first transmission request for a data element the counter shall be initialized with 0 and shall be incremented by 1

for every subsequent send request. When the counter reaches the maximum value(0xE), then it shall restart with 0 for the next send request";
BA_ "GenSigSendType" SG_ 998 BCM_AlvCnt6Val 4;
BA_ "UserSigValidity" SG_ 998 BCM_AlvCnt6Val 0;
BA_ "Version" SG_ 998 BCM_AlvCnt6Val "18.11.08";
BA_ "Description" SG_ 998 PDW_RrCtWrngLvlDis "-Rear center display";
BA_ "GenSigSendType" SG_ 998 PDW_RrCtWrngLvlDis 4;
BA_ "UserSigValidity" SG_ 998 PDW_RrCtWrngLvlDis 0;
BA_ "NetworkRequest" SG_ 998 PDW_RrCtWrngLvlDis 0;
BA_ "NetworkRequestHoldingTime" SG_ 998 PDW_RrCtWrngLvlDis 5000;
BA_ "Version" SG_ 998 PDW_RrCtWrngLvlDis "20.04.02";
BA_ "Description" SG_ 998 PDW_RrCtWrngSndSta "-Pas Warning Sound for AMP Speaker output";
BA_ "GenSigSendType" SG_ 998 PDW_RrCtWrngSndSta 4;
BA_ "UserSigValidity" SG_ 998 PDW_RrCtWrngSndSta 0;
BA_REL_ "GenSigTimeoutTime" BU_SG_REL_ AMP SG_ 998 PDW_RrCtWrngSndSta 1500;
BA_ "NetworkRequest" SG_ 998 PDW_RrCtWrngSndSta 0;
BA_ "NetworkRequestHoldingTime" SG_ 998 PDW_RrCtWrngSndSta 5000;
BA_ "Version" SG_ 998 PDW_RrCtWrngSndSta "20.04.02";
BA_ "Description" SG_ 998 PDW_RrLtWrngLvlDis "-Rear Left display";
BA_ "GenSigSendType" SG_ 998 PDW_RrLtWrngLvlDis 4;
BA_ "UserSigValidity" SG_ 998 PDW_RrLtWrngLvlDis 0;
BA_ "NetworkRequest" SG_ 998 PDW_RrLtWrngLvlDis 0;
BA_ "NetworkRequestHoldingTime" SG_ 998 PDW_RrLtWrngLvlDis 5000;
BA_ "Version" SG_ 998 PDW_RrLtWrngLvlDis "20.04.02";
BA_ "Description" SG_ 998 PDW_RrLtWrngSndSta "-Pas Warning Sound for AMP Speaker output";
BA_ "GenSigSendType" SG_ 998 PDW_RrLtWrngSndSta 4;
BA_ "UserSigValidity" SG_ 998 PDW_RrLtWrngSndSta 0;
BA_REL_ "GenSigTimeoutTime" BU_SG_REL_ AMP SG_ 998 PDW_RrLtWrngSndSta 1500;
BA_ "NetworkRequest" SG_ 998 PDW_RrLtWrngSndSta 0;
BA_ "NetworkRequestHoldingTime" SG_ 998 PDW_RrLtWrngSndSta 5000;
BA_ "Version" SG_ 998 PDW_RrLtWrngSndSta "20.04.02";
BA_ "Description" SG_ 998 PDW_RrRtWrngLvlDis "-Rear Right display";
BA_ "GenSigSendType" SG_ 998 PDW_RrRtWrngLvlDis 4;
BA_ "UserSigValidity" SG_ 998 PDW_RrRtWrngLvlDis 0;
BA_ "NetworkRequest" SG_ 998 PDW_RrRtWrngLvlDis 0;
BA_ "NetworkRequestHoldingTime" SG_ 998 PDW_RrRtWrngLvlDis 5000;
BA_ "Version" SG_ 998 PDW_RrRtWrngLvlDis "17.12.00";
BA_ "Description" SG_ 998 PDW_RrRtWrngSndSta "-Pas Warning Sound for AMP Speaker output";
BA_ "GenSigSendType" SG_ 998 PDW_RrRtWrngSndSta 4;
BA_ "UserSigValidity" SG_ 998 PDW_RrRtWrngSndSta 0;
BA_REL_ "GenSigTimeoutTime" BU_SG_REL_ AMP SG_ 998 PDW_RrRtWrngSndSta 1500;
BA_ "NetworkRequest" SG_ 998 PDW_RrRtWrngSndSta 0;
BA_ "NetworkRequestHoldingTime" SG_ 998 PDW_RrRtWrngSndSta 5000;
BA_ "Version" SG_ 998 PDW_RrRtWrngSndSta "17.12.00";
BA_ "Description" SG_ 998 PDW_RrSnsrWrngLvlSta "-Rear Sensor warning";
BA_ "GenSigSendType" SG_ 998 PDW_RrSnsrWrngLvlSta 4;
BA_ "UserSigValidity" SG_ 998 PDW_RrSnsrWrngLvlSta 0;
BA_ "NetworkRequest" SG_ 998 PDW_RrSnsrWrngLvlSta 0;
BA_ "NetworkRequestHoldingTime" SG_ 998 PDW_RrSnsrWrngLvlSta 5000;
BA_ "Version" SG_ 998 PDW_RrSnsrWrngLvlSta "17.12.00";
BA_ "GenMsgSendType" BO_ 963 0;
BA_ "Description" SG_ 963 BCM_Crc16Val "The data area for CRC calculation is based on the data length (DLC) of the message DB.

The CRC shall be calculated over the entire data block (excluding the CRC bytes) including the user data, alive counter and Data ID 

 

- CRC Polynomial (0x1D) , Initial Value : 0x00, XOR value : 0xFF, Data ID Mode : Both, Data ID : Message ID + 0xF800 

- The initial value is for CRC calculation and the message should be sent with the calculated result value. 

The mathematical expression to 8 bit CRC polynomial is given here. G(x) = x8 + x4 + x3 + x2 + 1";
BA_ "GenSigSendType" SG_ 963 BCM_Crc16Val 4;
BA_ "GenSigStartValue" SG_ 963 BCM_Crc16Val 255;
BA_ "UserSigValidity" SG_ 963 BCM_Crc16Val 0;
BA_ "Version" SG_ 963 BCM_Crc16Val "18.11.08";
BA_ "Description" SG_ 963 BCM_AlvCnt16Val "For the first transmission request for a data element the counter shall be initialized with 0 and shall be incremented by 1

for every subsequent send request. When the counter reaches the maximum value(0xE), then it shall restart with 0 for the next send request";
BA_ "GenSigSendType" SG_ 963 BCM_AlvCnt16Val 4;
BA_ "UserSigValidity" SG_ 963 BCM_AlvCnt16Val 0;
BA_ "Version" SG_ 963 BCM_AlvCnt16Val "18.11.08";
BA_ "Description" SG_ 963 IBU_SWVerMajor1 "Indicate the IBU software version as follows:

- The software version is displayed in three digits.

- The Major and Minor digits are separated by '.'

- Signal values are transmitted to ASCII codes.



※ Example

C_IBU_SWVerMajor1 : 0x41 (HEX) -> ASCII CODE : 'A' 

C_IBU_SWVerMinor1 : 0x30 (HEX) -> ASCII CODE : '0'

C_IBU_SWVerMinor2 : 0x33 (HEX) -> ASCII CODE : '3'

=> IBU S/W Ver is displayed 'A.03'";
BA_ "GenSigSendType" SG_ 963 IBU_SWVerMajor1 4;
BA_ "UserSigValidity" SG_ 963 IBU_SWVerMajor1 0;
BA_ "Version" SG_ 963 IBU_SWVerMajor1 "20.12.04";
BA_ "Description" SG_ 963 IBU_SWVerMinor1 "Indicate the IBU software version as follows:

- The software version is displayed in three digits.

- The Major and Minor digits are separated by '.'

- Signal values are transmitted to ASCII codes.



※ Example

C_IBU_SWVerMajor1 : 0x41 (HEX) -> ASCII CODE : 'A' 

C_IBU_SWVerMinor1 : 0x30 (HEX) -> ASCII CODE : '0'

C_IBU_SWVerMinor2 : 0x33 (HEX) -> ASCII CODE : '3'

=> IBU S/W Ver is displayed 'A.03'";
BA_ "GenSigSendType" SG_ 963 IBU_SWVerMinor1 4;
BA_ "UserSigValidity" SG_ 963 IBU_SWVerMinor1 0;
BA_ "Version" SG_ 963 IBU_SWVerMinor1 "18.10.02";
BA_ "Description" SG_ 963 IBU_SWVerMinor2 "Indicate the IBU software version as follows:

- The software version is displayed in three digits.

- The Major and Minor digits are separated by '.'

- Signal values are transmitted to ASCII codes.



※ Example

C_IBU_SWVerMajor1 : 0x41 (HEX) -> ASCII CODE : 'A' 

C_IBU_SWVerMinor1 : 0x30 (HEX) -> ASCII CODE : '0'

C_IBU_SWVerMinor2 : 0x33 (HEX) -> ASCII CODE : '3'

=> IBU S/W Ver is displayed 'A.03'";
BA_ "GenSigSendType" SG_ 963 IBU_SWVerMinor2 4;
BA_ "UserSigValidity" SG_ 963 IBU_SWVerMinor2 0;
BA_ "Version" SG_ 963 IBU_SWVerMinor2 "18.10.02";
BA_ "Description" SG_ 963 ECW_Fault "ECW LIN to CAN Signal 

- LIN Signal Name : FAULT_ECW";
BA_ "GenSigSendType" SG_ 963 ECW_Fault 4;
BA_ "UserSigValidity" SG_ 963 ECW_Fault 0;
BA_ "NetworkRequest" SG_ 963 ECW_Fault 0;
BA_ "NetworkRequestHoldingTime" SG_ 963 ECW_Fault 5000;
BA_ "Version" SG_ 963 ECW_Fault "20.05.02";
BA_ "Description" SG_ 963 ECW_FaultActv "ECW LIN to CAN Signal

- LIN Signal Name : FAULT_ACTIVE";
BA_ "GenSigSendType" SG_ 963 ECW_FaultActv 4;
BA_ "GenSigStartValue" SG_ 963 ECW_FaultActv 1;
BA_ "UserSigValidity" SG_ 963 ECW_FaultActv 0;
BA_ "NetworkRequest" SG_ 963 ECW_FaultActv 0;
BA_ "NetworkRequestHoldingTime" SG_ 963 ECW_FaultActv 5000;
BA_ "Version" SG_ 963 ECW_FaultActv "20.05.02";
BA_ "Description" SG_ 963 ECW_HiVolt "ECW LIN to CAN Signal

- LIN Signal Name : HIGH_VOLT_ECW";
BA_ "GenSigSendType" SG_ 963 ECW_HiVolt 4;
BA_ "UserSigValidity" SG_ 963 ECW_HiVolt 0;
BA_ "NetworkRequest" SG_ 963 ECW_HiVolt 0;
BA_ "NetworkRequestHoldingTime" SG_ 963 ECW_HiVolt 5000;
BA_ "Version" SG_ 963 ECW_HiVolt "20.05.02";
BA_ "Description" SG_ 963 ECW_HiVoltActv "ECW LIN to CAN Signal

- LIN Signal Name : HIGH_VOLT_ACTIVE";
BA_ "GenSigSendType" SG_ 963 ECW_HiVoltActv 4;
BA_ "GenSigStartValue" SG_ 963 ECW_HiVoltActv 1;
BA_ "UserSigValidity" SG_ 963 ECW_HiVoltActv 0;
BA_ "NetworkRequest" SG_ 963 ECW_HiVoltActv 0;
BA_ "NetworkRequestHoldingTime" SG_ 963 ECW_HiVoltActv 5000;
BA_ "Version" SG_ 963 ECW_HiVoltActv "20.05.02";
BA_ "Description" SG_ 963 ECW_LoVolt "ECW LIN to CAN Signal

- LIN Signal Name : LOW_VOLT_ECW";
BA_ "GenSigSendType" SG_ 963 ECW_LoVolt 4;
BA_ "UserSigValidity" SG_ 963 ECW_LoVolt 0;
BA_ "NetworkRequest" SG_ 963 ECW_LoVolt 0;
BA_ "NetworkRequestHoldingTime" SG_ 963 ECW_LoVolt 5000;
BA_ "Version" SG_ 963 ECW_LoVolt "20.05.02";
BA_ "Description" SG_ 963 ECW_LoVoltActv "ECW LIN to CAN Signal

- LIN Signal Name : LOW_VOLT_ACTIVE";
BA_ "GenSigSendType" SG_ 963 ECW_LoVoltActv 4;
BA_ "GenSigStartValue" SG_ 963 ECW_LoVoltActv 1;
BA_ "UserSigValidity" SG_ 963 ECW_LoVoltActv 0;
BA_ "NetworkRequest" SG_ 963 ECW_LoVoltActv 0;
BA_ "NetworkRequestHoldingTime" SG_ 963 ECW_LoVoltActv 5000;
BA_ "Version" SG_ 963 ECW_LoVoltActv "20.05.02";
BA_ "Description" SG_ 963 ECW_Overload "ECW LIN to CAN Signal

- LIN Signal Name : OVERLOAD_ECW";
BA_ "GenSigSendType" SG_ 963 ECW_Overload 4;
BA_ "UserSigValidity" SG_ 963 ECW_Overload 0;
BA_ "NetworkRequest" SG_ 963 ECW_Overload 0;
BA_ "NetworkRequestHoldingTime" SG_ 963 ECW_Overload 5000;
BA_ "Version" SG_ 963 ECW_Overload "20.05.02";
BA_ "Description" SG_ 963 ECW_OverloadActv "ECW LIN to CAN Signal

- LIN Signal Name : OVERLOAD_ACTIVE";
BA_ "GenSigSendType" SG_ 963 ECW_OverloadActv 4;
BA_ "GenSigStartValue" SG_ 963 ECW_OverloadActv 1;
BA_ "UserSigValidity" SG_ 963 ECW_OverloadActv 0;
BA_ "NetworkRequest" SG_ 963 ECW_OverloadActv 0;
BA_ "NetworkRequestHoldingTime" SG_ 963 ECW_OverloadActv 5000;
BA_ "Version" SG_ 963 ECW_OverloadActv "20.05.02";
BA_ "Description" SG_ 963 ECW_CommErr "ECW LIN to CAN Signal

- LIN Signal Name : ERR_COMM_ECW";
BA_ "GenSigSendType" SG_ 963 ECW_CommErr 4;
BA_ "UserSigValidity" SG_ 963 ECW_CommErr 0;
BA_ "NetworkRequest" SG_ 963 ECW_CommErr 0;
BA_ "NetworkRequestHoldingTime" SG_ 963 ECW_CommErr 5000;
BA_ "Version" SG_ 963 ECW_CommErr "20.05.02";
BA_ "Description" SG_ 963 SunRoof_RearBlindOprSta "Rear BlindPanel information (LIN to CAN signal)

- LIN Singal name : SunRoof_RearBlindOprSta";
BA_ "GenSigSendType" SG_ 963 SunRoof_RearBlindOprSta 4;
BA_ "GenSigStartValue" SG_ 963 SunRoof_RearBlindOprSta 15;
BA_ "UserSigValidity" SG_ 963 SunRoof_RearBlindOprSta 0;
BA_REL_ "GenSigTimeoutTime" BU_SG_REL_ ATS SG_ 963 SunRoof_RearBlindOprSta 1500;
BA_ "Version" SG_ 963 SunRoof_RearBlindOprSta "20.07.00";
BA_ "GenMsgSendType" BO_ 2445570561 0;
BA_ "VFrameFormat" BO_ 2445570561 1;
BA_ "Description" SG_ 2445570561 USM_CluAdasVolSta "Cluster AdasVolumeStatus.";
BA_ "GenSigSendType" SG_ 2445570561 USM_CluAdasVolSta 4;
BA_ "UserSigValidity" SG_ 2445570561 USM_CluAdasVolSta 3;
BA_REL_ "GenSigTimeoutTime" BU_SG_REL_ AMP SG_ 2445570561 USM_CluAdasVolSta 1500;
BA_ "Version" SG_ 2445570561 USM_CluAdasVolSta "17.12.03";
BA_ "Description" SG_ 2445570561 Wrn_Snd_AdasVolFdbck "Signal for Amp AdasVolume feedback Sound";
BA_ "GenSigSendType" SG_ 2445570561 Wrn_Snd_AdasVolFdbck 4;
BA_ "UserSigValidity" SG_ 2445570561 Wrn_Snd_AdasVolFdbck 3;
BA_REL_ "GenSigTimeoutTime" BU_SG_REL_ AMP SG_ 2445570561 Wrn_Snd_AdasVolFdbck 1500;
BA_ "Version" SG_ 2445570561 Wrn_Snd_AdasVolFdbck "18.08.10";
BA_ "Description" SG_ 2445570561 CLU_AdasWarnSndStat "This signal indicates whether ADAS warning sound is output via the cluster speaker.

This signal is used for control the media volume.";
BA_ "GenSigSendType" SG_ 2445570561 CLU_AdasWarnSndStat 4;
BA_ "UserSigValidity" SG_ 2445570561 CLU_AdasWarnSndStat 3;
BA_REL_ "GenSigTimeoutTime" BU_SG_REL_ AMP SG_ 2445570561 CLU_AdasWarnSndStat 1500;
BA_ "Version" SG_ 2445570561 CLU_AdasWarnSndStat "19.06.02";
BA_ "GenMsgCycleTime" BO_ 2441372929 0;
BA_ "VFrameFormat" BO_ 2441372929 1;
BA_ "Description" SG_ 2441372929 DATC_Crc14Val "The data area for CRC calculation is based on the data length (DLC) of the message DB.

The CRC shall be calculated over the entire data block (excluding the CRC bytes) including the user data, alive counter and Data ID

 

- CRC Polynomial (0x1021) , Initial Value : 0xFFFF, XOR value : 0x0000, Data ID : Message ID + 0xF800 

- The initial value is for CRC calculation and the message should be sent with the calculated result value. 

- The mathematical expression to 16 bit CRC polynomial is given here. G(x) = x16 + x12 + x5 + 1";
BA_ "GenSigSendType" SG_ 2441372929 DATC_Crc14Val 4;
BA_ "GenSigStartValue" SG_ 2441372929 DATC_Crc14Val 65535;
BA_ "UserSigValidity" SG_ 2441372929 DATC_Crc14Val 3;
BA_ "Version" SG_ 2441372929 DATC_Crc14Val "18.11.08";
BA_ "Description" SG_ 2441372929 DATC_AlvCnt14Val "For the first transmission request for a data element the counter shall be initialized with 0 and shall be incremented by 1 for every subsequent send request. 

When the counter reaches the maximum value(0xFF), then it shall restart with 0 for the next send request";
BA_ "GenSigSendType" SG_ 2441372929 DATC_AlvCnt14Val 4;
BA_ "UserSigValidity" SG_ 2441372929 DATC_AlvCnt14Val 3;
BA_ "Version" SG_ 2441372929 DATC_AlvCnt14Val "18.11.08";
BA_ "Description" SG_ 2441372929 DATC_Beep1Sound "Play touch beep sound one time

Beep sound on/off

Default : Off

Goes On when play beep sound";
BA_ "GenSigSendType" SG_ 2441372929 DATC_Beep1Sound 4;
BA_ "GenSigStartValue" SG_ 2441372929 DATC_Beep1Sound 3;
BA_ "UserSigValidity" SG_ 2441372929 DATC_Beep1Sound 7;
BA_REL_ "GenSigTimeoutTime" BU_SG_REL_ AMP SG_ 2441372929 DATC_Beep1Sound 0;
BA_ "Version" SG_ 2441372929 DATC_Beep1Sound "18.12.01";
BA_ "GenMsgSendType" BO_ 2328014849 0;
BA_ "GenMsgCycleTimeFast" BO_ 2328014849 0;
BA_ "GenMsgNrOfRepetition" BO_ 2328014849 0;
BA_ "VFrameFormat" BO_ 2328014849 1;
BA_ "Description" SG_ 2328014849 DATC_Crc17Val "The data area for CRC calculation is based on the data length (DLC) of the message DB.

The CRC shall be calculated over the entire data block (excluding the CRC bytes) including the user data, alive counter and Data ID

 

- CRC Polynomial (0x1021) , Initial Value : 0xFFFF, XOR value : 0x0000, Data ID : Message ID + 0xF800 

- The initial value is for CRC calculation and the message should be sent with the calculated result value. 

- The mathematical expression to 16 bit CRC polynomial is given here. G(x) = x16 + x12 + x5 + 1";
BA_ "GenSigStartValue" SG_ 2328014849 DATC_Crc17Val 65535;
BA_ "UserSigValidity" SG_ 2328014849 DATC_Crc17Val 3;
BA_ "Version" SG_ 2328014849 DATC_Crc17Val "19.08.05";
BA_ "Description" SG_ 2328014849 DATC_AlvCnt17Val "For the first transmission request for a data element the counter shall be initialized with 0 and shall be incremented by 1 for every subsequent send request. 

When the counter reaches the maximum value(0xFF), then it shall restart with 0 for the next send request";
BA_ "UserSigValidity" SG_ 2328014849 DATC_AlvCnt17Val 3;
BA_ "Version" SG_ 2328014849 DATC_AlvCnt17Val "19.08.05";
BA_ "UserSigValidity" SG_ 2328014849 DATC_FrontPwmIsVolt 7;
BA_ "Version" SG_ 2328014849 DATC_FrontPwmIsVolt "19.08.05";
BA_ "UserSigValidity" SG_ 2328014849 DATC_FrontBlwDuty 7;
BA_ "Version" SG_ 2328014849 DATC_FrontBlwDuty "19.08.05";
BA_ "UserSigValidity" SG_ 2328014849 DATC_FrontBlwDiagStat 7;
BA_ "Version" SG_ 2328014849 DATC_FrontBlwDiagStat "19.08.05";
BA_ "Description" SG_ 2328014849 DATC_BlwrLvl_Ps "This signal indicates step of Front Passenger side blower operation .";
BA_ "UserSigValidity" SG_ 2328014849 DATC_BlwrLvl_Ps 7;
BA_ "Version" SG_ 2328014849 DATC_BlwrLvl_Ps "20.02.04";
BA_ "Description" SG_ 2328014849 DATC_BlwrLvl_Rr "This signal indicates step of Rear blower operation .";
BA_ "UserSigValidity" SG_ 2328014849 DATC_BlwrLvl_Rr 7;
BA_ "Version" SG_ 2328014849 DATC_BlwrLvl_Rr "20.02.03";
BA_ "Description" SG_ 2328014849 DATC_FnDstSnsrVal "This signal indicate fine dust sensor value.

It is valid from 0 to 500.";
BA_ "UserSigValidity" SG_ 2328014849 DATC_FnDstSnsrVal 7;
BA_REL_ "GenSigTimeoutTime" BU_SG_REL_ ATS SG_ 2328014849 DATC_FnDstSnsrVal 1500;
BA_ "Version" SG_ 2328014849 DATC_FnDstSnsrVal "20.09.00";
BA_ "GenMsgSendType" BO_ 2328014850 0;
BA_ "GenMsgCycleTimeFast" BO_ 2328014850 0;
BA_ "GenMsgNrOfRepetition" BO_ 2328014850 0;
BA_ "VFrameFormat" BO_ 2328014850 1;
BA_ "Description" SG_ 2328014850 DATC_FnDstStp "This signal indicate Fine Dust Step for CCS";
BA_ "UserSigValidity" SG_ 2328014850 DATC_FnDstStp 7;
BA_REL_ "GenSigTimeoutTime" BU_SG_REL_ ATS SG_ 2328014850 DATC_FnDstStp 1500;
BA_ "Version" SG_ 2328014850 DATC_FnDstStp "20.07.10";
BA_ "Description" SG_ 2328014850 DATC_HDPDfg_Sta "This signal indicate AutoDefog status information for HDP.";
BA_ "TimeoutValue" SG_ 2328014850 DATC_HDPDfg_Sta "0x1";
BA_ "UserSigValidity" SG_ 2328014850 DATC_HDPDfg_Sta 3;
BA_ "Version" SG_ 2328014850 DATC_HDPDfg_Sta "21.08.02";
BA_ "Description" SG_ 2328014850 DATC_HDPHumidity_Sta "This signal indicate Humidity status information for HDP.";
BA_ "UserSigValidity" SG_ 2328014850 DATC_HDPHumidity_Sta 3;
BA_ "Version" SG_ 2328014850 DATC_HDPHumidity_Sta "21.08.02";
BA_ "Description" SG_ 2328014850 DATC_FnDstStp_Detail "This signal indicate Detail State of Fine Dust Step for ATS.";
BA_ "UserSigValidity" SG_ 2328014850 DATC_FnDstStp_Detail 7;
BA_REL_ "GenSigTimeoutTime" BU_SG_REL_ ATS SG_ 2328014850 DATC_FnDstStp_Detail 1500;
BA_ "Version" SG_ 2328014850 DATC_FnDstStp_Detail "20.09.00";
BA_ "GenMsgSendType" BO_ 2328014851 0;
BA_ "GenMsgCycleTimeFast" BO_ 2328014851 0;
BA_ "GenMsgNrOfRepetition" BO_ 2328014851 0;
BA_ "VFrameFormat" BO_ 2328014851 1;
BA_ "GenMsgSendType" BO_ 2328014852 0;
BA_ "GenMsgCycleTimeFast" BO_ 2328014852 0;
BA_ "GenMsgNrOfRepetition" BO_ 2328014852 0;
BA_ "VFrameFormat" BO_ 2328014852 1;
BA_ "GenMsgCycleTime" BO_ 1962 0;
BA_ "GenMsgCycleTimeFast" BO_ 1962 0;
BA_ "GenMsgNrOfRepetition" BO_ 1962 0;
BA_ "DiagResponse" BO_ 1962 1;
BA_ "GenMsgILSupport" BO_ 1962 0;
BA_ "TpMessage" BO_ 1962 1;
BA_ "TpTxIndex" BO_ 1962 100;
BA_ "Description" SG_ 1962 FPM1_GST_Byte0 "TP Index : 100";
BA_ "UsrSigPurpose" SG_ 1962 FPM1_GST_Byte0 4;
BA_ "UserSigValidity" SG_ 1962 FPM1_GST_Byte0 0;
BA_REL_ "GenSigTimeoutTime" BU_SG_REL_ CGW_CCU SG_ 1962 FPM1_GST_Byte0 0;
BA_ "NetworkRequest" SG_ 1962 FPM1_GST_Byte0 0;
BA_ "NetworkRequestHoldingTime" SG_ 1962 FPM1_GST_Byte0 5000;
BA_ "Version" SG_ 1962 FPM1_GST_Byte0 "21.02.04";
BA_ "Description" SG_ 1962 FPM1_GST_Byte2 "TP Index : 100";
BA_ "UsrSigPurpose" SG_ 1962 FPM1_GST_Byte2 4;
BA_ "UserSigValidity" SG_ 1962 FPM1_GST_Byte2 0;
BA_REL_ "GenSigTimeoutTime" BU_SG_REL_ CGW_CCU SG_ 1962 FPM1_GST_Byte2 0;
BA_ "NetworkRequest" SG_ 1962 FPM1_GST_Byte2 0;
BA_ "NetworkRequestHoldingTime" SG_ 1962 FPM1_GST_Byte2 5000;
BA_ "Version" SG_ 1962 FPM1_GST_Byte2 "21.02.04";
BA_ "Description" SG_ 1962 FPM1_GST_Byte3 "TP Index : 100";
BA_ "UsrSigPurpose" SG_ 1962 FPM1_GST_Byte3 4;
BA_ "UserSigValidity" SG_ 1962 FPM1_GST_Byte3 0;
BA_REL_ "GenSigTimeoutTime" BU_SG_REL_ CGW_CCU SG_ 1962 FPM1_GST_Byte3 0;
BA_ "NetworkRequest" SG_ 1962 FPM1_GST_Byte3 0;
BA_ "NetworkRequestHoldingTime" SG_ 1962 FPM1_GST_Byte3 5000;
BA_ "Version" SG_ 1962 FPM1_GST_Byte3 "21.02.04";
BA_ "Description" SG_ 1962 FPM1_GST_Byte4 "TP Index : 100";
BA_ "UsrSigPurpose" SG_ 1962 FPM1_GST_Byte4 4;
BA_ "UserSigValidity" SG_ 1962 FPM1_GST_Byte4 0;
BA_REL_ "GenSigTimeoutTime" BU_SG_REL_ CGW_CCU SG_ 1962 FPM1_GST_Byte4 0;
BA_ "NetworkRequest" SG_ 1962 FPM1_GST_Byte4 0;
BA_ "NetworkRequestHoldingTime" SG_ 1962 FPM1_GST_Byte4 5000;
BA_ "Version" SG_ 1962 FPM1_GST_Byte4 "21.02.04";
BA_ "Description" SG_ 1962 FPM1_GST_Byte5 "TP Index : 100";
BA_ "UsrSigPurpose" SG_ 1962 FPM1_GST_Byte5 4;
BA_ "UserSigValidity" SG_ 1962 FPM1_GST_Byte5 0;
BA_REL_ "GenSigTimeoutTime" BU_SG_REL_ CGW_CCU SG_ 1962 FPM1_GST_Byte5 0;
BA_ "NetworkRequest" SG_ 1962 FPM1_GST_Byte5 0;
BA_ "NetworkRequestHoldingTime" SG_ 1962 FPM1_GST_Byte5 5000;
BA_ "Version" SG_ 1962 FPM1_GST_Byte5 "21.02.04";
BA_ "Description" SG_ 1962 FPM1_GST_Byte6 "TP Index : 100";
BA_ "UsrSigPurpose" SG_ 1962 FPM1_GST_Byte6 4;
BA_ "UserSigValidity" SG_ 1962 FPM1_GST_Byte6 0;
BA_REL_ "GenSigTimeoutTime" BU_SG_REL_ CGW_CCU SG_ 1962 FPM1_GST_Byte6 0;
BA_ "NetworkRequest" SG_ 1962 FPM1_GST_Byte6 0;
BA_ "NetworkRequestHoldingTime" SG_ 1962 FPM1_GST_Byte6 5000;
BA_ "Version" SG_ 1962 FPM1_GST_Byte6 "21.02.04";
BA_ "Description" SG_ 1962 FPM1_GST_Byte7 "TP Index : 100";
BA_ "UsrSigPurpose" SG_ 1962 FPM1_GST_Byte7 4;
BA_ "UserSigValidity" SG_ 1962 FPM1_GST_Byte7 0;
BA_REL_ "GenSigTimeoutTime" BU_SG_REL_ CGW_CCU SG_ 1962 FPM1_GST_Byte7 0;
BA_ "NetworkRequest" SG_ 1962 FPM1_GST_Byte7 0;
BA_ "NetworkRequestHoldingTime" SG_ 1962 FPM1_GST_Byte7 5000;
BA_ "Version" SG_ 1962 FPM1_GST_Byte7 "21.02.04";
BA_ "Description" SG_ 1962 FPM1_GST_Byte1 "TP Index : 100";
BA_ "UsrSigPurpose" SG_ 1962 FPM1_GST_Byte1 4;
BA_ "UserSigValidity" SG_ 1962 FPM1_GST_Byte1 0;
BA_REL_ "GenSigTimeoutTime" BU_SG_REL_ CGW_CCU SG_ 1962 FPM1_GST_Byte1 0;
BA_ "NetworkRequest" SG_ 1962 FPM1_GST_Byte1 0;
BA_ "NetworkRequestHoldingTime" SG_ 1962 FPM1_GST_Byte1 5000;
BA_ "Version" SG_ 1962 FPM1_GST_Byte1 "21.02.04";
BA_ "GenMsgCycleTime" BO_ 1923 0;
BA_ "GenMsgCycleTimeFast" BO_ 1923 0;
BA_ "GenMsgNrOfRepetition" BO_ 1923 0;
BA_ "DiagRequest" BO_ 1923 1;
BA_ "GenMsgILSupport" BO_ 1923 0;
BA_ "TpMessage" BO_ 1923 1;
BA_ "TpTxIndex" BO_ 1923 16;
BA_ "Description" SG_ 1923 GST_AMP_Byte0 "TP Index : 16";
BA_ "UsrSigPurpose" SG_ 1923 GST_AMP_Byte0 3;
BA_ "UserSigValidity" SG_ 1923 GST_AMP_Byte0 0;
BA_REL_ "GenSigTimeoutTime" BU_SG_REL_ AMP SG_ 1923 GST_AMP_Byte0 0;
BA_REL_ "GenSigTimeoutTime" BU_SG_REL_ vHS_M SG_ 1923 GST_AMP_Byte0 0;
BA_ "NetworkRequest" SG_ 1923 GST_AMP_Byte0 0;
BA_ "NetworkRequestHoldingTime" SG_ 1923 GST_AMP_Byte0 5000;
BA_ "Version" SG_ 1923 GST_AMP_Byte0 "21.02.04";
BA_ "Description" SG_ 1923 GST_AMP_Byte2 "TP Index : 16";
BA_ "UsrSigPurpose" SG_ 1923 GST_AMP_Byte2 3;
BA_ "UserSigValidity" SG_ 1923 GST_AMP_Byte2 0;
BA_REL_ "GenSigTimeoutTime" BU_SG_REL_ AMP SG_ 1923 GST_AMP_Byte2 0;
BA_REL_ "GenSigTimeoutTime" BU_SG_REL_ vHS_M SG_ 1923 GST_AMP_Byte2 0;
BA_ "NetworkRequest" SG_ 1923 GST_AMP_Byte2 0;
BA_ "NetworkRequestHoldingTime" SG_ 1923 GST_AMP_Byte2 5000;
BA_ "Version" SG_ 1923 GST_AMP_Byte2 "21.02.04";
BA_ "Description" SG_ 1923 GST_AMP_Byte3 "TP Index : 16";
BA_ "UsrSigPurpose" SG_ 1923 GST_AMP_Byte3 3;
BA_ "UserSigValidity" SG_ 1923 GST_AMP_Byte3 0;
BA_REL_ "GenSigTimeoutTime" BU_SG_REL_ AMP SG_ 1923 GST_AMP_Byte3 0;
BA_REL_ "GenSigTimeoutTime" BU_SG_REL_ vHS_M SG_ 1923 GST_AMP_Byte3 0;
BA_ "NetworkRequest" SG_ 1923 GST_AMP_Byte3 0;
BA_ "NetworkRequestHoldingTime" SG_ 1923 GST_AMP_Byte3 5000;
BA_ "Version" SG_ 1923 GST_AMP_Byte3 "21.02.04";
BA_ "Description" SG_ 1923 GST_AMP_Byte4 "TP Index : 16";
BA_ "UsrSigPurpose" SG_ 1923 GST_AMP_Byte4 3;
BA_ "UserSigValidity" SG_ 1923 GST_AMP_Byte4 0;
BA_REL_ "GenSigTimeoutTime" BU_SG_REL_ AMP SG_ 1923 GST_AMP_Byte4 0;
BA_REL_ "GenSigTimeoutTime" BU_SG_REL_ vHS_M SG_ 1923 GST_AMP_Byte4 0;
BA_ "NetworkRequest" SG_ 1923 GST_AMP_Byte4 0;
BA_ "NetworkRequestHoldingTime" SG_ 1923 GST_AMP_Byte4 5000;
BA_ "Version" SG_ 1923 GST_AMP_Byte4 "21.02.04";
BA_ "Description" SG_ 1923 GST_AMP_Byte5 "TP Index : 16";
BA_ "UsrSigPurpose" SG_ 1923 GST_AMP_Byte5 3;
BA_ "UserSigValidity" SG_ 1923 GST_AMP_Byte5 0;
BA_REL_ "GenSigTimeoutTime" BU_SG_REL_ AMP SG_ 1923 GST_AMP_Byte5 0;
BA_REL_ "GenSigTimeoutTime" BU_SG_REL_ vHS_M SG_ 1923 GST_AMP_Byte5 0;
BA_ "NetworkRequest" SG_ 1923 GST_AMP_Byte5 0;
BA_ "NetworkRequestHoldingTime" SG_ 1923 GST_AMP_Byte5 5000;
BA_ "Version" SG_ 1923 GST_AMP_Byte5 "21.02.04";
BA_ "Description" SG_ 1923 GST_AMP_Byte6 "TP Index : 16";
BA_ "UsrSigPurpose" SG_ 1923 GST_AMP_Byte6 3;
BA_ "UserSigValidity" SG_ 1923 GST_AMP_Byte6 0;
BA_REL_ "GenSigTimeoutTime" BU_SG_REL_ AMP SG_ 1923 GST_AMP_Byte6 0;
BA_REL_ "GenSigTimeoutTime" BU_SG_REL_ vHS_M SG_ 1923 GST_AMP_Byte6 0;
BA_ "NetworkRequest" SG_ 1923 GST_AMP_Byte6 0;
BA_ "NetworkRequestHoldingTime" SG_ 1923 GST_AMP_Byte6 5000;
BA_ "Version" SG_ 1923 GST_AMP_Byte6 "21.02.04";
BA_ "Description" SG_ 1923 GST_AMP_Byte7 "TP Index : 16";
BA_ "UsrSigPurpose" SG_ 1923 GST_AMP_Byte7 3;
BA_ "UserSigValidity" SG_ 1923 GST_AMP_Byte7 0;
BA_REL_ "GenSigTimeoutTime" BU_SG_REL_ AMP SG_ 1923 GST_AMP_Byte7 0;
BA_REL_ "GenSigTimeoutTime" BU_SG_REL_ vHS_M SG_ 1923 GST_AMP_Byte7 0;
BA_ "NetworkRequest" SG_ 1923 GST_AMP_Byte7 0;
BA_ "NetworkRequestHoldingTime" SG_ 1923 GST_AMP_Byte7 5000;
BA_ "Version" SG_ 1923 GST_AMP_Byte7 "21.02.04";
BA_ "Description" SG_ 1923 GST_AMP_Byte1 "TP Index : 16";
BA_ "UsrSigPurpose" SG_ 1923 GST_AMP_Byte1 3;
BA_ "UserSigValidity" SG_ 1923 GST_AMP_Byte1 0;
BA_REL_ "GenSigTimeoutTime" BU_SG_REL_ AMP SG_ 1923 GST_AMP_Byte1 0;
BA_REL_ "GenSigTimeoutTime" BU_SG_REL_ vHS_M SG_ 1923 GST_AMP_Byte1 0;
BA_ "NetworkRequest" SG_ 1923 GST_AMP_Byte1 0;
BA_ "NetworkRequestHoldingTime" SG_ 1923 GST_AMP_Byte1 5000;
BA_ "Version" SG_ 1923 GST_AMP_Byte1 "21.02.04";
BA_ "GenMsgCycleTime" BO_ 1943 0;
BA_ "GenMsgCycleTimeFast" BO_ 1943 0;
BA_ "GenMsgNrOfRepetition" BO_ 1943 0;
BA_ "DiagRequest" BO_ 1943 1;
BA_ "GenMsgILSupport" BO_ 1943 0;
BA_ "TpMessage" BO_ 1943 1;
BA_ "TpTxIndex" BO_ 1943 109;
BA_ "Description" SG_ 1943 GST_APSU_Byte0 "TP Index : 109";
BA_ "UsrSigPurpose" SG_ 1943 GST_APSU_Byte0 3;
BA_ "UserSigValidity" SG_ 1943 GST_APSU_Byte0 0;
BA_REL_ "GenSigTimeoutTime" BU_SG_REL_ APSM SG_ 1943 GST_APSU_Byte0 0;
BA_REL_ "GenSigTimeoutTime" BU_SG_REL_ vHS_M SG_ 1943 GST_APSU_Byte0 0;
BA_ "NetworkRequest" SG_ 1943 GST_APSU_Byte0 0;
BA_ "NetworkRequestHoldingTime" SG_ 1943 GST_APSU_Byte0 5000;
BA_ "Version" SG_ 1943 GST_APSU_Byte0 "21.02.04";
BA_ "Description" SG_ 1943 GST_APSU_Byte2 "TP Index : 109";
BA_ "UsrSigPurpose" SG_ 1943 GST_APSU_Byte2 3;
BA_ "UserSigValidity" SG_ 1943 GST_APSU_Byte2 0;
BA_REL_ "GenSigTimeoutTime" BU_SG_REL_ APSM SG_ 1943 GST_APSU_Byte2 0;
BA_REL_ "GenSigTimeoutTime" BU_SG_REL_ vHS_M SG_ 1943 GST_APSU_Byte2 0;
BA_ "NetworkRequest" SG_ 1943 GST_APSU_Byte2 0;
BA_ "NetworkRequestHoldingTime" SG_ 1943 GST_APSU_Byte2 5000;
BA_ "Version" SG_ 1943 GST_APSU_Byte2 "21.02.04";
BA_ "Description" SG_ 1943 GST_APSU_Byte3 "TP Index : 109";
BA_ "UsrSigPurpose" SG_ 1943 GST_APSU_Byte3 3;
BA_ "UserSigValidity" SG_ 1943 GST_APSU_Byte3 0;
BA_REL_ "GenSigTimeoutTime" BU_SG_REL_ APSM SG_ 1943 GST_APSU_Byte3 0;
BA_REL_ "GenSigTimeoutTime" BU_SG_REL_ vHS_M SG_ 1943 GST_APSU_Byte3 0;
BA_ "NetworkRequest" SG_ 1943 GST_APSU_Byte3 0;
BA_ "NetworkRequestHoldingTime" SG_ 1943 GST_APSU_Byte3 5000;
BA_ "Version" SG_ 1943 GST_APSU_Byte3 "21.02.04";
BA_ "Description" SG_ 1943 GST_APSU_Byte4 "TP Index : 109";
BA_ "UsrSigPurpose" SG_ 1943 GST_APSU_Byte4 3;
BA_ "UserSigValidity" SG_ 1943 GST_APSU_Byte4 0;
BA_REL_ "GenSigTimeoutTime" BU_SG_REL_ APSM SG_ 1943 GST_APSU_Byte4 0;
BA_REL_ "GenSigTimeoutTime" BU_SG_REL_ vHS_M SG_ 1943 GST_APSU_Byte4 0;
BA_ "NetworkRequest" SG_ 1943 GST_APSU_Byte4 0;
BA_ "NetworkRequestHoldingTime" SG_ 1943 GST_APSU_Byte4 5000;
BA_ "Version" SG_ 1943 GST_APSU_Byte4 "21.02.04";
BA_ "Description" SG_ 1943 GST_APSU_Byte5 "TP Index : 109";
BA_ "UsrSigPurpose" SG_ 1943 GST_APSU_Byte5 3;
BA_ "UserSigValidity" SG_ 1943 GST_APSU_Byte5 0;
BA_REL_ "GenSigTimeoutTime" BU_SG_REL_ APSM SG_ 1943 GST_APSU_Byte5 0;
BA_REL_ "GenSigTimeoutTime" BU_SG_REL_ vHS_M SG_ 1943 GST_APSU_Byte5 0;
BA_ "NetworkRequest" SG_ 1943 GST_APSU_Byte5 0;
BA_ "NetworkRequestHoldingTime" SG_ 1943 GST_APSU_Byte5 5000;
BA_ "Version" SG_ 1943 GST_APSU_Byte5 "21.02.04";
BA_ "Description" SG_ 1943 GST_APSU_Byte6 "TP Index : 109";
BA_ "UsrSigPurpose" SG_ 1943 GST_APSU_Byte6 3;
BA_ "UserSigValidity" SG_ 1943 GST_APSU_Byte6 0;
BA_REL_ "GenSigTimeoutTime" BU_SG_REL_ APSM SG_ 1943 GST_APSU_Byte6 0;
BA_REL_ "GenSigTimeoutTime" BU_SG_REL_ vHS_M SG_ 1943 GST_APSU_Byte6 0;
BA_ "NetworkRequest" SG_ 1943 GST_APSU_Byte6 0;
BA_ "NetworkRequestHoldingTime" SG_ 1943 GST_APSU_Byte6 5000;
BA_ "Version" SG_ 1943 GST_APSU_Byte6 "21.02.04";
BA_ "Description" SG_ 1943 GST_APSU_Byte7 "TP Index : 109";
BA_ "UsrSigPurpose" SG_ 1943 GST_APSU_Byte7 3;
BA_ "UserSigValidity" SG_ 1943 GST_APSU_Byte7 0;
BA_REL_ "GenSigTimeoutTime" BU_SG_REL_ APSM SG_ 1943 GST_APSU_Byte7 0;
BA_REL_ "GenSigTimeoutTime" BU_SG_REL_ vHS_M SG_ 1943 GST_APSU_Byte7 0;
BA_ "NetworkRequest" SG_ 1943 GST_APSU_Byte7 0;
BA_ "NetworkRequestHoldingTime" SG_ 1943 GST_APSU_Byte7 5000;
BA_ "Version" SG_ 1943 GST_APSU_Byte7 "21.02.04";
BA_ "Description" SG_ 1943 GST_APSU_Byte1 "TP Index : 109";
BA_ "UsrSigPurpose" SG_ 1943 GST_APSU_Byte1 3;
BA_ "UserSigValidity" SG_ 1943 GST_APSU_Byte1 0;
BA_REL_ "GenSigTimeoutTime" BU_SG_REL_ APSM SG_ 1943 GST_APSU_Byte1 0;
BA_REL_ "GenSigTimeoutTime" BU_SG_REL_ vHS_M SG_ 1943 GST_APSU_Byte1 0;
BA_ "NetworkRequest" SG_ 1943 GST_APSU_Byte1 0;
BA_ "NetworkRequestHoldingTime" SG_ 1943 GST_APSU_Byte1 5000;
BA_ "Version" SG_ 1943 GST_APSU_Byte1 "21.02.04";
BA_ "GenMsgCycleTime" BO_ 1458 0;
BA_ "GenMsgCycleTimeFast" BO_ 1458 0;
BA_ "GenMsgNrOfRepetition" BO_ 1458 0;
BA_ "DiagRequest" BO_ 1458 1;
BA_ "GenMsgILSupport" BO_ 1458 0;
BA_ "TpMessage" BO_ 1458 1;
BA_ "TpTxIndex" BO_ 1458 212;
BA_ "Description" SG_ 1458 GST_ATS_Byte0 "TP Index : 212";
BA_ "UsrSigPurpose" SG_ 1458 GST_ATS_Byte0 3;
BA_ "UserSigValidity" SG_ 1458 GST_ATS_Byte0 0;
BA_REL_ "GenSigTimeoutTime" BU_SG_REL_ vHS_M SG_ 1458 GST_ATS_Byte0 0;
BA_REL_ "GenSigTimeoutTime" BU_SG_REL_ ATS SG_ 1458 GST_ATS_Byte0 0;
BA_ "NetworkRequest" SG_ 1458 GST_ATS_Byte0 0;
BA_ "NetworkRequestHoldingTime" SG_ 1458 GST_ATS_Byte0 5000;
BA_ "Version" SG_ 1458 GST_ATS_Byte0 "21.02.04";
BA_ "Description" SG_ 1458 GST_ATS_Byte2 "TP Index : 212";
BA_ "UsrSigPurpose" SG_ 1458 GST_ATS_Byte2 3;
BA_ "UserSigValidity" SG_ 1458 GST_ATS_Byte2 0;
BA_REL_ "GenSigTimeoutTime" BU_SG_REL_ vHS_M SG_ 1458 GST_ATS_Byte2 0;
BA_REL_ "GenSigTimeoutTime" BU_SG_REL_ ATS SG_ 1458 GST_ATS_Byte2 0;
BA_ "NetworkRequest" SG_ 1458 GST_ATS_Byte2 0;
BA_ "NetworkRequestHoldingTime" SG_ 1458 GST_ATS_Byte2 5000;
BA_ "Version" SG_ 1458 GST_ATS_Byte2 "21.02.04";
BA_ "Description" SG_ 1458 GST_ATS_Byte3 "TP Index : 212";
BA_ "UsrSigPurpose" SG_ 1458 GST_ATS_Byte3 3;
BA_ "UserSigValidity" SG_ 1458 GST_ATS_Byte3 0;
BA_REL_ "GenSigTimeoutTime" BU_SG_REL_ vHS_M SG_ 1458 GST_ATS_Byte3 0;
BA_REL_ "GenSigTimeoutTime" BU_SG_REL_ ATS SG_ 1458 GST_ATS_Byte3 0;
BA_ "NetworkRequest" SG_ 1458 GST_ATS_Byte3 0;
BA_ "NetworkRequestHoldingTime" SG_ 1458 GST_ATS_Byte3 5000;
BA_ "Version" SG_ 1458 GST_ATS_Byte3 "21.02.04";
BA_ "Description" SG_ 1458 GST_ATS_Byte4 "TP Index : 212";
BA_ "UsrSigPurpose" SG_ 1458 GST_ATS_Byte4 3;
BA_ "UserSigValidity" SG_ 1458 GST_ATS_Byte4 0;
BA_REL_ "GenSigTimeoutTime" BU_SG_REL_ vHS_M SG_ 1458 GST_ATS_Byte4 0;
BA_REL_ "GenSigTimeoutTime" BU_SG_REL_ ATS SG_ 1458 GST_ATS_Byte4 0;
BA_ "NetworkRequest" SG_ 1458 GST_ATS_Byte4 0;
BA_ "NetworkRequestHoldingTime" SG_ 1458 GST_ATS_Byte4 5000;
BA_ "Version" SG_ 1458 GST_ATS_Byte4 "21.02.04";
BA_ "Description" SG_ 1458 GST_ATS_Byte5 "TP Index : 212";
BA_ "UsrSigPurpose" SG_ 1458 GST_ATS_Byte5 3;
BA_ "UserSigValidity" SG_ 1458 GST_ATS_Byte5 0;
BA_REL_ "GenSigTimeoutTime" BU_SG_REL_ vHS_M SG_ 1458 GST_ATS_Byte5 0;
BA_REL_ "GenSigTimeoutTime" BU_SG_REL_ ATS SG_ 1458 GST_ATS_Byte5 0;
BA_ "NetworkRequest" SG_ 1458 GST_ATS_Byte5 0;
BA_ "NetworkRequestHoldingTime" SG_ 1458 GST_ATS_Byte5 5000;
BA_ "Version" SG_ 1458 GST_ATS_Byte5 "21.02.04";
BA_ "Description" SG_ 1458 GST_ATS_Byte6 "TP Index : 212";
BA_ "UsrSigPurpose" SG_ 1458 GST_ATS_Byte6 3;
BA_ "UserSigValidity" SG_ 1458 GST_ATS_Byte6 0;
BA_REL_ "GenSigTimeoutTime" BU_SG_REL_ vHS_M SG_ 1458 GST_ATS_Byte6 0;
BA_REL_ "GenSigTimeoutTime" BU_SG_REL_ ATS SG_ 1458 GST_ATS_Byte6 0;
BA_ "NetworkRequest" SG_ 1458 GST_ATS_Byte6 0;
BA_ "NetworkRequestHoldingTime" SG_ 1458 GST_ATS_Byte6 5000;
BA_ "Version" SG_ 1458 GST_ATS_Byte6 "21.02.04";
BA_ "Description" SG_ 1458 GST_ATS_Byte7 "TP Index : 212";
BA_ "UsrSigPurpose" SG_ 1458 GST_ATS_Byte7 3;
BA_ "UserSigValidity" SG_ 1458 GST_ATS_Byte7 0;
BA_REL_ "GenSigTimeoutTime" BU_SG_REL_ vHS_M SG_ 1458 GST_ATS_Byte7 0;
BA_REL_ "GenSigTimeoutTime" BU_SG_REL_ ATS SG_ 1458 GST_ATS_Byte7 0;
BA_ "NetworkRequest" SG_ 1458 GST_ATS_Byte7 0;
BA_ "NetworkRequestHoldingTime" SG_ 1458 GST_ATS_Byte7 5000;
BA_ "Version" SG_ 1458 GST_ATS_Byte7 "21.02.04";
BA_ "Description" SG_ 1458 GST_ATS_Byte1 "TP Index : 212";
BA_ "UsrSigPurpose" SG_ 1458 GST_ATS_Byte1 3;
BA_ "UserSigValidity" SG_ 1458 GST_ATS_Byte1 0;
BA_REL_ "GenSigTimeoutTime" BU_SG_REL_ vHS_M SG_ 1458 GST_ATS_Byte1 0;
BA_REL_ "GenSigTimeoutTime" BU_SG_REL_ ATS SG_ 1458 GST_ATS_Byte1 0;
BA_ "NetworkRequest" SG_ 1458 GST_ATS_Byte1 0;
BA_ "NetworkRequestHoldingTime" SG_ 1458 GST_ATS_Byte1 5000;
BA_ "Version" SG_ 1458 GST_ATS_Byte1 "21.02.04";
BA_ "GenMsgCycleTime" BO_ 1457 0;
BA_ "GenMsgCycleTimeFast" BO_ 1457 0;
BA_ "GenMsgNrOfRepetition" BO_ 1457 0;
BA_ "DiagRequest" BO_ 1457 1;
BA_ "GenMsgILSupport" BO_ 1457 0;
BA_ "TpMessage" BO_ 1457 1;
BA_ "TpTxIndex" BO_ 1457 211;
BA_ "Description" SG_ 1457 GST_RLSAU_Byte0 "TP Index : 211";
BA_ "UsrSigPurpose" SG_ 1457 GST_RLSAU_Byte0 3;
BA_ "UserSigValidity" SG_ 1457 GST_RLSAU_Byte0 0;
BA_REL_ "GenSigTimeoutTime" BU_SG_REL_ RLPSM SG_ 1457 GST_RLSAU_Byte0 0;
BA_REL_ "GenSigTimeoutTime" BU_SG_REL_ vHS_M SG_ 1457 GST_RLSAU_Byte0 0;
BA_ "NetworkRequest" SG_ 1457 GST_RLSAU_Byte0 0;
BA_ "NetworkRequestHoldingTime" SG_ 1457 GST_RLSAU_Byte0 5000;
BA_ "Version" SG_ 1457 GST_RLSAU_Byte0 "21.02.04";
BA_ "Description" SG_ 1457 GST_RLSAU_Byte2 "TP Index : 211";
BA_ "UsrSigPurpose" SG_ 1457 GST_RLSAU_Byte2 3;
BA_ "UserSigValidity" SG_ 1457 GST_RLSAU_Byte2 0;
BA_REL_ "GenSigTimeoutTime" BU_SG_REL_ RLPSM SG_ 1457 GST_RLSAU_Byte2 0;
BA_REL_ "GenSigTimeoutTime" BU_SG_REL_ vHS_M SG_ 1457 GST_RLSAU_Byte2 0;
BA_ "NetworkRequest" SG_ 1457 GST_RLSAU_Byte2 0;
BA_ "NetworkRequestHoldingTime" SG_ 1457 GST_RLSAU_Byte2 5000;
BA_ "Version" SG_ 1457 GST_RLSAU_Byte2 "21.02.04";
BA_ "Description" SG_ 1457 GST_RLSAU_Byte3 "TP Index : 211";
BA_ "UsrSigPurpose" SG_ 1457 GST_RLSAU_Byte3 3;
BA_ "UserSigValidity" SG_ 1457 GST_RLSAU_Byte3 0;
BA_REL_ "GenSigTimeoutTime" BU_SG_REL_ RLPSM SG_ 1457 GST_RLSAU_Byte3 0;
BA_REL_ "GenSigTimeoutTime" BU_SG_REL_ vHS_M SG_ 1457 GST_RLSAU_Byte3 0;
BA_ "NetworkRequest" SG_ 1457 GST_RLSAU_Byte3 0;
BA_ "NetworkRequestHoldingTime" SG_ 1457 GST_RLSAU_Byte3 5000;
BA_ "Version" SG_ 1457 GST_RLSAU_Byte3 "21.02.04";
BA_ "Description" SG_ 1457 GST_RLSAU_Byte4 "TP Index : 211";
BA_ "UsrSigPurpose" SG_ 1457 GST_RLSAU_Byte4 3;
BA_ "UserSigValidity" SG_ 1457 GST_RLSAU_Byte4 0;
BA_REL_ "GenSigTimeoutTime" BU_SG_REL_ RLPSM SG_ 1457 GST_RLSAU_Byte4 0;
BA_REL_ "GenSigTimeoutTime" BU_SG_REL_ vHS_M SG_ 1457 GST_RLSAU_Byte4 0;
BA_ "NetworkRequest" SG_ 1457 GST_RLSAU_Byte4 0;
BA_ "NetworkRequestHoldingTime" SG_ 1457 GST_RLSAU_Byte4 5000;
BA_ "Version" SG_ 1457 GST_RLSAU_Byte4 "21.02.04";
BA_ "Description" SG_ 1457 GST_RLSAU_Byte5 "TP Index : 211";
BA_ "UsrSigPurpose" SG_ 1457 GST_RLSAU_Byte5 3;
BA_ "UserSigValidity" SG_ 1457 GST_RLSAU_Byte5 0;
BA_REL_ "GenSigTimeoutTime" BU_SG_REL_ RLPSM SG_ 1457 GST_RLSAU_Byte5 0;
BA_REL_ "GenSigTimeoutTime" BU_SG_REL_ vHS_M SG_ 1457 GST_RLSAU_Byte5 0;
BA_ "NetworkRequest" SG_ 1457 GST_RLSAU_Byte5 0;
BA_ "NetworkRequestHoldingTime" SG_ 1457 GST_RLSAU_Byte5 5000;
BA_ "Version" SG_ 1457 GST_RLSAU_Byte5 "21.02.04";
BA_ "Description" SG_ 1457 GST_RLSAU_Byte6 "TP Index : 211";
BA_ "UsrSigPurpose" SG_ 1457 GST_RLSAU_Byte6 3;
BA_ "UserSigValidity" SG_ 1457 GST_RLSAU_Byte6 0;
BA_REL_ "GenSigTimeoutTime" BU_SG_REL_ RLPSM SG_ 1457 GST_RLSAU_Byte6 0;
BA_REL_ "GenSigTimeoutTime" BU_SG_REL_ vHS_M SG_ 1457 GST_RLSAU_Byte6 0;
BA_ "NetworkRequest" SG_ 1457 GST_RLSAU_Byte6 0;
BA_ "NetworkRequestHoldingTime" SG_ 1457 GST_RLSAU_Byte6 5000;
BA_ "Version" SG_ 1457 GST_RLSAU_Byte6 "21.02.04";
BA_ "Description" SG_ 1457 GST_RLSAU_Byte7 "TP Index : 211";
BA_ "UsrSigPurpose" SG_ 1457 GST_RLSAU_Byte7 3;
BA_ "UserSigValidity" SG_ 1457 GST_RLSAU_Byte7 0;
BA_REL_ "GenSigTimeoutTime" BU_SG_REL_ RLPSM SG_ 1457 GST_RLSAU_Byte7 0;
BA_REL_ "GenSigTimeoutTime" BU_SG_REL_ vHS_M SG_ 1457 GST_RLSAU_Byte7 0;
BA_ "NetworkRequest" SG_ 1457 GST_RLSAU_Byte7 0;
BA_ "NetworkRequestHoldingTime" SG_ 1457 GST_RLSAU_Byte7 5000;
BA_ "Version" SG_ 1457 GST_RLSAU_Byte7 "21.02.04";
BA_ "Description" SG_ 1457 GST_RLSAU_Byte1 "TP Index : 211";
BA_ "UsrSigPurpose" SG_ 1457 GST_RLSAU_Byte1 3;
BA_ "UserSigValidity" SG_ 1457 GST_RLSAU_Byte1 0;
BA_REL_ "GenSigTimeoutTime" BU_SG_REL_ RLPSM SG_ 1457 GST_RLSAU_Byte1 0;
BA_REL_ "GenSigTimeoutTime" BU_SG_REL_ vHS_M SG_ 1457 GST_RLSAU_Byte1 0;
BA_ "NetworkRequest" SG_ 1457 GST_RLSAU_Byte1 0;
BA_ "NetworkRequestHoldingTime" SG_ 1457 GST_RLSAU_Byte1 5000;
BA_ "Version" SG_ 1457 GST_RLSAU_Byte1 "21.02.04";
BA_ "GenMsgCycleTime" BO_ 1456 0;
BA_ "GenMsgCycleTimeFast" BO_ 1456 0;
BA_ "GenMsgNrOfRepetition" BO_ 1456 0;
BA_ "DiagRequest" BO_ 1456 1;
BA_ "GenMsgILSupport" BO_ 1456 0;
BA_ "TpMessage" BO_ 1456 1;
BA_ "TpTxIndex" BO_ 1456 210;
BA_ "Description" SG_ 1456 GST_RRSAU_Byte0 "TP Index : 210";
BA_ "UsrSigPurpose" SG_ 1456 GST_RRSAU_Byte0 3;
BA_ "UserSigValidity" SG_ 1456 GST_RRSAU_Byte0 0;
BA_REL_ "GenSigTimeoutTime" BU_SG_REL_ RLPSM SG_ 1456 GST_RRSAU_Byte0 0;
BA_REL_ "GenSigTimeoutTime" BU_SG_REL_ vHS_M SG_ 1456 GST_RRSAU_Byte0 0;
BA_ "NetworkRequest" SG_ 1456 GST_RRSAU_Byte0 0;
BA_ "NetworkRequestHoldingTime" SG_ 1456 GST_RRSAU_Byte0 5000;
BA_ "Version" SG_ 1456 GST_RRSAU_Byte0 "21.02.04";
BA_ "Description" SG_ 1456 GST_RRSAU_Byte2 "TP Index : 210";
BA_ "UsrSigPurpose" SG_ 1456 GST_RRSAU_Byte2 3;
BA_ "UserSigValidity" SG_ 1456 GST_RRSAU_Byte2 0;
BA_REL_ "GenSigTimeoutTime" BU_SG_REL_ RLPSM SG_ 1456 GST_RRSAU_Byte2 0;
BA_REL_ "GenSigTimeoutTime" BU_SG_REL_ vHS_M SG_ 1456 GST_RRSAU_Byte2 0;
BA_ "NetworkRequest" SG_ 1456 GST_RRSAU_Byte2 0;
BA_ "NetworkRequestHoldingTime" SG_ 1456 GST_RRSAU_Byte2 5000;
BA_ "Version" SG_ 1456 GST_RRSAU_Byte2 "21.02.04";
BA_ "Description" SG_ 1456 GST_RRSAU_Byte3 "TP Index : 210";
BA_ "UsrSigPurpose" SG_ 1456 GST_RRSAU_Byte3 3;
BA_ "UserSigValidity" SG_ 1456 GST_RRSAU_Byte3 0;
BA_REL_ "GenSigTimeoutTime" BU_SG_REL_ RLPSM SG_ 1456 GST_RRSAU_Byte3 0;
BA_REL_ "GenSigTimeoutTime" BU_SG_REL_ vHS_M SG_ 1456 GST_RRSAU_Byte3 0;
BA_ "NetworkRequest" SG_ 1456 GST_RRSAU_Byte3 0;
BA_ "NetworkRequestHoldingTime" SG_ 1456 GST_RRSAU_Byte3 5000;
BA_ "Version" SG_ 1456 GST_RRSAU_Byte3 "21.02.04";
BA_ "Description" SG_ 1456 GST_RRSAU_Byte4 "TP Index : 210";
BA_ "UsrSigPurpose" SG_ 1456 GST_RRSAU_Byte4 3;
BA_ "UserSigValidity" SG_ 1456 GST_RRSAU_Byte4 0;
BA_REL_ "GenSigTimeoutTime" BU_SG_REL_ RLPSM SG_ 1456 GST_RRSAU_Byte4 0;
BA_REL_ "GenSigTimeoutTime" BU_SG_REL_ vHS_M SG_ 1456 GST_RRSAU_Byte4 0;
BA_ "NetworkRequest" SG_ 1456 GST_RRSAU_Byte4 0;
BA_ "NetworkRequestHoldingTime" SG_ 1456 GST_RRSAU_Byte4 5000;
BA_ "Version" SG_ 1456 GST_RRSAU_Byte4 "21.02.04";
BA_ "Description" SG_ 1456 GST_RRSAU_Byte5 "TP Index : 210";
BA_ "UsrSigPurpose" SG_ 1456 GST_RRSAU_Byte5 3;
BA_ "UserSigValidity" SG_ 1456 GST_RRSAU_Byte5 0;
BA_REL_ "GenSigTimeoutTime" BU_SG_REL_ RLPSM SG_ 1456 GST_RRSAU_Byte5 0;
BA_REL_ "GenSigTimeoutTime" BU_SG_REL_ vHS_M SG_ 1456 GST_RRSAU_Byte5 0;
BA_ "NetworkRequest" SG_ 1456 GST_RRSAU_Byte5 0;
BA_ "NetworkRequestHoldingTime" SG_ 1456 GST_RRSAU_Byte5 5000;
BA_ "Version" SG_ 1456 GST_RRSAU_Byte5 "21.02.04";
BA_ "Description" SG_ 1456 GST_RRSAU_Byte6 "TP Index : 210";
BA_ "UsrSigPurpose" SG_ 1456 GST_RRSAU_Byte6 3;
BA_ "UserSigValidity" SG_ 1456 GST_RRSAU_Byte6 0;
BA_REL_ "GenSigTimeoutTime" BU_SG_REL_ RLPSM SG_ 1456 GST_RRSAU_Byte6 0;
BA_REL_ "GenSigTimeoutTime" BU_SG_REL_ vHS_M SG_ 1456 GST_RRSAU_Byte6 0;
BA_ "NetworkRequest" SG_ 1456 GST_RRSAU_Byte6 0;
BA_ "NetworkRequestHoldingTime" SG_ 1456 GST_RRSAU_Byte6 5000;
BA_ "Version" SG_ 1456 GST_RRSAU_Byte6 "21.02.04";
BA_ "Description" SG_ 1456 GST_RRSAU_Byte7 "TP Index : 210";
BA_ "UsrSigPurpose" SG_ 1456 GST_RRSAU_Byte7 3;
BA_ "UserSigValidity" SG_ 1456 GST_RRSAU_Byte7 0;
BA_REL_ "GenSigTimeoutTime" BU_SG_REL_ RLPSM SG_ 1456 GST_RRSAU_Byte7 0;
BA_REL_ "GenSigTimeoutTime" BU_SG_REL_ vHS_M SG_ 1456 GST_RRSAU_Byte7 0;
BA_ "NetworkRequest" SG_ 1456 GST_RRSAU_Byte7 0;
BA_ "NetworkRequestHoldingTime" SG_ 1456 GST_RRSAU_Byte7 5000;
BA_ "Version" SG_ 1456 GST_RRSAU_Byte7 "21.02.04";
BA_ "Description" SG_ 1456 GST_RRSAU_Byte1 "TP Index : 210";
BA_ "UsrSigPurpose" SG_ 1456 GST_RRSAU_Byte1 3;
BA_ "UserSigValidity" SG_ 1456 GST_RRSAU_Byte1 0;
BA_REL_ "GenSigTimeoutTime" BU_SG_REL_ RLPSM SG_ 1456 GST_RRSAU_Byte1 0;
BA_REL_ "GenSigTimeoutTime" BU_SG_REL_ vHS_M SG_ 1456 GST_RRSAU_Byte1 0;
BA_ "NetworkRequest" SG_ 1456 GST_RRSAU_Byte1 0;
BA_ "NetworkRequestHoldingTime" SG_ 1456 GST_RRSAU_Byte1 5000;
BA_ "Version" SG_ 1456 GST_RRSAU_Byte1 "21.02.04";
BA_ "GenMsgCycleTime" BO_ 2563125249 0;
BA_ "VFrameFormat" BO_ 2563125249 1;
BA_ "Description" SG_ 2563125249 AMP_Beep2Mode "Play touch beep sound for rear monitor";
BA_ "GenSigSendType" SG_ 2563125249 AMP_Beep2Mode 4;
BA_ "UserSigValidity" SG_ 2563125249 AMP_Beep2Mode 0;
BA_ "Version" SG_ 2563125249 AMP_Beep2Mode "19.06.02";
BA_ "GenSigSendType" SG_ 2563125249 AMP_Beep1Mode 4;
BA_ "GenSigStartValue" SG_ 2563125249 AMP_Beep1Mode 3;
BA_ "UserSigValidity" SG_ 2563125249 AMP_Beep1Mode 1;
BA_REL_ "GenSigTimeoutTime" BU_SG_REL_ AMP SG_ 2563125249 AMP_Beep1Mode 0;
BA_REL_ "GenSigTimeoutTime" BU_SG_REL_ ATS SG_ 2563125249 AMP_Beep1Mode 0;
BA_ "NetworkRequest" SG_ 2563125249 AMP_Beep1Mode 0;
BA_ "Version" SG_ 2563125249 AMP_Beep1Mode "18.12.06";
BA_ "Description" SG_ 2563125249 AMP_MasterBeepVolumeStep "MasterBeepVolumeStep (1/2/3/4/5)";
BA_ "GenSigSendType" SG_ 2563125249 AMP_MasterBeepVolumeStep 4;
BA_ "UserSigValidity" SG_ 2563125249 AMP_MasterBeepVolumeStep 1;
BA_REL_ "GenSigTimeoutTime" BU_SG_REL_ AMP SG_ 2563125249 AMP_MasterBeepVolumeStep 0;
BA_ "NetworkRequest" SG_ 2563125249 AMP_MasterBeepVolumeStep 0;
BA_ "Version" SG_ 2563125249 AMP_MasterBeepVolumeStep "20.07.03";
BA_ "Description" SG_ 2563125249 AMP_RrTTSSound "This signal is  Rear TTS output state information";
BA_ "GenSigSendType" SG_ 2563125249 AMP_RrTTSSound 4;
BA_ "GenSigStartValue" SG_ 2563125249 AMP_RrTTSSound 3;
BA_ "UserSigValidity" SG_ 2563125249 AMP_RrTTSSound 1;
BA_REL_ "GenSigTimeoutTime" BU_SG_REL_ AMP SG_ 2563125249 AMP_RrTTSSound 0;
BA_ "Version" SG_ 2563125249 AMP_RrTTSSound "19.12.01";
BA_ "GenSigSendType" SG_ 2563125249 AMP_ASDMode 4;
BA_ "GenSigStartValue" SG_ 2563125249 AMP_ASDMode 7;
BA_ "UserSigValidity" SG_ 2563125249 AMP_ASDMode 1;
BA_REL_ "GenSigTimeoutTime" BU_SG_REL_ AMP SG_ 2563125249 AMP_ASDMode 0;
BA_ "NetworkRequest" SG_ 2563125249 AMP_ASDMode 0;
BA_ "Version" SG_ 2563125249 AMP_ASDMode "18.12.06";
BA_ "GenSigSendType" SG_ 2563125249 AMP_ANCMode 4;
BA_ "GenSigStartValue" SG_ 2563125249 AMP_ANCMode 3;
BA_ "UserSigValidity" SG_ 2563125249 AMP_ANCMode 1;
BA_REL_ "GenSigTimeoutTime" BU_SG_REL_ AMP SG_ 2563125249 AMP_ANCMode 0;
BA_ "Version" SG_ 2563125249 AMP_ANCMode "18.12.06";
BA_ "Description" SG_ 2563125249 AMP_VirtualVenueMode "Select VV mode";
BA_ "GenSigSendType" SG_ 2563125249 AMP_VirtualVenueMode 4;
BA_ "GenSigStartValue" SG_ 2563125249 AMP_VirtualVenueMode 7;
BA_ "UserSigValidity" SG_ 2563125249 AMP_VirtualVenueMode 1;
BA_REL_ "GenSigTimeoutTime" BU_SG_REL_ AMP SG_ 2563125249 AMP_VirtualVenueMode 0;
BA_ "NetworkRequest" SG_ 2563125249 AMP_VirtualVenueMode 0;
BA_ "Version" SG_ 2563125249 AMP_VirtualVenueMode "19.08.08";
BA_ "Description" SG_ 2563125249 AMP_QLIMode "Select QLI mode";
BA_ "GenSigSendType" SG_ 2563125249 AMP_QLIMode 4;
BA_ "GenSigStartValue" SG_ 2563125249 AMP_QLIMode 7;
BA_ "UserSigValidity" SG_ 2563125249 AMP_QLIMode 1;
BA_REL_ "GenSigTimeoutTime" BU_SG_REL_ AMP SG_ 2563125249 AMP_QLIMode 0;
BA_ "NetworkRequest" SG_ 2563125249 AMP_QLIMode 0;
BA_ "Version" SG_ 2563125249 AMP_QLIMode "19.08.08";
BA_ "Description" SG_ 2563125249 AMP_DriverMode "Turn On/Off Driver mode";
BA_ "GenSigSendType" SG_ 2563125249 AMP_DriverMode 4;
BA_ "GenSigStartValue" SG_ 2563125249 AMP_DriverMode 3;
BA_ "UserSigValidity" SG_ 2563125249 AMP_DriverMode 1;
BA_REL_ "GenSigTimeoutTime" BU_SG_REL_ AMP SG_ 2563125249 AMP_DriverMode 0;
BA_ "NetworkRequest" SG_ 2563125249 AMP_DriverMode 0;
BA_ "Version" SG_ 2563125249 AMP_DriverMode "19.08.08";
BA_ "GenSigSendType" SG_ 2563125249 AMP_NaviSound 4;
BA_ "GenSigStartValue" SG_ 2563125249 AMP_NaviSound 3;
BA_ "UserSigValidity" SG_ 2563125249 AMP_NaviSound 1;
BA_REL_ "GenSigTimeoutTime" BU_SG_REL_ AMP SG_ 2563125249 AMP_NaviSound 0;
BA_ "Version" SG_ 2563125249 AMP_NaviSound "19.01.05";
BA_ "Description" SG_ 2563125249 AMP_VESSMixing "Turn On/Off VESS mixing";
BA_ "GenSigSendType" SG_ 2563125249 AMP_VESSMixing 4;
BA_ "GenSigStartValue" SG_ 2563125249 AMP_VESSMixing 3;
BA_ "UserSigValidity" SG_ 2563125249 AMP_VESSMixing 1;
BA_ "NetworkRequest" SG_ 2563125249 AMP_VESSMixing 0;
BA_ "Version" SG_ 2563125249 AMP_VESSMixing "19.08.08";
BA_ "Description" SG_ 2563125249 AMP_VESSMusicOut "Turn On/Off VESS Music out";
BA_ "GenSigSendType" SG_ 2563125249 AMP_VESSMusicOut 4;
BA_ "GenSigStartValue" SG_ 2563125249 AMP_VESSMusicOut 3;
BA_ "UserSigValidity" SG_ 2563125249 AMP_VESSMusicOut 1;
BA_ "NetworkRequest" SG_ 2563125249 AMP_VESSMusicOut 0;
BA_ "Version" SG_ 2563125249 AMP_VESSMusicOut "19.08.08";
BA_ "Description" SG_ 2563125249 AMP_VoiceGuideTTS "Play VoiceGuide TTS";
BA_ "GenSigSendType" SG_ 2563125249 AMP_VoiceGuideTTS 4;
BA_ "GenSigStartValue" SG_ 2563125249 AMP_VoiceGuideTTS 3;
BA_ "UserSigValidity" SG_ 2563125249 AMP_VoiceGuideTTS 1;
BA_REL_ "GenSigTimeoutTime" BU_SG_REL_ AMP SG_ 2563125249 AMP_VoiceGuideTTS 0;
BA_ "NetworkRequest" SG_ 2563125249 AMP_VoiceGuideTTS 0;
BA_ "Version" SG_ 2563125249 AMP_VoiceGuideTTS "19.08.08";
BA_ "Description" SG_ 2563125249 AMP_Beep1KBDMode "Play touch beep sound at keyboard screen on AVN

This Signal's Feedback is AMP_Beep1KBDModeState@AMP";
BA_ "GenSigSendType" SG_ 2563125249 AMP_Beep1KBDMode 4;
BA_ "GenSigStartValue" SG_ 2563125249 AMP_Beep1KBDMode 3;
BA_ "UserSigValidity" SG_ 2563125249 AMP_Beep1KBDMode 1;
BA_REL_ "GenSigTimeoutTime" BU_SG_REL_ AMP SG_ 2563125249 AMP_Beep1KBDMode 0;
BA_ "Version" SG_ 2563125249 AMP_Beep1KBDMode "20.06.01";
BA_ "Description" SG_ 2563125249 AMP_VoiceGuideTTSLevel "Set VoiceGuide volume level";
BA_ "GenSigSendType" SG_ 2563125249 AMP_VoiceGuideTTSLevel 4;
BA_ "GenSigStartValue" SG_ 2563125249 AMP_VoiceGuideTTSLevel 7;
BA_ "UserSigValidity" SG_ 2563125249 AMP_VoiceGuideTTSLevel 1;
BA_REL_ "GenSigTimeoutTime" BU_SG_REL_ AMP SG_ 2563125249 AMP_VoiceGuideTTSLevel 0;
BA_ "NetworkRequest" SG_ 2563125249 AMP_VoiceGuideTTSLevel 0;
BA_ "Version" SG_ 2563125249 AMP_VoiceGuideTTSLevel "19.08.08";
BA_ "Description" SG_ 2563125249 AMP_ALTPopUpReq "Request ALT to PopUp or Close";
BA_ "GenSigSendType" SG_ 2563125249 AMP_ALTPopUpReq 4;
BA_ "GenSigStartValue" SG_ 2563125249 AMP_ALTPopUpReq 3;
BA_ "UserSigValidity" SG_ 2563125249 AMP_ALTPopUpReq 1;
BA_REL_ "GenSigTimeoutTime" BU_SG_REL_ AMP SG_ 2563125249 AMP_ALTPopUpReq 0;
BA_ "NetworkRequest" SG_ 2563125249 AMP_ALTPopUpReq 0;
BA_ "Version" SG_ 2563125249 AMP_ALTPopUpReq "19.08.08";
BA_ "Description" SG_ 2563125249 AMP_TTSSound "This signal is  TTS output state information";
BA_ "GenSigSendType" SG_ 2563125249 AMP_TTSSound 4;
BA_ "GenSigStartValue" SG_ 2563125249 AMP_TTSSound 3;
BA_ "UserSigValidity" SG_ 2563125249 AMP_TTSSound 1;
BA_REL_ "GenSigTimeoutTime" BU_SG_REL_ AMP SG_ 2563125249 AMP_TTSSound 0;
BA_ "Version" SG_ 2563125249 AMP_TTSSound "19.07.06";
BA_ "GenSigSendType" SG_ 2563125249 AMP_SDVCStep 4;
BA_ "UserSigValidity" SG_ 2563125249 AMP_SDVCStep 1;
BA_REL_ "GenSigTimeoutTime" BU_SG_REL_ AMP SG_ 2563125249 AMP_SDVCStep 0;
BA_ "NetworkRequest" SG_ 2563125249 AMP_SDVCStep 0;
BA_ "Version" SG_ 2563125249 AMP_SDVCStep "18.12.06";
BA_ "GenMsgCycleTime" BO_ 2563125761 0;
BA_ "VFrameFormat" BO_ 2563125761 1;
BA_ "GenSigSendType" SG_ 2563125761 AMP_LogSnapshot 4;
BA_ "GenSigStartValue" SG_ 2563125761 AMP_LogSnapshot 3;
BA_ "UserSigValidity" SG_ 2563125761 AMP_LogSnapshot 1;
BA_REL_ "GenSigTimeoutTime" BU_SG_REL_ AMP SG_ 2563125761 AMP_LogSnapshot 0;
BA_ "Version" SG_ 2563125761 AMP_LogSnapshot "20.07.05";
BA_ "GenSigSendType" SG_ 2563125761 AMP_VersionReq 4;
BA_ "UserSigValidity" SG_ 2563125761 AMP_VersionReq 1;
BA_REL_ "GenSigTimeoutTime" BU_SG_REL_ AMP SG_ 2563125761 AMP_VersionReq 0;
BA_ "NetworkRequest" SG_ 2563125761 AMP_VersionReq 0;
BA_ "Version" SG_ 2563125761 AMP_VersionReq "18.12.06";
BA_ "GenMsgCycleTime" BO_ 2458167553 0;
BA_ "VFrameFormat" BO_ 2458167553 1;
BA_ "GenSigSendType" SG_ 2458167553 C_PTGMNValueSet 4;
BA_ "UserSigValidity" SG_ 2458167553 C_PTGMNValueSet 3;
BA_ "Version" SG_ 2458167553 C_PTGMNValueSet "18.09.04";
BA_ "GenSigSendType" SG_ 2458167553 CF_AVN_PSMNValueSet 4;
BA_ "UserSigValidity" SG_ 2458167553 CF_AVN_PSMNValueSet 3;
BA_REL_ "GenSigTimeoutTime" BU_SG_REL_ PSM SG_ 2458167553 CF_AVN_PSMNValueSet 0;
BA_ "Version" SG_ 2458167553 CF_AVN_PSMNValueSet "18.09.04";
BA_ "GenSigSendType" SG_ 2458167553 C_HfreeTrunkTgNValueSet 4;
BA_ "UserSigValidity" SG_ 2458167553 C_HfreeTrunkTgNValueSet 3;
BA_ "Version" SG_ 2458167553 C_HfreeTrunkTgNValueSet "18.09.04";
BA_ "GenSigSendType" SG_ 2458167553 CF_AVN_TrfChgSet 4;
BA_ "UserSigValidity" SG_ 2458167553 CF_AVN_TrfChgSet 3;
BA_ "Version" SG_ 2458167553 CF_AVN_TrfChgSet "18.09.04";
BA_ "GenSigSendType" SG_ 2458167553 CF_AVN_SCMNValueSet 4;
BA_ "UserSigValidity" SG_ 2458167553 CF_AVN_SCMNValueSet 3;
BA_ "Version" SG_ 2458167553 CF_AVN_SCMNValueSet "18.09.04";
BA_ "GenSigSendType" SG_ 2458167553 CF_AVN_ADrUNValueSet 4;
BA_ "UserSigValidity" SG_ 2458167553 CF_AVN_ADrUNValueSet 3;
BA_ "Version" SG_ 2458167553 CF_AVN_ADrUNValueSet "18.09.04";
BA_ "GenSigSendType" SG_ 2458167553 CF_AVN_OTTurnNValueSet 4;
BA_ "UserSigValidity" SG_ 2458167553 CF_AVN_OTTurnNValueSet 3;
BA_ "Version" SG_ 2458167553 CF_AVN_OTTurnNValueSet "18.09.04";
BA_ "GenSigSendType" SG_ 2458167553 CF_Gway_WPCNValueSet 4;
BA_ "UserSigValidity" SG_ 2458167553 CF_Gway_WPCNValueSet 3;
BA_ "Version" SG_ 2458167553 CF_Gway_WPCNValueSet "18.09.04";
BA_ "GenSigSendType" SG_ 2458167553 C_AVN_RearWiperNValueSet 4;
BA_ "UserSigValidity" SG_ 2458167553 C_AVN_RearWiperNValueSet 3;
BA_ "Version" SG_ 2458167553 C_AVN_RearWiperNValueSet "18.09.04";
BA_ "GenSigSendType" SG_ 2458167553 C_UnlockWelocomeNValueSet 4;
BA_ "UserSigValidity" SG_ 2458167553 C_UnlockWelocomeNValueSet 3;
BA_ "Version" SG_ 2458167553 C_UnlockWelocomeNValueSet "18.09.04";
BA_ "GenSigSendType" SG_ 2458167553 C_SmartWelocomeNValueSet 4;
BA_ "UserSigValidity" SG_ 2458167553 C_SmartWelocomeNValueSet 3;
BA_ "Version" SG_ 2458167553 C_SmartWelocomeNValueSet "18.09.04";
BA_ "GenSigSendType" SG_ 2458167553 CF_AVN_PTGSpeedNValueSet 4;
BA_ "UserSigValidity" SG_ 2458167553 CF_AVN_PTGSpeedNValueSet 3;
BA_ "Version" SG_ 2458167553 CF_AVN_PTGSpeedNValueSet "18.09.04";
BA_ "GenSigSendType" SG_ 2458167553 CR_Datc_DRSeatWheel_USM_Set 4;
BA_ "UserSigValidity" SG_ 2458167553 CR_Datc_DRSeatWheel_USM_Set 3;
BA_ "Version" SG_ 2458167553 CR_Datc_DRSeatWheel_USM_Set "18.09.04";
BA_ "GenSigSendType" SG_ 2458167553 CF_AVN_SequencialLampNValue 4;
BA_ "GenSigStartValue" SG_ 2458167553 CF_AVN_SequencialLampNValue 3;
BA_ "UserSigValidity" SG_ 2458167553 CF_AVN_SequencialLampNValue 3;
BA_ "Version" SG_ 2458167553 CF_AVN_SequencialLampNValue "18.09.04";
BA_ "GenSigSendType" SG_ 2458167553 CF_AVN_TTUnlockNValueSet 4;
BA_ "GenSigStartValue" SG_ 2458167553 CF_AVN_TTUnlockNValueSet 3;
BA_ "UserSigValidity" SG_ 2458167553 CF_AVN_TTUnlockNValueSet 3;
BA_ "Version" SG_ 2458167553 CF_AVN_TTUnlockNValueSet "18.09.04";
BA_ "GenSigSendType" SG_ 2458167553 CF_Gway_RWPCNValueSet 4;
BA_ "UserSigValidity" SG_ 2458167553 CF_Gway_RWPCNValueSet 3;
BA_REL_ "GenSigTimeoutTime" BU_SG_REL_ RWPC SG_ 2458167553 CF_Gway_RWPCNValueSet 0;
BA_ "Version" SG_ 2458167553 CF_Gway_RWPCNValueSet "18.09.04";
BA_ "GenSigSendType" SG_ 2458167553 CF_Avn_BolsterNValueSet 4;
BA_ "UserSigValidity" SG_ 2458167553 CF_Avn_BolsterNValueSet 3;
BA_ "Version" SG_ 2458167553 CF_Avn_BolsterNValueSet "18.09.04";
BA_ "GenSigSendType" SG_ 2458167553 C_PSDNValueSet 4;
BA_ "UserSigValidity" SG_ 2458167553 C_PSDNValueSet 3;
BA_ "Version" SG_ 2458167553 C_PSDNValueSet "18.12.01";
BA_ "GenSigSendType" SG_ 2458167553 C_StrWheelAutoHeatNValueSet 4;
BA_ "UserSigValidity" SG_ 2458167553 C_StrWheelAutoHeatNValueSet 3;
BA_ "Version" SG_ 2458167553 C_StrWheelAutoHeatNValueSet "18.09.04";
BA_ "GenSigSendType" SG_ 2458167553 CF_Avn_HAPTICWARNINGNValueSet 4;
BA_ "UserSigValidity" SG_ 2458167553 CF_Avn_HAPTICWARNINGNValueSet 3;
BA_ "Version" SG_ 2458167553 CF_Avn_HAPTICWARNINGNValueSet "18.12.01";
BA_ "GenSigSendType" SG_ 2458167553 CF_AVN_ADrLNValueSet 4;
BA_ "UserSigValidity" SG_ 2458167553 CF_AVN_ADrLNValueSet 3;
BA_ "Version" SG_ 2458167553 CF_AVN_ADrLNValueSet "18.09.04";
BA_ "GenSigSendType" SG_ 2458167553 CR_Datc_DRSeatHeat_USM_Set 4;
BA_ "UserSigValidity" SG_ 2458167553 CR_Datc_DRSeatHeat_USM_Set 3;
BA_ "Version" SG_ 2458167553 CR_Datc_DRSeatHeat_USM_Set "18.09.04";
BA_ "GenSigSendType" SG_ 2458167553 C_WALNValueSet 4;
BA_ "UserSigValidity" SG_ 2458167553 C_WALNValueSet 3;
BA_ "Version" SG_ 2458167553 C_WALNValueSet "18.09.04";
BA_ "GenSigSendType" SG_ 2458167553 C_ApprUnlockNValue 4;
BA_ "UserSigValidity" SG_ 2458167553 C_ApprUnlockNValue 3;
BA_ "Version" SG_ 2458167553 C_ApprUnlockNValue "18.09.04";
BA_ "Description" SG_ 2458167553 CF_AVN_SEW_NEWNValueSet "This siganl is used for SEW from KA4/NX4.

Before KA4, SEA and SDW are merged using CF_AVN_SEANValueSet@HU_USM_E_01";
BA_ "GenSigSendType" SG_ 2458167553 CF_AVN_SEW_NEWNValueSet 4;
BA_ "UserSigValidity" SG_ 2458167553 CF_AVN_SEW_NEWNValueSet 3;
BA_ "Version" SG_ 2458167553 CF_AVN_SEW_NEWNValueSet "19.09.05";
BA_ "Description" SG_ 2458167553 CF_AVN_SEA_NEWNValueSet "This signal is userd for SEA from KA4/NX4.

Before KA4, SEA and SEW are merged using CF_AVN_SEANValueSet@HU_USM_E_01";
BA_ "GenSigSendType" SG_ 2458167553 CF_AVN_SEA_NEWNValueSet 4;
BA_ "UserSigValidity" SG_ 2458167553 CF_AVN_SEA_NEWNValueSet 3;
BA_ "Version" SG_ 2458167553 CF_AVN_SEA_NEWNValueSet "19.09.05";
BA_ "GenSigSendType" SG_ 2458167553 CF_AVN_TunnelWindowNvalueSet 4;
BA_ "UserSigValidity" SG_ 2458167553 CF_AVN_TunnelWindowNvalueSet 3;
BA_ "Version" SG_ 2458167553 CF_AVN_TunnelWindowNvalueSet "18.09.04";
BA_ "GenSigSendType" SG_ 2458167553 CF_AVN_EscortHLNValueSet 4;
BA_ "UserSigValidity" SG_ 2458167553 CF_AVN_EscortHLNValueSet 3;
BA_ "Version" SG_ 2458167553 CF_AVN_EscortHLNValueSet "18.09.04";
BA_ "GenMsgSendType" BO_ 961 0;
BA_ "Description" SG_ 961 MFSW_Crc1Val "The data area for CRC calculation is based on the data length (DLC) of the message DB.

The CRC shall be calculated over the entire data block (excluding the CRC bytes) including the user data, alive counter and Data ID 

 

- CRC Polynomial (0x1D) , Initial Value : 0x00, XOR value : 0xFF, Data ID Mode : Both, Data ID : Message ID + 0xF800 

- The initial value is for CRC calculation and the message should be sent with the calculated result value. 

The mathematical expression to 8 bit CRC polynomial is given here. G(x) = x8 + x4 + x3 + x2 + 1";
BA_ "GenSigSendType" SG_ 961 MFSW_Crc1Val 4;
BA_ "GenSigStartValue" SG_ 961 MFSW_Crc1Val 255;
BA_ "UserSigValidity" SG_ 961 MFSW_Crc1Val 0;
BA_ "Version" SG_ 961 MFSW_Crc1Val "18.11.08";
BA_ "Description" SG_ 961 MFSW_AlvCnt1Val "For the first transmission request for a data element the counter shall be initialized with 0 and shall be incremented by 1

for every subsequent send request. When the counter reaches the maximum value(0xE), then it shall restart with 0 for the next send request";
BA_ "GenSigSendType" SG_ 961 MFSW_AlvCnt1Val 4;
BA_ "UserSigValidity" SG_ 961 MFSW_AlvCnt1Val 0;
BA_ "Version" SG_ 961 MFSW_AlvCnt1Val "18.11.08";
BA_ "GenSigSendType" SG_ 961 Lamp_HdLmpHiSwSta 4;
BA_ "UserSigValidity" SG_ 961 Lamp_HdLmpHiSwSta 0;
BA_ "NetworkRequest" SG_ 961 Lamp_HdLmpHiSwSta 0;
BA_ "NetworkRequestHoldingTime" SG_ 961 Lamp_HdLmpHiSwSta 5000;
BA_ "Version" SG_ 961 Lamp_HdLmpHiSwSta "17.12.08";
BA_ "GenSigSendType" SG_ 961 Lamp_LtSwSta 4;
BA_ "UserSigValidity" SG_ 961 Lamp_LtSwSta 0;
BA_ "NetworkRequest" SG_ 961 Lamp_LtSwSta 0;
BA_ "NetworkRequestHoldingTime" SG_ 961 Lamp_LtSwSta 5000;
BA_ "Version" SG_ 961 Lamp_LtSwSta "17.12.08";
BA_ "GenSigSendType" SG_ 961 Lamp_PassingLmpSwSta 4;
BA_ "UserSigValidity" SG_ 961 Lamp_PassingLmpSwSta 0;
BA_ "NetworkRequest" SG_ 961 Lamp_PassingLmpSwSta 0;
BA_ "NetworkRequestHoldingTime" SG_ 961 Lamp_PassingLmpSwSta 5000;
BA_ "Version" SG_ 961 Lamp_PassingLmpSwSta "17.12.08";
BA_ "GenSigSendType" SG_ 961 Lamp_RrFogLmpSwSta 4;
BA_ "UserSigValidity" SG_ 961 Lamp_RrFogLmpSwSta 0;
BA_ "NetworkRequest" SG_ 961 Lamp_RrFogLmpSwSta 0;
BA_ "NetworkRequestHoldingTime" SG_ 961 Lamp_RrFogLmpSwSta 5000;
BA_ "Version" SG_ 961 Lamp_RrFogLmpSwSta "17.12.08";
BA_ "GenSigSendType" SG_ 961 Lamp_TrnSigLftSwSta 4;
BA_ "UserSigValidity" SG_ 961 Lamp_TrnSigLftSwSta 0;
BA_REL_ "GenSigTimeoutTime" BU_SG_REL_ ICC SG_ 961 Lamp_TrnSigLftSwSta 1500;
BA_ "NetworkRequest" SG_ 961 Lamp_TrnSigLftSwSta 0;
BA_ "NetworkRequestHoldingTime" SG_ 961 Lamp_TrnSigLftSwSta 5000;
BA_ "Version" SG_ 961 Lamp_TrnSigLftSwSta "17.12.08";
BA_ "GenSigSendType" SG_ 961 Lamp_TrnSigRtSwSta 4;
BA_ "UserSigValidity" SG_ 961 Lamp_TrnSigRtSwSta 0;
BA_REL_ "GenSigTimeoutTime" BU_SG_REL_ ICC SG_ 961 Lamp_TrnSigRtSwSta 1500;
BA_ "NetworkRequest" SG_ 961 Lamp_TrnSigRtSwSta 0;
BA_ "NetworkRequestHoldingTime" SG_ 961 Lamp_TrnSigRtSwSta 5000;
BA_ "Version" SG_ 961 Lamp_TrnSigRtSwSta "17.12.08";
BA_ "Description" SG_ 961 Lamp_LaneChgTrnSigLftSwSta "LANE CHANGE TURN SIGNAL FOR LH";
BA_ "GenSigSendType" SG_ 961 Lamp_LaneChgTrnSigLftSwSta 4;
BA_ "UserSigValidity" SG_ 961 Lamp_LaneChgTrnSigLftSwSta 0;
BA_ "NetworkRequest" SG_ 961 Lamp_LaneChgTrnSigLftSwSta 0;
BA_ "NetworkRequestHoldingTime" SG_ 961 Lamp_LaneChgTrnSigLftSwSta 5000;
BA_ "Version" SG_ 961 Lamp_LaneChgTrnSigLftSwSta "18.01.00";
BA_ "Description" SG_ 961 Lamp_LaneChgTrnSigRtSwSta "LANE CHANGE TURN SIGNAL FOR RH";
BA_ "GenSigSendType" SG_ 961 Lamp_LaneChgTrnSigRtSwSta 4;
BA_ "UserSigValidity" SG_ 961 Lamp_LaneChgTrnSigRtSwSta 0;
BA_ "NetworkRequest" SG_ 961 Lamp_LaneChgTrnSigRtSwSta 0;
BA_ "NetworkRequestHoldingTime" SG_ 961 Lamp_LaneChgTrnSigRtSwSta 5000;
BA_ "Version" SG_ 961 Lamp_LaneChgTrnSigRtSwSta "18.01.00";
BA_ "GenMsgCycleTime" BO_ 1963 0;
BA_ "GenMsgCycleTimeFast" BO_ 1963 0;
BA_ "GenMsgNrOfRepetition" BO_ 1963 0;
BA_ "DiagResponse" BO_ 1963 1;
BA_ "GenMsgILSupport" BO_ 1963 0;
BA_ "TpMessage" BO_ 1963 1;
BA_ "TpTxIndex" BO_ 1963 156;
BA_ "Description" SG_ 1963 PSM_PSU_GST_Byte0 "TP Index : 156";
BA_ "UsrSigPurpose" SG_ 1963 PSM_PSU_GST_Byte0 4;
BA_ "UserSigValidity" SG_ 1963 PSM_PSU_GST_Byte0 0;
BA_REL_ "GenSigTimeoutTime" BU_SG_REL_ CGW_CCU SG_ 1963 PSM_PSU_GST_Byte0 0;
BA_ "NetworkRequest" SG_ 1963 PSM_PSU_GST_Byte0 0;
BA_ "NetworkRequestHoldingTime" SG_ 1963 PSM_PSU_GST_Byte0 5000;
BA_ "Version" SG_ 1963 PSM_PSU_GST_Byte0 "21.02.04";
BA_ "Description" SG_ 1963 PSM_PSU_GST_Byte2 "TP Index : 156";
BA_ "UsrSigPurpose" SG_ 1963 PSM_PSU_GST_Byte2 4;
BA_ "UserSigValidity" SG_ 1963 PSM_PSU_GST_Byte2 0;
BA_REL_ "GenSigTimeoutTime" BU_SG_REL_ CGW_CCU SG_ 1963 PSM_PSU_GST_Byte2 0;
BA_ "NetworkRequest" SG_ 1963 PSM_PSU_GST_Byte2 0;
BA_ "NetworkRequestHoldingTime" SG_ 1963 PSM_PSU_GST_Byte2 5000;
BA_ "Version" SG_ 1963 PSM_PSU_GST_Byte2 "21.02.04";
BA_ "Description" SG_ 1963 PSM_PSU_GST_Byte3 "TP Index : 156";
BA_ "UsrSigPurpose" SG_ 1963 PSM_PSU_GST_Byte3 4;
BA_ "UserSigValidity" SG_ 1963 PSM_PSU_GST_Byte3 0;
BA_REL_ "GenSigTimeoutTime" BU_SG_REL_ CGW_CCU SG_ 1963 PSM_PSU_GST_Byte3 0;
BA_ "NetworkRequest" SG_ 1963 PSM_PSU_GST_Byte3 0;
BA_ "NetworkRequestHoldingTime" SG_ 1963 PSM_PSU_GST_Byte3 5000;
BA_ "Version" SG_ 1963 PSM_PSU_GST_Byte3 "21.02.04";
BA_ "Description" SG_ 1963 PSM_PSU_GST_Byte4 "TP Index : 156";
BA_ "UsrSigPurpose" SG_ 1963 PSM_PSU_GST_Byte4 4;
BA_ "UserSigValidity" SG_ 1963 PSM_PSU_GST_Byte4 0;
BA_REL_ "GenSigTimeoutTime" BU_SG_REL_ CGW_CCU SG_ 1963 PSM_PSU_GST_Byte4 0;
BA_ "NetworkRequest" SG_ 1963 PSM_PSU_GST_Byte4 0;
BA_ "NetworkRequestHoldingTime" SG_ 1963 PSM_PSU_GST_Byte4 5000;
BA_ "Version" SG_ 1963 PSM_PSU_GST_Byte4 "21.02.04";
BA_ "Description" SG_ 1963 PSM_PSU_GST_Byte5 "TP Index : 156";
BA_ "UsrSigPurpose" SG_ 1963 PSM_PSU_GST_Byte5 4;
BA_ "UserSigValidity" SG_ 1963 PSM_PSU_GST_Byte5 0;
BA_REL_ "GenSigTimeoutTime" BU_SG_REL_ CGW_CCU SG_ 1963 PSM_PSU_GST_Byte5 0;
BA_ "NetworkRequest" SG_ 1963 PSM_PSU_GST_Byte5 0;
BA_ "NetworkRequestHoldingTime" SG_ 1963 PSM_PSU_GST_Byte5 5000;
BA_ "Version" SG_ 1963 PSM_PSU_GST_Byte5 "21.02.04";
BA_ "Description" SG_ 1963 PSM_PSU_GST_Byte6 "TP Index : 156";
BA_ "UsrSigPurpose" SG_ 1963 PSM_PSU_GST_Byte6 4;
BA_ "UserSigValidity" SG_ 1963 PSM_PSU_GST_Byte6 0;
BA_REL_ "GenSigTimeoutTime" BU_SG_REL_ CGW_CCU SG_ 1963 PSM_PSU_GST_Byte6 0;
BA_ "NetworkRequest" SG_ 1963 PSM_PSU_GST_Byte6 0;
BA_ "NetworkRequestHoldingTime" SG_ 1963 PSM_PSU_GST_Byte6 5000;
BA_ "Version" SG_ 1963 PSM_PSU_GST_Byte6 "21.02.04";
BA_ "Description" SG_ 1963 PSM_PSU_GST_Byte7 "TP Index : 156";
BA_ "UsrSigPurpose" SG_ 1963 PSM_PSU_GST_Byte7 4;
BA_ "UserSigValidity" SG_ 1963 PSM_PSU_GST_Byte7 0;
BA_REL_ "GenSigTimeoutTime" BU_SG_REL_ CGW_CCU SG_ 1963 PSM_PSU_GST_Byte7 0;
BA_ "NetworkRequest" SG_ 1963 PSM_PSU_GST_Byte7 0;
BA_ "NetworkRequestHoldingTime" SG_ 1963 PSM_PSU_GST_Byte7 5000;
BA_ "Version" SG_ 1963 PSM_PSU_GST_Byte7 "21.02.04";
BA_ "Description" SG_ 1963 PSM_PSU_GST_Byte1 "TP Index : 156";
BA_ "UsrSigPurpose" SG_ 1963 PSM_PSU_GST_Byte1 4;
BA_ "UserSigValidity" SG_ 1963 PSM_PSU_GST_Byte1 0;
BA_REL_ "GenSigTimeoutTime" BU_SG_REL_ CGW_CCU SG_ 1963 PSM_PSU_GST_Byte1 0;
BA_ "NetworkRequest" SG_ 1963 PSM_PSU_GST_Byte1 0;
BA_ "NetworkRequestHoldingTime" SG_ 1963 PSM_PSU_GST_Byte1 5000;
BA_ "Version" SG_ 1963 PSM_PSU_GST_Byte1 "21.02.04";
BA_ "GenMsgCycleTime" BO_ 1465 0;
BA_ "GenMsgCycleTimeFast" BO_ 1465 0;
BA_ "GenMsgNrOfRepetition" BO_ 1465 0;
BA_ "DiagResponse" BO_ 1465 1;
BA_ "GenMsgILSupport" BO_ 1465 0;
BA_ "TpMessage" BO_ 1465 1;
BA_ "TpTxIndex" BO_ 1465 211;
BA_ "Description" SG_ 1465 RLSAU_GST_Byte0 "TP Index : 211";
BA_ "UsrSigPurpose" SG_ 1465 RLSAU_GST_Byte0 4;
BA_ "UserSigValidity" SG_ 1465 RLSAU_GST_Byte0 0;
BA_REL_ "GenSigTimeoutTime" BU_SG_REL_ CGW_CCU SG_ 1465 RLSAU_GST_Byte0 0;
BA_ "NetworkRequest" SG_ 1465 RLSAU_GST_Byte0 0;
BA_ "NetworkRequestHoldingTime" SG_ 1465 RLSAU_GST_Byte0 5000;
BA_ "Version" SG_ 1465 RLSAU_GST_Byte0 "21.02.04";
BA_ "Description" SG_ 1465 RLSAU_GST_Byte2 "TP Index : 211";
BA_ "UsrSigPurpose" SG_ 1465 RLSAU_GST_Byte2 4;
BA_ "UserSigValidity" SG_ 1465 RLSAU_GST_Byte2 0;
BA_REL_ "GenSigTimeoutTime" BU_SG_REL_ CGW_CCU SG_ 1465 RLSAU_GST_Byte2 0;
BA_ "NetworkRequest" SG_ 1465 RLSAU_GST_Byte2 0;
BA_ "NetworkRequestHoldingTime" SG_ 1465 RLSAU_GST_Byte2 5000;
BA_ "Version" SG_ 1465 RLSAU_GST_Byte2 "21.02.04";
BA_ "Description" SG_ 1465 RLSAU_GST_Byte3 "TP Index : 211";
BA_ "UsrSigPurpose" SG_ 1465 RLSAU_GST_Byte3 4;
BA_ "UserSigValidity" SG_ 1465 RLSAU_GST_Byte3 0;
BA_REL_ "GenSigTimeoutTime" BU_SG_REL_ CGW_CCU SG_ 1465 RLSAU_GST_Byte3 0;
BA_ "NetworkRequest" SG_ 1465 RLSAU_GST_Byte3 0;
BA_ "NetworkRequestHoldingTime" SG_ 1465 RLSAU_GST_Byte3 5000;
BA_ "Version" SG_ 1465 RLSAU_GST_Byte3 "21.02.04";
BA_ "Description" SG_ 1465 RLSAU_GST_Byte4 "TP Index : 211";
BA_ "UsrSigPurpose" SG_ 1465 RLSAU_GST_Byte4 4;
BA_ "UserSigValidity" SG_ 1465 RLSAU_GST_Byte4 0;
BA_REL_ "GenSigTimeoutTime" BU_SG_REL_ CGW_CCU SG_ 1465 RLSAU_GST_Byte4 0;
BA_ "NetworkRequest" SG_ 1465 RLSAU_GST_Byte4 0;
BA_ "NetworkRequestHoldingTime" SG_ 1465 RLSAU_GST_Byte4 5000;
BA_ "Version" SG_ 1465 RLSAU_GST_Byte4 "21.02.04";
BA_ "Description" SG_ 1465 RLSAU_GST_Byte5 "TP Index : 211";
BA_ "UsrSigPurpose" SG_ 1465 RLSAU_GST_Byte5 4;
BA_ "UserSigValidity" SG_ 1465 RLSAU_GST_Byte5 0;
BA_REL_ "GenSigTimeoutTime" BU_SG_REL_ CGW_CCU SG_ 1465 RLSAU_GST_Byte5 0;
BA_ "NetworkRequest" SG_ 1465 RLSAU_GST_Byte5 0;
BA_ "NetworkRequestHoldingTime" SG_ 1465 RLSAU_GST_Byte5 5000;
BA_ "Version" SG_ 1465 RLSAU_GST_Byte5 "21.02.04";
BA_ "Description" SG_ 1465 RLSAU_GST_Byte6 "TP Index : 211";
BA_ "UsrSigPurpose" SG_ 1465 RLSAU_GST_Byte6 4;
BA_ "UserSigValidity" SG_ 1465 RLSAU_GST_Byte6 0;
BA_REL_ "GenSigTimeoutTime" BU_SG_REL_ CGW_CCU SG_ 1465 RLSAU_GST_Byte6 0;
BA_ "NetworkRequest" SG_ 1465 RLSAU_GST_Byte6 0;
BA_ "NetworkRequestHoldingTime" SG_ 1465 RLSAU_GST_Byte6 5000;
BA_ "Version" SG_ 1465 RLSAU_GST_Byte6 "21.02.04";
BA_ "Description" SG_ 1465 RLSAU_GST_Byte7 "TP Index : 211";
BA_ "UsrSigPurpose" SG_ 1465 RLSAU_GST_Byte7 4;
BA_ "UserSigValidity" SG_ 1465 RLSAU_GST_Byte7 0;
BA_REL_ "GenSigTimeoutTime" BU_SG_REL_ CGW_CCU SG_ 1465 RLSAU_GST_Byte7 0;
BA_ "NetworkRequest" SG_ 1465 RLSAU_GST_Byte7 0;
BA_ "NetworkRequestHoldingTime" SG_ 1465 RLSAU_GST_Byte7 5000;
BA_ "Version" SG_ 1465 RLSAU_GST_Byte7 "21.02.04";
BA_ "Description" SG_ 1465 RLSAU_GST_Byte1 "TP Index : 211";
BA_ "UsrSigPurpose" SG_ 1465 RLSAU_GST_Byte1 4;
BA_ "UserSigValidity" SG_ 1465 RLSAU_GST_Byte1 0;
BA_REL_ "GenSigTimeoutTime" BU_SG_REL_ CGW_CCU SG_ 1465 RLSAU_GST_Byte1 0;
BA_ "NetworkRequest" SG_ 1465 RLSAU_GST_Byte1 0;
BA_ "NetworkRequestHoldingTime" SG_ 1465 RLSAU_GST_Byte1 5000;
BA_ "Version" SG_ 1465 RLSAU_GST_Byte1 "21.02.04";
BA_ "GenMsgCycleTime" BO_ 1464 0;
BA_ "GenMsgCycleTimeFast" BO_ 1464 0;
BA_ "GenMsgNrOfRepetition" BO_ 1464 0;
BA_ "DiagResponse" BO_ 1464 1;
BA_ "GenMsgILSupport" BO_ 1464 0;
BA_ "TpMessage" BO_ 1464 1;
BA_ "TpTxIndex" BO_ 1464 210;
BA_ "Description" SG_ 1464 RRSAU_GST_Byte0 "TP Index : 210";
BA_ "UsrSigPurpose" SG_ 1464 RRSAU_GST_Byte0 4;
BA_ "UserSigValidity" SG_ 1464 RRSAU_GST_Byte0 0;
BA_REL_ "GenSigTimeoutTime" BU_SG_REL_ CGW_CCU SG_ 1464 RRSAU_GST_Byte0 0;
BA_ "NetworkRequest" SG_ 1464 RRSAU_GST_Byte0 0;
BA_ "NetworkRequestHoldingTime" SG_ 1464 RRSAU_GST_Byte0 5000;
BA_ "Version" SG_ 1464 RRSAU_GST_Byte0 "21.02.04";
BA_ "Description" SG_ 1464 RRSAU_GST_Byte2 "TP Index : 210";
BA_ "UsrSigPurpose" SG_ 1464 RRSAU_GST_Byte2 4;
BA_ "UserSigValidity" SG_ 1464 RRSAU_GST_Byte2 0;
BA_REL_ "GenSigTimeoutTime" BU_SG_REL_ CGW_CCU SG_ 1464 RRSAU_GST_Byte2 0;
BA_ "NetworkRequest" SG_ 1464 RRSAU_GST_Byte2 0;
BA_ "NetworkRequestHoldingTime" SG_ 1464 RRSAU_GST_Byte2 5000;
BA_ "Version" SG_ 1464 RRSAU_GST_Byte2 "21.02.04";
BA_ "Description" SG_ 1464 RRSAU_GST_Byte3 "TP Index : 210";
BA_ "UsrSigPurpose" SG_ 1464 RRSAU_GST_Byte3 4;
BA_ "UserSigValidity" SG_ 1464 RRSAU_GST_Byte3 0;
BA_REL_ "GenSigTimeoutTime" BU_SG_REL_ CGW_CCU SG_ 1464 RRSAU_GST_Byte3 0;
BA_ "NetworkRequest" SG_ 1464 RRSAU_GST_Byte3 0;
BA_ "NetworkRequestHoldingTime" SG_ 1464 RRSAU_GST_Byte3 5000;
BA_ "Version" SG_ 1464 RRSAU_GST_Byte3 "21.02.04";
BA_ "Description" SG_ 1464 RRSAU_GST_Byte4 "TP Index : 210";
BA_ "UsrSigPurpose" SG_ 1464 RRSAU_GST_Byte4 4;
BA_ "UserSigValidity" SG_ 1464 RRSAU_GST_Byte4 0;
BA_REL_ "GenSigTimeoutTime" BU_SG_REL_ CGW_CCU SG_ 1464 RRSAU_GST_Byte4 0;
BA_ "NetworkRequest" SG_ 1464 RRSAU_GST_Byte4 0;
BA_ "NetworkRequestHoldingTime" SG_ 1464 RRSAU_GST_Byte4 5000;
BA_ "Version" SG_ 1464 RRSAU_GST_Byte4 "21.02.04";
BA_ "Description" SG_ 1464 RRSAU_GST_Byte5 "TP Index : 210";
BA_ "UsrSigPurpose" SG_ 1464 RRSAU_GST_Byte5 4;
BA_ "UserSigValidity" SG_ 1464 RRSAU_GST_Byte5 0;
BA_REL_ "GenSigTimeoutTime" BU_SG_REL_ CGW_CCU SG_ 1464 RRSAU_GST_Byte5 0;
BA_ "NetworkRequest" SG_ 1464 RRSAU_GST_Byte5 0;
BA_ "NetworkRequestHoldingTime" SG_ 1464 RRSAU_GST_Byte5 5000;
BA_ "Version" SG_ 1464 RRSAU_GST_Byte5 "21.02.04";
BA_ "Description" SG_ 1464 RRSAU_GST_Byte6 "TP Index : 210";
BA_ "UsrSigPurpose" SG_ 1464 RRSAU_GST_Byte6 4;
BA_ "UserSigValidity" SG_ 1464 RRSAU_GST_Byte6 0;
BA_REL_ "GenSigTimeoutTime" BU_SG_REL_ CGW_CCU SG_ 1464 RRSAU_GST_Byte6 0;
BA_ "NetworkRequest" SG_ 1464 RRSAU_GST_Byte6 0;
BA_ "NetworkRequestHoldingTime" SG_ 1464 RRSAU_GST_Byte6 5000;
BA_ "Version" SG_ 1464 RRSAU_GST_Byte6 "21.02.04";
BA_ "Description" SG_ 1464 RRSAU_GST_Byte7 "TP Index : 210";
BA_ "UsrSigPurpose" SG_ 1464 RRSAU_GST_Byte7 4;
BA_ "UserSigValidity" SG_ 1464 RRSAU_GST_Byte7 0;
BA_REL_ "GenSigTimeoutTime" BU_SG_REL_ CGW_CCU SG_ 1464 RRSAU_GST_Byte7 0;
BA_ "NetworkRequest" SG_ 1464 RRSAU_GST_Byte7 0;
BA_ "NetworkRequestHoldingTime" SG_ 1464 RRSAU_GST_Byte7 5000;
BA_ "Version" SG_ 1464 RRSAU_GST_Byte7 "21.02.04";
BA_ "Description" SG_ 1464 RRSAU_GST_Byte1 "TP Index : 210";
BA_ "UsrSigPurpose" SG_ 1464 RRSAU_GST_Byte1 4;
BA_ "UserSigValidity" SG_ 1464 RRSAU_GST_Byte1 0;
BA_REL_ "GenSigTimeoutTime" BU_SG_REL_ CGW_CCU SG_ 1464 RRSAU_GST_Byte1 0;
BA_ "NetworkRequest" SG_ 1464 RRSAU_GST_Byte1 0;
BA_ "NetworkRequestHoldingTime" SG_ 1464 RRSAU_GST_Byte1 5000;
BA_ "Version" SG_ 1464 RRSAU_GST_Byte1 "21.02.04";
BA_ "NmMessage" BO_ 1369 1;
BA_ "GenMsgILSupport" BO_ 1369 0;
BA_ "NWM-Botschaft" BO_ 1369 1;
BA_ "UsrSigPurpose" SG_ 1369 Destination_DSAU 9;
BA_ "UserSigValidity" SG_ 1369 Destination_DSAU 0;
BA_ "UsrSigPurpose" SG_ 1369 NMCommandCode_DSAU 9;
BA_ "UserSigValidity" SG_ 1369 NMCommandCode_DSAU 0;
BA_ "UsrSigPurpose" SG_ 1369 NMSleepFlag_DSAU 9;
BA_ "UserSigValidity" SG_ 1369 NMSleepFlag_DSAU 0;
BA_ "NmMessage" BO_ 1323 1;
BA_ "GenMsgILSupport" BO_ 1323 0;
BA_ "NWM-Botschaft" BO_ 1323 1;
BA_ "UsrSigPurpose" SG_ 1323 Destination_SHVU_RR 9;
BA_ "UserSigValidity" SG_ 1323 Destination_SHVU_RR 0;
BA_ "UsrSigPurpose" SG_ 1323 NMCommandCode_SHVU_RR 9;
BA_ "UserSigValidity" SG_ 1323 NMCommandCode_SHVU_RR 0;
BA_ "UsrSigPurpose" SG_ 1323 NMSleepFlag_SHVU_RR 9;
BA_ "UserSigValidity" SG_ 1323 NMSleepFlag_SHVU_RR 0;
BA_ "NmMessage" BO_ 1337 1;
BA_ "GenMsgILSupport" BO_ 1337 0;
BA_ "NWM-Botschaft" BO_ 1337 1;
BA_ "UsrSigPurpose" SG_ 1337 Destination_DPSS 9;
BA_ "UserSigValidity" SG_ 1337 Destination_DPSS 0;
BA_ "UsrSigPurpose" SG_ 1337 NMCommandCode_DPSS 9;
BA_ "UserSigValidity" SG_ 1337 NMCommandCode_DPSS 0;
BA_ "UsrSigPurpose" SG_ 1337 NMSleepFlag_DPSS 9;
BA_ "UserSigValidity" SG_ 1337 NMSleepFlag_DPSS 0;
BA_ "NmMessage" BO_ 1376 1;
BA_ "GenMsgILSupport" BO_ 1376 0;
BA_ "NWM-Botschaft" BO_ 1376 1;
BA_ "UsrSigPurpose" SG_ 1376 Destination_AMP 9;
BA_ "UserSigValidity" SG_ 1376 Destination_AMP 0;
BA_ "UsrSigPurpose" SG_ 1376 NMCommandCode_AMP 9;
BA_ "UserSigValidity" SG_ 1376 NMCommandCode_AMP 0;
BA_ "UsrSigPurpose" SG_ 1376 NMSleepFlag_AMP 9;
BA_ "UserSigValidity" SG_ 1376 NMSleepFlag_AMP 0;
BA_ "NmMessage" BO_ 1367 1;
BA_ "GenMsgILSupport" BO_ 1367 0;
BA_ "NWM-Botschaft" BO_ 1367 1;
BA_ "UsrSigPurpose" SG_ 1367 Destination_ICC 9;
BA_ "UserSigValidity" SG_ 1367 Destination_ICC 0;
BA_ "UsrSigPurpose" SG_ 1367 NMCommandCode_ICC 9;
BA_ "UserSigValidity" SG_ 1367 NMCommandCode_ICC 0;
BA_ "UsrSigPurpose" SG_ 1367 NMSleepFlag_ICC 9;
BA_ "UserSigValidity" SG_ 1367 NMSleepFlag_ICC 0;
BA_ "NmMessage" BO_ 1308 1;
BA_ "GenMsgILSupport" BO_ 1308 0;
BA_ "NWM-Botschaft" BO_ 1308 1;
BA_ "UsrSigPurpose" SG_ 1308 Destination_RLPSM 9;
BA_ "UserSigValidity" SG_ 1308 Destination_RLPSM 0;
BA_ "UsrSigPurpose" SG_ 1308 NMCommandCode_RLPSM 9;
BA_ "UserSigValidity" SG_ 1308 NMCommandCode_RLPSM 0;
BA_ "UsrSigPurpose" SG_ 1308 NMSleepFlag_RLPSM 9;
BA_ "UserSigValidity" SG_ 1308 NMSleepFlag_RLPSM 0;
BA_ "NmMessage" BO_ 1289 1;
BA_ "GenMsgILSupport" BO_ 1289 0;
BA_ "NWM-Botschaft" BO_ 1289 1;
BA_ "UsrSigPurpose" SG_ 1289 Destination_APSM 9;
BA_ "UserSigValidity" SG_ 1289 Destination_APSM 0;
BA_ "UsrSigPurpose" SG_ 1289 NMCommandCode_APSM 9;
BA_ "UserSigValidity" SG_ 1289 NMCommandCode_APSM 0;
BA_ "UsrSigPurpose" SG_ 1289 NMSleepFlag_APSM 9;
BA_ "UserSigValidity" SG_ 1289 NMSleepFlag_APSM 0;
BA_ "NmMessage" BO_ 1311 1;
BA_ "GenMsgILSupport" BO_ 1311 0;
BA_ "NWM-Botschaft" BO_ 1311 1;
BA_ "UsrSigPurpose" SG_ 1311 Destination_RWPC 9;
BA_ "UserSigValidity" SG_ 1311 Destination_RWPC 0;
BA_ "UsrSigPurpose" SG_ 1311 NMCommandCode_RWPC 9;
BA_ "UserSigValidity" SG_ 1311 NMCommandCode_RWPC 0;
BA_ "UsrSigPurpose" SG_ 1311 NMSleepFlag_RWPC 9;
BA_ "UserSigValidity" SG_ 1311 NMSleepFlag_RWPC 0;
BA_ "NmMessage" BO_ 1333 1;
BA_ "GenMsgILSupport" BO_ 1333 0;
BA_ "NWM-Botschaft" BO_ 1333 1;
BA_ "UsrSigPurpose" SG_ 1333 Destination_RRHV 9;
BA_ "UserSigValidity" SG_ 1333 Destination_RRHV 0;
BA_ "UsrSigPurpose" SG_ 1333 NMCommandCode_RRHV 9;
BA_ "UserSigValidity" SG_ 1333 NMCommandCode_RRHV 0;
BA_ "UsrSigPurpose" SG_ 1333 NMSleepFlag_RRHV 9;
BA_ "UserSigValidity" SG_ 1333 NMSleepFlag_RRHV 0;
BA_ "NmMessage" BO_ 1309 1;
BA_ "GenMsgILSupport" BO_ 1309 0;
BA_ "NWM-Botschaft" BO_ 1309 1;
BA_ "UsrSigPurpose" SG_ 1309 Destination_RRPSM 9;
BA_ "UserSigValidity" SG_ 1309 Destination_RRPSM 0;
BA_ "UsrSigPurpose" SG_ 1309 NMCommandCode_RRPSM 9;
BA_ "UserSigValidity" SG_ 1309 NMCommandCode_RRPSM 0;
BA_ "UsrSigPurpose" SG_ 1309 NMSleepFlag_RRPSM 9;
BA_ "UserSigValidity" SG_ 1309 NMSleepFlag_RRPSM 0;
BA_ "NmMessage" BO_ 1392 1;
BA_ "GenMsgILSupport" BO_ 1392 0;
BA_ "NWM-Botschaft" BO_ 1392 1;
BA_ "UsrSigPurpose" SG_ 1392 Destination_CGW_CCU 9;
BA_ "UserSigValidity" SG_ 1392 Destination_CGW_CCU 0;
BA_ "UsrSigPurpose" SG_ 1392 NMCommandCode_CGW_CCU 9;
BA_ "UserSigValidity" SG_ 1392 NMCommandCode_CGW_CCU 0;
BA_ "UsrSigPurpose" SG_ 1392 NMSleepFlag_CGW_CCU 9;
BA_ "UserSigValidity" SG_ 1392 NMSleepFlag_CGW_CCU 0;
BA_ "NmMessage" BO_ 1346 1;
BA_ "GenMsgILSupport" BO_ 1346 0;
BA_ "NWM-Botschaft" BO_ 1346 1;
BA_ "UsrSigPurpose" SG_ 1346 Destination_APSS 9;
BA_ "UserSigValidity" SG_ 1346 Destination_APSS 0;
BA_ "UsrSigPurpose" SG_ 1346 NMCommandCode_APSS 9;
BA_ "UserSigValidity" SG_ 1346 NMCommandCode_APSS 0;
BA_ "UsrSigPurpose" SG_ 1346 NMSleepFlag_APSS 9;
BA_ "UserSigValidity" SG_ 1346 NMSleepFlag_APSS 0;
BA_ "NmMessage" BO_ 1360 1;
BA_ "GenMsgILSupport" BO_ 1360 0;
BA_ "NWM-Botschaft" BO_ 1360 1;
BA_ "UsrSigPurpose" SG_ 1360 Destination_ATS 9;
BA_ "UserSigValidity" SG_ 1360 Destination_ATS 0;
BA_ "UsrSigPurpose" SG_ 1360 NMCommandCode_ATS 9;
BA_ "UserSigValidity" SG_ 1360 NMCommandCode_ATS 0;
BA_ "UsrSigPurpose" SG_ 1360 NMSleepFlag_ATS 9;
BA_ "UserSigValidity" SG_ 1360 NMSleepFlag_ATS 0;
BA_ "NmMessage" BO_ 1332 1;
BA_ "GenMsgILSupport" BO_ 1332 0;
BA_ "NWM-Botschaft" BO_ 1332 1;
BA_ "UsrSigPurpose" SG_ 1332 Destination_RLHV 9;
BA_ "UserSigValidity" SG_ 1332 Destination_RLHV 0;
BA_ "UsrSigPurpose" SG_ 1332 NMCommandCode_RLHV 9;
BA_ "UserSigValidity" SG_ 1332 NMCommandCode_RLHV 0;
BA_ "UsrSigPurpose" SG_ 1332 NMSleepFlag_RLHV 9;
BA_ "UserSigValidity" SG_ 1332 NMSleepFlag_RLHV 0;
BA_ "NmMessage" BO_ 1359 1;
BA_ "GenMsgILSupport" BO_ 1359 0;
BA_ "NWM-Botschaft" BO_ 1359 1;
BA_ "UsrSigPurpose" SG_ 1359 Destination_FPM 9;
BA_ "UserSigValidity" SG_ 1359 Destination_FPM 0;
BA_ "UsrSigPurpose" SG_ 1359 NMCommandCode_FPM 9;
BA_ "UserSigValidity" SG_ 1359 NMCommandCode_FPM 0;
BA_ "UsrSigPurpose" SG_ 1359 NMSleepFlag_FPM 9;
BA_ "UserSigValidity" SG_ 1359 NMSleepFlag_FPM 0;
BA_ "NmMessage" BO_ 1327 1;
BA_ "GenMsgILSupport" BO_ 1327 0;
BA_ "NWM-Botschaft" BO_ 1327 1;
BA_ "UsrSigPurpose" SG_ 1327 Destination_RDC 9;
BA_ "UserSigValidity" SG_ 1327 Destination_RDC 0;
BA_ "UsrSigPurpose" SG_ 1327 NMCommandCode_RDC 9;
BA_ "UserSigValidity" SG_ 1327 NMCommandCode_RDC 0;
BA_ "UsrSigPurpose" SG_ 1327 NMSleepFlag_RDC 9;
BA_ "UserSigValidity" SG_ 1327 NMSleepFlag_RDC 0;
BA_ "NmMessage" BO_ 1286 1;
BA_ "GenMsgILSupport" BO_ 1286 0;
BA_ "NWM-Botschaft" BO_ 1286 1;
BA_ "UsrSigPurpose" SG_ 1286 Destination_PSM 9;
BA_ "UserSigValidity" SG_ 1286 Destination_PSM 0;
BA_ "UsrSigPurpose" SG_ 1286 NMCommandCode_PSM 9;
BA_ "UserSigValidity" SG_ 1286 NMCommandCode_PSM 0;
BA_ "UsrSigPurpose" SG_ 1286 NMSleepFlag_PSM 9;
BA_ "UserSigValidity" SG_ 1286 NMSleepFlag_PSM 0;
BA_ "NmMessage" BO_ 1363 1;
BA_ "GenMsgILSupport" BO_ 1363 0;
BA_ "NWM-Botschaft" BO_ 1363 1;
BA_ "UsrSigPurpose" SG_ 1363 Destination_ASAU 9;
BA_ "UserSigValidity" SG_ 1363 Destination_ASAU 0;
BA_ "UsrSigPurpose" SG_ 1363 NMCommandCode_ASAU 9;
BA_ "UserSigValidity" SG_ 1363 NMCommandCode_ASAU 0;
BA_ "UsrSigPurpose" SG_ 1363 NMSleepFlag_ASAU 9;
BA_ "UserSigValidity" SG_ 1363 NMSleepFlag_ASAU 0;
VAL_ 2151682049 ACU_CrshActvSta 0 "Crash Active time is expired (Crash is Inactive)" 1 "Crash Active time started (Crash Detected)" 2 "Not used" 3 "Error Indicator" ;
VAL_ 2151682049 ACU_CrshInfo 0 "Received ESC feedback signal" 1 "Crash output signal not issued" 2 "Crash output signal issued" ;
VAL_ 2256642049 SCC_ObjDstVal 1501 "0x0x5DD~0x7FD:Reserved" 2045 "0x0x5DD~0x7FD:Reserved" 2046 "Default" 2047 "Error" ;
VAL_ 2256642049 SCC_ObjRelSpdVal 4094 "Default" 4095 "Error" ;
VAL_ 2256642049 SCC_ObjLatPosVal 510 "Default" 511 "Error" ;
VAL_ 2256642050 SCC_SysFlrSta 0 "System without error" 1 "Performance degredation" 2 "System temporairy unavailable" 3 "SCC Service Required" ;
VAL_ 2256642050 SCC_InfoDis 0 "-" 1 "Display “SCC Mode”" 2 "Display “Conventional Cruise Mode”" 3 "Display “Object disappeared at low speed”" 4 "Display “Available to resume acceleration control”" 5 "Reserved" 6 "Reserved" 7 "Invalid" ;
VAL_ 2256642050 SCC_DrvAlrtDis 0 "-" 1 "Display 'SCC Disengaged'" 2 "Display 'No SCC Engage Condition!'" 3 "Display 'Driving Speed Limited'" ;
VAL_ 2256642050 SCC_MainOnOffSta 0 "OFF" 1 "ON" 2 "Not used" 3 "Error Indicator" ;
VAL_ 2256642050 SCC_HeadwayDstSetVal 0 "No time gap set" 1 "1st level distance" 2 "2nd level distance" 3 "3rd level distance" 4 "4th level distance" 5 "Reserved" 6 "1st level distance (SCC-ML)" 7 "2nd level distance (SCC-ML)" 8 "3rd level distance (SCC-ML)" 9 "4th level distance (SCC-ML)" 10 "Reserved" 11 "Reserved" 12 "Reserved" 13 "Reserved" 14 "SCC-ML Active" 15 "Error Indicator" ;
VAL_ 2256642050 SCC_NSCCAutoSetSpdSta 0 "Auto Set Speed Off" 1 "Auto Set Speed On" 2 "Reserved" 3 "Error Indicator" ;
VAL_ 2256642050 SCC_TrgtSpdSetVal 255 "Error" ;
VAL_ 2256642050 SCC_OpSta 0 "Off" 1 "Engaged" 2 "Override" 3 "Shutoff" 4 "Canceled or Paused" 5 "Reserved" 6 "Reserved" 7 "Reserved" ;
VAL_ 2256642050 SCC_NSCCOpSta 0 "Off" 1 "Ready" 2 "Act" 3 "Error Indicator" ;
VAL_ 2256642050 SCC_NSCCOnOffSta 0 "Default" 1 "Off" 2 "On" 3 "Invalid" ;
VAL_ 2256642050 SCC_ObjSta 0 "No in-path object detected" 1 "In-path object detected (uncontrollable)" 2 "In-path object detected (controllable:longitudinal)" 3 "Reserved" 4 "Reserved" 5 "Reserved" 6 "Reserved" 7 "Reserved" ;
VAL_ 2256642050 SCC_NSCCAutoSetSpdUpdtSta 0 "Auto Set Speed Update Off" 1 "Auto Set Speed Update On" 2 "Reserved" 3 "Error Indicator" ;
VAL_ 2256642050 SCC_NSCCInfoPUDis 0 "None" 1 "NSCC Warning" 2 "Reserved" 3 "Reserved" 4 "Reserved" 5 "Reserved" 6 "Reserved" 7 "Reserved" ;
VAL_ 2256642050 SCC_TakeoverReq 0 "No takeover request" 1 "Takeover request" 2 "Not used" 3 "Error Indicator" ;
VAL_ 2256642051 SCC_AccelReqVal 2047 "Error" ;
VAL_ 2256642051 SCC_AccelReqRawVal 2047 "Error" ;
VAL_ 2256642051 SCC_JrkUppLimVal 127 "No Limit" ;
VAL_ 2256642051 SCC_JrkLwrLimVal 127 "No Limit" ;
VAL_ 2256642051 SCC_AccelLimBandUppVal 0 "Precise Control" ;
VAL_ 2256642051 SCC_AccelLimBandLwrVal 0 "Precise Control" ;
VAL_ 2256642051 SCC_VehStpReq 0 "No request" 1 "Stop control is required" 2 "Not used" 3 "Error Indicator" ;
VAL_ 2256642051 SCC_EngStateReq 0 "SCC deactive or SCC off" 1 "'ISG Stop' Possible" 2 "'ISG Start or Maintain Engine Run' Request" 3 "Reserved" ;
VAL_ 2256642052 SCC_TrgtDstVal 1501 "0x0x5DD~0x7FD:Reserved" 2045 "0x0x5DD~0x7FD:Reserved" 2046 "Default" 2047 "Error" ;
VAL_ 2256642052 HDP_LongActvSta 0 "Not Active" 1 "HDP Control Active" 2 "Reserved" 3 "Reserved" ;
VAL_ 2256642052 HDP_MRMCtrlSta 0 "MRM Not Active" 1 "MRM Control Active" 2 "MRM Redundancy Active" 3 "Reserved" ;
VAL_ 2256642052 HDP_ESCOnReq 0 "No Request" 1 "ESC On Request" 2 "Reserved" 3 "Reserved" ;
VAL_ 2256642052 HDP_AccelOvrdLmt 0 "Not Limited" 1 "Acceleration Override Limited" 2 "Reserved" 3 "Reserved" ;
VAL_ 981 APSS_StSldFwdMvBtn 0 "Default" 1 "Off" 2 "On" 3 "Invalid" ;
VAL_ 981 APSS_StSldBwdMvBtn 0 "Default" 1 "Off" 2 "On" 3 "Invalid" ;
VAL_ 981 APSS_StRclFwdMvBtn 0 "Default" 1 "Off" 2 "On" 3 "Invalid" ;
VAL_ 981 APSS_StRclBwdMvBtn 0 "Default" 1 "Off" 2 "On" 3 "Invalid" ;
VAL_ 981 APSS_StHgtUpMvBtn 0 "Default" 1 "Off" 2 "On" 3 "Invalid" ;
VAL_ 981 APSS_StHgtDnMvBtn 0 "Default" 1 "Off" 2 "On" 3 "Invalid" ;
VAL_ 981 APSS_StTltUpMvBtn 0 "Default" 1 "Off" 2 "On" 3 "Invalid" ;
VAL_ 981 APSS_StTltDnMvBtn 0 "Default" 1 "Off" 2 "On" 3 "Invalid" ;
VAL_ 981 APSS_StHRestUpMvBtn 0 "Default" 1 "Off" 2 "On" 3 "Invalid" ;
VAL_ 981 APSS_StHRestDnMvBtn 0 "Default" 1 "Off" 2 "On" 3 "Invalid" ;
VAL_ 981 APSS_StHRestFwdMvBtn 0 "Default" 1 "Off" 2 "On" 3 "Invalid" ;
VAL_ 981 APSS_StHRestBwdMvBtn 0 "Default" 1 "Off" 2 "On" 3 "Invalid" ;
VAL_ 981 APSS_StLegUpMvBtn 0 "Default" 1 "Off" 2 "On" 3 "Invalid" ;
VAL_ 981 APSS_StLegDnMvBtn 0 "Default" 1 "Off" 2 "On" 3 "Invalid" ;
VAL_ 981 APSS_StRlxModeBtn 0 "Default" 1 "Off" 2 "On" 3 "Invalid" ;
VAL_ 981 APSS_StRlxReturnBtn 0 "Default" 1 "Off" 2 "On" 3 "Invalid" ;
VAL_ 981 APSS_StRlxTltUpMvBtn 0 "Default" 1 "Off" 2 "On" 3 "Invalid" ;
VAL_ 981 APSS_StRlxTltDnMvBtn 0 "Default" 1 "Off" 2 "On" 3 "Invalid" ;
VAL_ 997 PDW_OptTyp 0 "Non" 1 "PDW R" 2 "PDW FR" 3 "Reserved" 4 "PDW-R (w/ 1st Corner Warning)" 5 "PDW-FR (w/ 1st Corner Warning)" 6 "Not Used" 7 "Error Indicator" ;
VAL_ 997 PDW_SysChkSndSta 0 "Off" 1 "R_Confirm" 2 "Error" 3 "Reserved" 4 "Reserved" 5 "Reseved" 6 "Not Used" 7 "Error Indicator" ;
VAL_ 997 PDW_SwIndOnReq 0 "Indicator Off" 1 "Indicator On" 2 "Not Used" 3 "Error Indicator" ;
VAL_ 997 PDW_SysOnSta 0 "Off" 1 "On" 2 "Reserved" 3 "Reserved" 4 "Reserved" 5 "Reseved" 6 "Not Used" 7 "Error Indicator" ;
VAL_ 997 PDW_FrCtWrngLvlDis 0 "Off" 1 "1st warning" 2 "2nd warning" 3 "3rd warning" 4 "Error" 5 "Reseved" 6 "Not Used" 7 "Error Indicator" ;
VAL_ 997 PDW_SysFlrSta 0 "No Display" 1 "Unable by Ultrasonic" 2 "PDW Failure" 3 "Error Indicator" ;
VAL_ 997 PDW_FrCtWrngSndSta 0 "Off" 1 "1st warning" 2 "2nd warning" 3 "3rd warning" 4 "Reserved" 5 "Reseved" 6 "Not Used" 7 "Error Indicator" ;
VAL_ 997 PDW_FrLtWrngLvlDis 0 "Off" 1 "1st warning" 2 "2nd warning" 3 "3rd warning" 4 "Error" 5 "Reseved" 6 "Not Used" 7 "Error Indicator" ;
VAL_ 997 PDW_FrLtWrngSndSta 0 "Off" 1 "1st warning" 2 "2nd warning" 3 "3rd warning" 4 "Reserved" 5 "Reseved" 6 "Not Used" 7 "Error Indicator" ;
VAL_ 997 PDW_FrRtWrngLvlDis 0 "Off" 1 "1st warning" 2 "2nd warning" 3 "3rd warning" 4 "Error" 5 "Reseved" 6 "Not Used" 7 "Error Indicator" ;
VAL_ 997 PDW_FrRtWrngSndSta 0 "Off" 1 "1st warning" 2 "2nd warning" 3 "3rd warning" 4 "Reserved" 5 "Reseved" 6 "Not Used" 7 "Error Indicator" ;
VAL_ 997 PDW_FrSnsrWrngLvlSta 0 "Off" 1 "1st Waring" 2 "2nd Waring" 3 "3rd Warning" 4 "Reserved" 5 "Reseved" 6 "Not Used" 7 "Error Indicator" ;
VAL_ 998 PDW_RrCtWrngLvlDis 0 "Off" 1 "1st warning" 2 "2nd warning" 3 "3rd warning" 4 "Error" 5 "Reseved" 6 "Not Used" 7 "Error Indicator" ;
VAL_ 998 PDW_RrCtWrngSndSta 0 "Off" 1 "1st warning" 2 "2nd warning" 3 "3rd warning" 4 "Reserved" 5 "Reseved" 6 "Not Used" 7 "Error Indicator" ;
VAL_ 998 PDW_RrLtWrngLvlDis 0 "Off" 1 "1st warning" 2 "2nd warning" 3 "3rd warning" 4 "Error" 5 "Reseved" 6 "Not Used" 7 "Error Indicator" ;
VAL_ 998 PDW_RrLtWrngSndSta 0 "Off" 1 "1st warning" 2 "2nd warning" 3 "3rd warning" 4 "Reserved" 5 "Reseved" 6 "Not Used" 7 "Error Indicator" ;
VAL_ 998 PDW_RrRtWrngLvlDis 0 "Off" 1 "1st warning" 2 "2nd warning" 3 "3rd warning" 4 "Error" 5 "Reseved" 6 "Not Used" 7 "Error Indicator" ;
VAL_ 998 PDW_RrRtWrngSndSta 0 "Off" 1 "1st warning" 2 "2nd warning" 3 "3rd warning" 4 "Reserved" 5 "Reseved" 6 "Not Used" 7 "Error Indicator" ;
VAL_ 998 PDW_RrSnsrWrngLvlSta 0 "Off" 1 "1st Waring" 2 "2nd Waring" 3 "3rd Warning" 4 "Reserved" 5 "Reseved" 6 "Not Used" 7 "Error Indicator" ;
VAL_ 963 IBU_SWVerMajor1 0 "0x0x0~0x7F:ASCII Code Value (HEX)" 127 "0x0x0~0x7F:ASCII Code Value (HEX)" ;
VAL_ 963 IBU_SWVerMinor1 0 "0x0x0~0x7F:ASCII Code Value (HEX)" 127 "0x0x0~0x7F:ASCII Code Value (HEX)" ;
VAL_ 963 IBU_SWVerMinor2 0 "0x0x0~0x7F:ASCII Code Value (HEX)" 127 "0x0x0~0x7F:ASCII Code Value (HEX)" ;
VAL_ 963 ECW_Fault 0 "Else" 1 "Detected" 2 "Not used" 3 "Error Indicator" ;
VAL_ 963 ECW_FaultActv 0 "Else" 1 "Valid" 2 "Not used" 3 "Error Indicator" ;
VAL_ 963 ECW_HiVolt 0 "Else" 1 "Detected" 2 "Not used" 3 "Error Indicator" ;
VAL_ 963 ECW_HiVoltActv 0 "Else" 1 "Valid" 2 "Not used" 3 "Error Indicator" ;
VAL_ 963 ECW_LoVolt 0 "Else" 1 "Detected" 2 "Not used" 3 "Error Indicator" ;
VAL_ 963 ECW_LoVoltActv 0 "Else" 1 "Valid" 2 "Not used" 3 "Error Indicator" ;
VAL_ 963 ECW_Overload 0 "Else" 1 "Detected" 2 "Not used" 3 "Error Indicator" ;
VAL_ 963 ECW_OverloadActv 0 "Else" 1 "Valid" 2 "Not used" 3 "Error Indicator" ;
VAL_ 963 ECW_CommErr 0 "No error" 1 "Error" 2 "Not used" 3 "Error Indicator" ;
VAL_ 963 SunRoof_RearBlindOprSta 0 "No Action" 1 "FullOpen" 2 "FullClose" 3 "PartiallyOpen" 4 "Opening" 5 "Closing" 6 "Reserved" 7 "Reserved" 8 "Reserved" 9 "Reserved" 10 "Reserved" 11 "Reserved" 12 "Reserved" 13 "Reserved" 14 "Reserved" 15 "Invalid" ;
VAL_ 2445570561 USM_CluAdasVolSta 0 "Default" 1 "Level1" 2 "Level2" 3 "Level3" 4 "Reserved" 5 "Reserved" 6 "OFF" 7 "Invalid" ;
VAL_ 2445570561 Wrn_Snd_AdasVolFdbck 0 "Default" 1 "level 1" 2 "level 2" 3 "level 3" 4 "Reserved" 5 "Reserved" 6 "Off" 7 "Invalid" ;
VAL_ 2441372929 DATC_Beep1Sound 0 "Beep1 mode Off" 1 "Beep1 mode On" 2 "Unused" 3 "Invalid" ;
VAL_ 2328014849 DATC_FrontPwmIsVolt 255 "Error Indicator" ;
VAL_ 2328014849 DATC_FrontBlwDuty 255 "Error Indicator" ;
VAL_ 2328014849 DATC_FrontBlwDiagStat 0 "Default" 1 "Normal State" 2 "Blower Motor Stall" 3 "Reserved" 4 "Reserved" 5 "Reserved" 6 "Reserved" 7 "Error Indicator" ;
VAL_ 2328014849 DATC_BlwrLvl_Ps 0 "OFF" 1 "0 Level" 2 "1 Level" 3 "2 Level" 4 "3 Level" 5 "4 Level" 6 "5 Level" 7 "6 Level" 8 "7 Level" 9 "8 Level" 10 "Reserved" 11 "Reserved" 12 "Reserved" 13 "Reserved" 14 "Reserved" 15 "Error Indicator" ;
VAL_ 2328014849 DATC_BlwrLvl_Rr 0 "OFF" 1 "0 level" 2 "1 level" 3 "2 level" 4 "3 level" 5 "4 level" 6 "5 level" 7 "6 level" 8 "7 evel" 9 "8 level" 10 "Reserved" 11 "Reserved" 12 "Reserved" 13 "Reserved" 14 "Reserved" 15 "Error Indicator" ;
VAL_ 2328014849 DATC_FnDstSnsrVal 508 "Sensor Off" 509 "Sensor Initializing" 510 "Sensor Fail" 511 "Error Indicator" ;
VAL_ 2328014850 DATC_FnDstStp 0 "Default" 1 "Good" 2 "Normal" 3 "Poor" 4 "Very Poor" 5 "Reserved" 6 "Reserved" 7 "Error Indicator" ;
VAL_ 2328014850 DATC_HDPDfg_Sta 0 "Default" 1 "Defog Deactivate for HDP" 2 "Defog Activate for HDP" 3 "Error Indicator" ;
VAL_ 2328014850 DATC_HDPHumidity_Sta 0 "Default" 1 "Not Need Defog for HDP" 2 "Need Defog for HDP" 3 "Error Indicator" ;
VAL_ 2328014850 DATC_FnDstStp_Detail 0 "Default" 1 "Good_0" 2 "Good_1" 3 "Good_2" 4 "Good_3" 5 "Good_4" 6 "Normal_1" 7 "Normal_2" 8 "Normal_3" 9 "Normal_4" 10 "Poor_1" 11 "Poor_2" 12 "Poor_3" 13 "Poor_4" 14 "Very Poor_1" 15 "Very Poor_2" 16 "Very Poor_3" 17 "Very Poor_4" 18 "Reserved" 19 "Reserved" 20 "Reserved" 21 "Reserved" 22 "Reserved" 23 "Reserved" 24 "Reserved" 25 "Reserved" 26 "Reserved" 27 "Reserved" 28 "Sensor Off" 29 "Sensor Initializing" 30 "Sensor Fail" 31 "Error Indicator" ;
VAL_ 2563125249 AMP_Beep2Mode 0 "Beep2Mode Off" 1 "Beep2Mode On" 2 "Unused" 3 "Invalid" ;
VAL_ 2563125249 AMP_Beep1Mode 0 "Beep1 mode off" 1 "Beep1 mode On" 2 "Unsed" 3 "Invalid" ;
VAL_ 2563125249 AMP_MasterBeepVolumeStep 0 "Invalid" 1 "level 1" 2 "level 2" 3 "level 3" 4 "level 4" 5 "level 5" 6 "Invalid" 7 "Invalid" ;
VAL_ 2563125249 AMP_RrTTSSound 0 "RrTTS Off" 1 "RrTTS ON" 2 "Unused" 3 "Invalid" ;
VAL_ 2563125249 AMP_ASDMode 0 "Not use" 1 "ASD OFF" 2 "Reserved" 3 "ASD ON" 4 "Reserved" 5 "Reserved" 6 "Reserved" 7 "Invalid" ;
VAL_ 2563125249 AMP_ANCMode 0 "Not used" 1 "ANC Off" 2 "ANC On" 3 "Invalid" ;
VAL_ 2563125249 AMP_VirtualVenueMode 0 "Off" 1 "Livingroom" 2 "ConcertHall" 3 "Stadium" 4 "Reserved" 5 "Reserved" 6 "Reserved" 7 "Invalid" ;
VAL_ 2563125249 AMP_QLIMode 0 "Off" 1 "Reference" 2 "Audience" 3 "OnStage" 4 "Reserved" 5 "Reserved" 6 "Reserved" 7 "Invalid" ;
VAL_ 2563125249 AMP_DriverMode 0 "Off" 1 "On" 2 "Reserved" 3 "Invalid" ;
VAL_ 2563125249 AMP_NaviSound 0 "Navi Off" 1 "Navi ON" 2 "Unused" 3 "Invalid" ;
VAL_ 2563125249 AMP_VESSMixing 0 "Off" 1 "On" 2 "Reserved" 3 "Invalid" ;
VAL_ 2563125249 AMP_VESSMusicOut 0 "Off" 1 "On" 2 "Reserved" 3 "Invalid" ;
VAL_ 2563125249 AMP_VoiceGuideTTS 0 "Off" 1 "On" 2 "Reserved" 3 "Invalid" ;
VAL_ 2563125249 AMP_Beep1KBDMode 0 "Beep1 mode off" 1 "Beep1 mode On" 2 "Unsed" 3 "Invalid" ;
VAL_ 2563125249 AMP_VoiceGuideTTSLevel 0 "Default" 1 "Level1" 2 "Level2" 3 "Level3" 4 "Reserved" 5 "Reserved" 6 "Reserved" 7 "Invalid" ;
VAL_ 2563125249 AMP_ALTPopUpReq 0 "Close" 1 "PopUp" 2 "Reserved" 3 "Invalid" ;
VAL_ 2563125249 AMP_TTSSound 0 "TTS Off" 1 "TTS ON" 2 "Unused" 3 "Invalid" ;
VAL_ 2563125249 AMP_SDVCStep 0 "off" 1 "low" 2 "mid" 3 "high" 7 "Invalid" ;
VAL_ 2563125761 AMP_LogSnapshot 0 "Reserved" 1 "Log Snapshot" 2 "Reserved" 3 "Invalid" ;
VAL_ 2563125761 AMP_VersionReq 0 "Off" 1 "Version request" 2 "Reservd" 3 "Invalid" ;
VAL_ 2458167553 C_PTGMNValueSet 0 "Default" 1 "Power Mode" 2 "Manual Mode" 3 "Invalid" ;
VAL_ 2458167553 CF_AVN_PSMNValueSet 0 "Default" 1 "Off(Disable)" 2 "50mm On(Enable)" 3 "75mm On(Enable)" 4 "Reserved" 5 "Reserved" 6 "Reserved" 7 "Invalid" ;
VAL_ 2458167553 C_HfreeTrunkTgNValueSet 0 "Default" 1 "HandsFree Off" 2 "HandsFree On" 3 "Reserved" 4 "Invalid" 5 "Reserved" 6 "Reserved" 7 "Reserved" ;
VAL_ 2458167553 CF_AVN_TrfChgSet 0 "Default" 1 "Disable(Off)" 2 "Enable(On)" 3 "Invalid" ;
VAL_ 2458167553 CF_AVN_SCMNValueSet 0 "Default" 1 "Steering Off" 2 "Steering On" 3 "Invalid" ;
VAL_ 2458167553 CF_AVN_ADrUNValueSet 0 "Default" 1 "Off" 2 "Key Out On(All Doors)" 3 "Shift Lever On(All Doors)" 4 "Override" 5 "Invalid" 6 "Key Out On(Driver Door)" 7 "Shift Lever On(Driver Door)" ;
VAL_ 2458167553 CF_AVN_OTTurnNValueSet 0 "Default" 1 "One Touch Turn Off" 2 "3 Flashing" 3 "5 Flashing" 4 "7 Flashing" 5 "Invalid" 6 "Reserved" 7 "Reserved" ;
VAL_ 2458167553 CF_Gway_WPCNValueSet 0 "Default" 1 "Off(Disable)" 2 "On(Enable)" 3 "Invalid" ;
VAL_ 2458167553 C_AVN_RearWiperNValueSet 0 "Default" 1 "Rear Wiper(Reverse) Off" 2 "Rear Wiper(Reverse) On" 3 "Invalid" ;
VAL_ 2458167553 C_UnlockWelocomeNValueSet 0 "Default" 1 "Off" 2 "On" 3 "Invalid" ;
VAL_ 2458167553 C_SmartWelocomeNValueSet 0 "Default" 1 "Off" 2 "On" 3 "Invalid" ;
VAL_ 2458167553 CF_AVN_PTGSpeedNValueSet 0 "Default" 1 "Fast" 2 "Slow" 3 "Invalid" ;
VAL_ 2458167553 CR_Datc_DRSeatWheel_USM_Set 0 "Default" 1 "Off" 2 "On" 3 "Invalid" ;
VAL_ 2458167553 CF_AVN_SequencialLampNValue 0 "Default" 1 "Off" 2 "On" 3 "Invalid" ;
VAL_ 2458167553 CF_AVN_TTUnlockNValueSet 0 "Default" 1 "Off" 2 "On" 3 "Invalid" ;
VAL_ 2458167553 CF_Gway_RWPCNValueSet 0 "Default" 1 "Off" 2 "On" 3 "Invalid" ;
VAL_ 2458167553 CF_Avn_BolsterNValueSet 0 "Default" 1 "Off" 2 "On" 3 "Invalid" ;
VAL_ 2458167553 C_PSDNValueSet 0 "Default" 1 "Power Mode" 2 "Manual Mode" 3 "Invalid" ;
VAL_ 2458167553 C_StrWheelAutoHeatNValueSet 0 "Default" 1 "Off" 2 "On" 3 "Invalid" ;
VAL_ 2458167553 CF_Avn_HAPTICWARNINGNValueSet 0 "Default" 1 "Weak" 2 "Medium" 3 "Strong" 4 "Reserved" 5 "Reserved" 6 "Off" 7 "Invalid" ;
VAL_ 2458167553 CF_AVN_ADrLNValueSet 0 "Default" 1 "Off" 2 "Vehicle Speed On(15km)" 3 "Shift Lever On" 4 "Invalid" 5 "Reserved" 6 "Reserved" 7 "Reserved" ;
VAL_ 2458167553 CR_Datc_DRSeatHeat_USM_Set 0 "Default" 1 "Off" 2 "On" 3 "Invalid" ;
VAL_ 2458167553 C_WALNValueSet 0 "Default" 1 "Off" 2 "On" 3 "Invalid" ;
VAL_ 2458167553 C_ApprUnlockNValue 0 "Defualt" 1 "Approach Unlock OFF" 2 "Approach Unlock ON" 3 "Invalid" ;
VAL_ 2458167553 CF_AVN_SEW_NEWNValueSet 0 "Default" 1 "Off" 2 "On(Warning)" 3 "Invalid" ;
VAL_ 2458167553 CF_AVN_SEA_NEWNValueSet 0 "Default" 1 "Off" 2 "On(Assist)" 3 "Invalid" ;
VAL_ 2458167553 CF_AVN_TunnelWindowNvalueSet 0 "Default" 1 "Off" 2 "On" 3 "Invalid" ;
VAL_ 2458167553 CF_AVN_EscortHLNValueSet 0 "Default" 1 "Escort Off" 2 "Escort On" 3 "Invalid" ;
VAL_ 961 Lamp_HdLmpHiSwSta 0 "Off" 1 "On" 2 "Not Used" 3 "Error Indicator" ;
VAL_ 961 Lamp_LtSwSta 0 "Light Sw Off" 1 "Tail Sw On" 2 "HeadLamp Low Sw On" 3 "AutoLight Sw On" ;
VAL_ 961 Lamp_PassingLmpSwSta 0 "Off" 1 "On" 2 "Not Used" 3 "Error Indicator" ;
VAL_ 961 Lamp_RrFogLmpSwSta 0 "Off" 1 "On" 2 "Not Used" 3 "Error Indicator" ;
VAL_ 961 Lamp_TrnSigLftSwSta 0 "Off" 1 "On" 2 "Not Used" 3 "Error Indicator" ;
VAL_ 961 Lamp_TrnSigRtSwSta 0 "Off" 1 "On" 2 "Not Used" 3 "Error Indicator" ;
VAL_ 961 Lamp_LaneChgTrnSigLftSwSta 0 "Off" 1 "On" 2 "Not Used" 3 "Error Indicator" ;
VAL_ 961 Lamp_LaneChgTrnSigRtSwSta 0 "Off" 1 "On" 2 "Not Used" 3 "Error Indicator" ;
VAL_ 1369 NMCommandCode_DSAU 1 "Alive" 2 "Ring" 4 "Limphome" ;
VAL_ 1369 NMSleepFlag_DSAU 0 "Alive" 1 "SleepInd" 3 "SleepAck" ;
VAL_ 1323 NMCommandCode_SHVU_RR 1 "Alive" 2 "Ring" 4 "Limphome" ;
VAL_ 1323 NMSleepFlag_SHVU_RR 0 "Alive" 1 "SleepInd" 3 "SleepAck" ;
VAL_ 1337 NMCommandCode_DPSS 1 "Alive" 2 "Ring" 4 "Limphome" ;
VAL_ 1337 NMSleepFlag_DPSS 0 "Alive" 1 "SleepInd" 3 "SleepAck" ;
VAL_ 1376 NMCommandCode_AMP 1 "Alive" 2 "Ring" 4 "Limphome" ;
VAL_ 1376 NMSleepFlag_AMP 0 "Alive" 1 "SleepInd" 3 "SleepAck" ;
VAL_ 1367 NMCommandCode_ICC 1 "Alive" 2 "Ring" 4 "Limphome" ;
VAL_ 1367 NMSleepFlag_ICC 0 "Alive" 1 "SleepInd" 3 "SleepAck" ;
VAL_ 1308 NMCommandCode_RLPSM 1 "Alive" 2 "Ring" 4 "Limphome" ;
VAL_ 1308 NMSleepFlag_RLPSM 0 "Alive" 1 "SleepInd" 3 "SleepAck" ;
VAL_ 1289 NMCommandCode_APSM 1 "Alive" 2 "Ring" 4 "Limphome" ;
VAL_ 1289 NMSleepFlag_APSM 0 "Alive" 1 "SleepInd" 3 "SleepAck" ;
VAL_ 1311 NMCommandCode_RWPC 1 "Alive" 2 "Ring" 4 "Limphome" ;
VAL_ 1311 NMSleepFlag_RWPC 0 "Alive" 1 "SleepInd" 3 "SleepAck" ;
VAL_ 1333 NMCommandCode_RRHV 1 "Alive" 2 "Ring" 4 "Limphome" ;
VAL_ 1333 NMSleepFlag_RRHV 0 "Alive" 1 "SleepInd" 3 "SleepAck" ;
VAL_ 1309 NMCommandCode_RRPSM 1 "Alive" 2 "Ring" 4 "Limphome" ;
VAL_ 1309 NMSleepFlag_RRPSM 0 "Alive" 1 "SleepInd" 3 "SleepAck" ;
VAL_ 1392 NMCommandCode_CGW_CCU 1 "Alive" 2 "Ring" 4 "Limphome" ;
VAL_ 1392 NMSleepFlag_CGW_CCU 0 "Alive" 1 "SleepInd" 3 "SleepAck" ;
VAL_ 1346 NMCommandCode_APSS 1 "Alive" 2 "Ring" 4 "Limphome" ;
VAL_ 1346 NMSleepFlag_APSS 0 "Alive" 1 "SleepInd" 3 "SleepAck" ;
VAL_ 1360 NMCommandCode_ATS 1 "Alive" 2 "Ring" 4 "Limphome" ;
VAL_ 1360 NMSleepFlag_ATS 0 "Alive" 1 "SleepInd" 3 "SleepAck" ;
VAL_ 1332 NMCommandCode_RLHV 1 "Alive" 2 "Ring" 4 "Limphome" ;
VAL_ 1332 NMSleepFlag_RLHV 0 "Alive" 1 "SleepInd" 3 "SleepAck" ;
VAL_ 1359 NMCommandCode_FPM 1 "Alive" 2 "Ring" 4 "Limphome" ;
VAL_ 1359 NMSleepFlag_FPM 0 "Alive" 1 "SleepInd" 3 "SleepAck" ;
VAL_ 1327 NMCommandCode_RDC 1 "Alive" 2 "Ring" 4 "Limphome" ;
VAL_ 1327 NMSleepFlag_RDC 0 "Alive" 1 "SleepInd" 3 "SleepAck" ;
VAL_ 1286 NMCommandCode_PSM 1 "Alive" 2 "Ring" 4 "Limphome" ;
VAL_ 1286 NMSleepFlag_PSM 0 "Alive" 1 "SleepInd" 3 "SleepAck" ;
VAL_ 1363 NMCommandCode_ASAU 1 "Alive" 2 "Ring" 4 "Limphome" ;
VAL_ 1363 NMSleepFlag_ASAU 0 "Alive" 1 "SleepInd" 3 "SleepAck" ;
